VERSION ""

NS_ :

BS_:

BU_: LED_Driver ISC

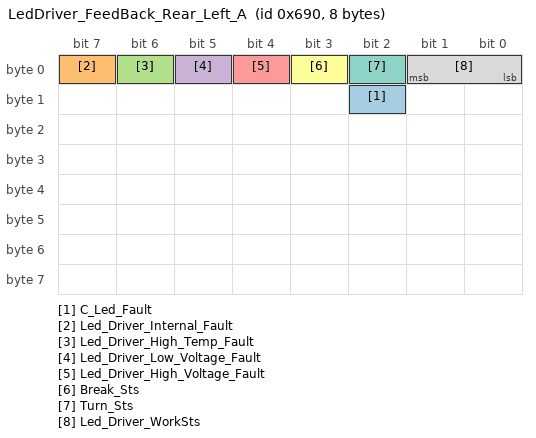
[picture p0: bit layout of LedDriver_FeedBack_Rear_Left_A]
BO_ 1680 LedDriver_FeedBack_Rear_Left_A: 8 LED_Driver
 SG_ C_Led_Fault : 10|1@1+ (1,0) [0|1] "" Vector__XXX
 SG_ Led_Driver_Internal_Fault : 7|1@1+ (1,0) [0|1] "" Vector__XXX
 SG_ Led_Driver_High_Temp_Fault : 6|1@1+ (1,0) [0|1] "" Vector__XXX
 SG_ Led_Driver_Low_Voltage_Fault : 5|1@1+ (1,0) [0|1] "" Vector__XXX
 SG_ Led_Driver_High_Voltage_Fault : 4|1@1+ (1,0) [0|1] "" Vector__XXX
 SG_ Break_Sts : 3|1@1+ (1,0) [0|1] "" Vector__XXX
 SG_ Turn_Sts : 2|1@1+ (1,0) [0|1] "" Vector__XXX
 SG_ Led_Driver_WorkSts : 0|2@1+ (1,0) [0|3] "" Vector__XXX

BO_ 1285 ISC_Ctrl_Right_LED_A_05: 64 ISC
 SG_ Led0043_value : 336|8@1+ (1,0) [0|255] "" Vector__XXX
 SG_ Led0042_value : 328|8@1+ (1,0) [0|255] "" Vector__XXX
 SG_ Led0041_value : 320|8@1+ (1,0) [0|255] "" Vector__XXX
 SG_ Led0040_value : 312|8@1+ (1,0) [0|255] "" Vector__XXX
 SG_ Led0039_value : 304|8@1+ (1,0) [0|255] "" Vector__XXX
 SG_ Led0038_value : 296|8@1+ (1,0) [0|255] "" Vector__XXX
 SG_ Led0037_value : 288|8@1+ (1,0) [0|255] "" Vector__XXX
 SG_ Led0036_value : 280|8@1+ (1,0) [0|255] "" Vector__XXX
 SG_ Led0035_value : 272|8@1+ (1,0) [0|255] "" Vector__XXX
 SG_ Led0034_value : 264|8@1+ (1,0) [0|255] "" Vector__XXX
 SG_ Led0033_value : 256|8@1+ (1,0) [0|255] "" Vector__XXX
 SG_ Led0032_value : 248|8@1+ (1,0) [0|255] "" Vector__XXX
 SG_ Led0031_value : 240|8@1+ (1,0) [0|255] "" Vector__XXX
 SG_ Led0030_value : 232|8@1+ (1,0) [0|255] "" Vector__XXX
 SG_ Led0029_value : 224|8@1+ (1,0) [0|255] "" Vector__XXX
 SG_ Led0028_value : 216|8@1+ (1,0) [0|255] "" Vector__XXX
 SG_ Led0027_value : 208|8@1+ (1,0) [0|255] "" Vector__XXX
 SG_ Led0026_value : 200|8@1+ (1,0) [0|255] "" Vector__XXX
 SG_ Led0025_value : 192|8@1+ (1,0) [0|255] "" Vector__XXX
 SG_ Led0024_value : 184|8@1+ (1,0) [0|255] "" Vector__XXX
 SG_ Led0023_value : 176|8@1+ (1,0) [0|255] "" Vector__XXX
 SG_ Led0022_value : 168|8@1+ (1,0) [0|255] "" Vector__XXX
 SG_ Led0021_value : 160|8@1+ (1,0) [0|255] "" Vector__XXX
 SG_ Led0020_value : 152|8@1+ (1,0) [0|255] "" Vector__XXX
 SG_ Led0019_value : 144|8@1+ (1,0) [0|255] "" Vector__XXX
 SG_ Led0018_value : 136|8@1+ (1,0) [0|255] "" Vector__XXX
 SG_ Led0017_value : 128|8@1+ (1,0) [0|255] "" Vector__XXX
 SG_ Led0016_value : 120|8@1+ (1,0) [0|255] "" Vector__XXX
 SG_ Led0015_value : 112|8@1+ (1,0) [0|255] "" Vector__XXX
 SG_ Led0014_value : 104|8@1+ (1,0) [0|255] "" Vector__XXX
 SG_ Led0013_value : 96|8@1+ (1,0) [0|255] "" Vector__XXX
 SG_ Led0012_value : 88|8@1+ (1,0) [0|255] "" Vector__XXX
 SG_ Led0011_value : 80|8@1+ (1,0) [0|255] "" Vector__XXX
 SG_ Led0010_value : 72|8@1+ (1,0) [0|255] "" Vector__XXX
 SG_ Led0009_value : 64|8@1+ (1,0) [0|255] "" Vector__XXX
 SG_ Led0008_value : 56|8@1+ (1,0) [0|255] "" Vector__XXX
 SG_ Led0007_value : 48|8@1+ (1,0) [0|255] "" Vector__XXX
 SG_ Led0006_value : 40|8@1+ (1,0) [0|255] "" Vector__XXX
 SG_ Led0005_value : 32|8@1+ (1,0) [0|255] "" Vector__XXX
 SG_ Led0004_value : 24|8@1+ (1,0) [0|255] "" Vector__XXX
 SG_ Led0003_value : 16|8@1+ (1,0) [0|255] "" Vector__XXX
 SG_ Led0002_value : 8|8@1+ (1,0) [0|255] "" Vector__XXX
 SG_ Led0001_value : 0|8@1+ (1,0) [0|255] "" Vector__XXX

BO_ 1284 ISC_Ctrl_Right_LED_A_04: 64 ISC
 SG_ Led0064_value : 504|8@1+ (1,0) [0|255] "" Vector__XXX
 SG_ Led0063_value : 496|8@1+ (1,0) [0|255] "" Vector__XXX
 SG_ Led0062_value : 488|8@1+ (1,0) [0|255] "" Vector__XXX
 SG_ Led0061_value : 480|8@1+ (1,0) [0|255] "" Vector__XXX
 SG_ Led0060_value : 472|8@1+ (1,0) [0|255] "" Vector__XXX
 SG_ Led0059_value : 464|8@1+ (1,0) [0|255] "" Vector__XXX
 SG_ Led0058_value : 456|8@1+ (1,0) [0|255] "" Vector__XXX
 SG_ Led0057_value : 448|8@1+ (1,0) [0|255] "" Vector__XXX
 SG_ Led0056_value : 440|8@1+ (1,0) [0|255] "" Vector__XXX
 SG_ Led0055_value : 432|8@1+ (1,0) [0|255] "" Vector__XXX
 SG_ Led0054_value : 424|8@1+ (1,0) [0|255] "" Vector__XXX
 SG_ Led0053_value : 416|8@1+ (1,0) [0|255] "" Vector__XXX
 SG_ Led0052_value : 408|8@1+ (1,0) [0|255] "" Vector__XXX
 SG_ Led0051_value : 400|8@1+ (1,0) [0|255] "" Vector__XXX
 SG_ Led0050_value : 392|8@1+ (1,0) [0|255] "" Vector__XXX
 SG_ Led0049_value : 384|8@1+ (1,0) [0|255] "" Vector__XXX
 SG_ Led0048_value : 376|8@1+ (1,0) [0|255] "" Vector__XXX
 SG_ Led0047_value : 368|8@1+ (1,0) [0|255] "" Vector__XXX
 SG_ Led0046_value : 360|8@1+ (1,0) [0|255] "" Vector__XXX
 SG_ Led0045_value : 352|8@1+ (1,0) [0|255] "" Vector__XXX
 SG_ Led0044_value : 344|8@1+ (1,0) [0|255] "" Vector__XXX
 SG_ Led0043_value : 336|8@1+ (1,0) [0|255] "" Vector__XXX
 SG_ Led0042_value : 328|8@1+ (1,0) [0|255] "" Vector__XXX
 SG_ Led0041_value : 320|8@1+ (1,0) [0|255] "" Vector__XXX
 SG_ Led0040_value : 312|8@1+ (1,0) [0|255] "" Vector__XXX
 SG_ Led0039_value : 304|8@1+ (1,0) [0|255] "" Vector__XXX
 SG_ Led0038_value : 296|8@1+ (1,0) [0|255] "" Vector__XXX
 SG_ Led0037_value : 288|8@1+ (1,0) [0|255] "" Vector__XXX
 SG_ Led0036_value : 280|8@1+ (1,0) [0|255] "" Vector__XXX
 SG_ Led0035_value : 272|8@1+ (1,0) [0|255] "" Vector__XXX
 SG_ Led0034_value : 264|8@1+ (1,0) [0|255] "" Vector__XXX
 SG_ Led0033_value : 256|8@1+ (1,0) [0|255] "" Vector__XXX
 SG_ Led0032_value : 248|8@1+ (1,0) [0|255] "" Vector__XXX
 SG_ Led0031_value : 240|8@1+ (1,0) [0|255] "" Vector__XXX
 SG_ Led0030_value : 232|8@1+ (1,0) [0|255] "" Vector__XXX
 SG_ Led0029_value : 224|8@1+ (1,0) [0|255] "" Vector__XXX
 SG_ Led0028_value : 216|8@1+ (1,0) [0|255] "" Vector__XXX
 SG_ Led0027_value : 208|8@1+ (1,0) [0|255] "" Vector__XXX
 SG_ Led0026_value : 200|8@1+ (1,0) [0|255] "" Vector__XXX
 SG_ Led0025_value : 192|8@1+ (1,0) [0|255] "" Vector__XXX
 SG_ Led0024_value : 184|8@1+ (1,0) [0|255] "" Vector__XXX
 SG_ Led0023_value : 176|8@1+ (1,0) [0|255] "" Vector__XXX
 SG_ Led0022_value : 168|8@1+ (1,0) [0|255] "" Vector__XXX
 SG_ Led0021_value : 160|8@1+ (1,0) [0|255] "" Vector__XXX
 SG_ Led0020_value : 152|8@1+ (1,0) [0|255] "" Vector__XXX
 SG_ Led0019_value : 144|8@1+ (1,0) [0|255] "" Vector__XXX
 SG_ Led0018_value : 136|8@1+ (1,0) [0|255] "" Vector__XXX
 SG_ Led0017_value : 128|8@1+ (1,0) [0|255] "" Vector__XXX
 SG_ Led0016_value : 120|8@1+ (1,0) [0|255] "" Vector__XXX
 SG_ Led0015_value : 112|8@1+ (1,0) [0|255] "" Vector__XXX
 SG_ Led0014_value : 104|8@1+ (1,0) [0|255] "" Vector__XXX
 SG_ Led0013_value : 96|8@1+ (1,0) [0|255] "" Vector__XXX
 SG_ Led0012_value : 88|8@1+ (1,0) [0|255] "" Vector__XXX
 SG_ Led0011_value : 80|8@1+ (1,0) [0|255] "" Vector__XXX
 SG_ Led0010_value : 72|8@1+ (1,0) [0|255] "" Vector__XXX
 SG_ Led0009_value : 64|8@1+ (1,0) [0|255] "" Vector__XXX
 SG_ Led0008_value : 56|8@1+ (1,0) [0|255] "" Vector__XXX
 SG_ Led0007_value : 48|8@1+ (1,0) [0|255] "" Vector__XXX
 SG_ Led0006_value : 40|8@1+ (1,0) [0|255] "" Vector__XXX
 SG_ Led0005_value : 32|8@1+ (1,0) [0|255] "" Vector__XXX
 SG_ Led0004_value : 24|8@1+ (1,0) [0|255] "" Vector__XXX
 SG_ Led0003_value : 16|8@1+ (1,0) [0|255] "" Vector__XXX
 SG_ Led0002_value : 8|8@1+ (1,0) [0|255] "" Vector__XXX
 SG_ Led0001_value : 0|8@1+ (1,0) [0|255] "" Vector__XXX

BO_ 1283 ISC_Ctrl_Right_LED_A_03: 64 ISC
 SG_ Led0064_value : 504|8@1+ (1,0) [0|255] "" Vector__XXX
 SG_ Led0063_value : 496|8@1+ (1,0) [0|255] "" Vector__XXX
 SG_ Led0062_value : 488|8@1+ (1,0) [0|255] "" Vector__XXX
 SG_ Led0061_value : 480|8@1+ (1,0) [0|255] "" Vector__XXX
 SG_ Led0060_value : 472|8@1+ (1,0) [0|255] "" Vector__XXX
 SG_ Led0059_value : 464|8@1+ (1,0) [0|255] "" Vector__XXX
 SG_ Led0058_value : 456|8@1+ (1,0) [0|255] "" Vector__XXX
 SG_ Led0057_value : 448|8@1+ (1,0) [0|255] "" Vector__XXX
 SG_ Led0056_value : 440|8@1+ (1,0) [0|255] "" Vector__XXX
 SG_ Led0055_value : 432|8@1+ (1,0) [0|255] "" Vector__XXX
 SG_ Led0054_value : 424|8@1+ (1,0) [0|255] "" Vector__XXX
 SG_ Led0053_value : 416|8@1+ (1,0) [0|255] "" Vector__XXX
 SG_ Led0052_value : 408|8@1+ (1,0) [0|255] "" Vector__XXX
 SG_ Led0051_value : 400|8@1+ (1,0) [0|255] "" Vector__XXX
 SG_ Led0050_value : 392|8@1+ (1,0) [0|255] "" Vector__XXX
 SG_ Led0049_value : 384|8@1+ (1,0) [0|255] "" Vector__XXX
 SG_ Led0048_value : 376|8@1+ (1,0) [0|255] "" Vector__XXX
 SG_ Led0047_value : 368|8@1+ (1,0) [0|255] "" Vector__XXX
 SG_ Led0046_value : 360|8@1+ (1,0) [0|255] "" Vector__XXX
 SG_ Led0045_value : 352|8@1+ (1,0) [0|255] "" Vector__XXX
 SG_ Led0044_value : 344|8@1+ (1,0) [0|255] "" Vector__XXX
 SG_ Led0043_value : 336|8@1+ (1,0) [0|255] "" Vector__XXX
 SG_ Led0042_value : 328|8@1+ (1,0) [0|255] "" Vector__XXX
 SG_ Led0041_value : 320|8@1+ (1,0) [0|255] "" Vector__XXX
 SG_ Led0040_value : 312|8@1+ (1,0) [0|255] "" Vector__XXX
 SG_ Led0039_value : 304|8@1+ (1,0) [0|255] "" Vector__XXX
 SG_ Led0038_value : 296|8@1+ (1,0) [0|255] "" Vector__XXX
 SG_ Led0037_value : 288|8@1+ (1,0) [0|255] "" Vector__XXX
 SG_ Led0036_value : 280|8@1+ (1,0) [0|255] "" Vector__XXX
 SG_ Led0035_value : 272|8@1+ (1,0) [0|255] "" Vector__XXX
 SG_ Led0034_value : 264|8@1+ (1,0) [0|255] "" Vector__XXX
 SG_ Led0033_value : 256|8@1+ (1,0) [0|255] "" Vector__XXX
 SG_ Led0032_value : 248|8@1+ (1,0) [0|255] "" Vector__XXX
 SG_ Led0031_value : 240|8@1+ (1,0) [0|255] "" Vector__XXX
 SG_ Led0030_value : 232|8@1+ (1,0) [0|255] "" Vector__XXX
 SG_ Led0029_value : 224|8@1+ (1,0) [0|255] "" Vector__XXX
 SG_ Led0028_value : 216|8@1+ (1,0) [0|255] "" Vector__XXX
 SG_ Led0027_value : 208|8@1+ (1,0) [0|255] "" Vector__XXX
 SG_ Led0026_value : 200|8@1+ (1,0) [0|255] "" Vector__XXX
 SG_ Led0025_value : 192|8@1+ (1,0) [0|255] "" Vector__XXX
 SG_ Led0024_value : 184|8@1+ (1,0) [0|255] "" Vector__XXX
 SG_ Led0023_value : 176|8@1+ (1,0) [0|255] "" Vector__XXX
 SG_ Led0022_value : 168|8@1+ (1,0) [0|255] "" Vector__XXX
 SG_ Led0021_value : 160|8@1+ (1,0) [0|255] "" Vector__XXX
 SG_ Led0020_value : 152|8@1+ (1,0) [0|255] "" Vector__XXX
 SG_ Led0019_value : 144|8@1+ (1,0) [0|255] "" Vector__XXX
 SG_ Led0018_value : 136|8@1+ (1,0) [0|255] "" Vector__XXX
 SG_ Led0017_value : 128|8@1+ (1,0) [0|255] "" Vector__XXX
 SG_ Led0016_value : 120|8@1+ (1,0) [0|255] "" Vector__XXX
 SG_ Led0015_value : 112|8@1+ (1,0) [0|255] "" Vector__XXX
 SG_ Led0014_value : 104|8@1+ (1,0) [0|255] "" Vector__XXX
 SG_ Led0013_value : 96|8@1+ (1,0) [0|255] "" Vector__XXX
 SG_ Led0012_value : 88|8@1+ (1,0) [0|255] "" Vector__XXX
 SG_ Led0011_value : 80|8@1+ (1,0) [0|255] "" Vector__XXX
 SG_ Led0010_value : 72|8@1+ (1,0) [0|255] "" Vector__XXX
 SG_ Led0009_value : 64|8@1+ (1,0) [0|255] "" Vector__XXX
 SG_ Led0008_value : 56|8@1+ (1,0) [0|255] "" Vector__XXX
 SG_ Led0007_value : 48|8@1+ (1,0) [0|255] "" Vector__XXX
 SG_ Led0006_value : 40|8@1+ (1,0) [0|255] "" Vector__XXX
 SG_ Led0005_value : 32|8@1+ (1,0) [0|255] "" Vector__XXX
 SG_ Led0004_value : 24|8@1+ (1,0) [0|255] "" Vector__XXX
 SG_ Led0003_value : 16|8@1+ (1,0) [0|255] "" Vector__XXX
 SG_ Led0002_value : 8|8@1+ (1,0) [0|255] "" Vector__XXX
 SG_ Led0001_value : 0|8@1+ (1,0) [0|255] "" Vector__XXX

BO_ 1282 ISC_Ctrl_Right_LED_A_02: 64 ISC
 SG_ Led0064_value : 504|8@1+ (1,0) [0|255] "" Vector__XXX
 SG_ Led0063_value : 496|8@1+ (1,0) [0|255] "" Vector__XXX
 SG_ Led0062_value : 488|8@1+ (1,0) [0|255] "" Vector__XXX
 SG_ Led0061_value : 480|8@1+ (1,0) [0|255] "" Vector__XXX
 SG_ Led0060_value : 472|8@1+ (1,0) [0|255] "" Vector__XXX
 SG_ Led0059_value : 464|8@1+ (1,0) [0|255] "" Vector__XXX
 SG_ Led0058_value : 456|8@1+ (1,0) [0|255] "" Vector__XXX
 SG_ Led0057_value : 448|8@1+ (1,0) [0|255] "" Vector__XXX
 SG_ Led0056_value : 440|8@1+ (1,0) [0|255] "" Vector__XXX
 SG_ Led0055_value : 432|8@1+ (1,0) [0|255] "" Vector__XXX
 SG_ Led0054_value : 424|8@1+ (1,0) [0|255] "" Vector__XXX
 SG_ Led0053_value : 416|8@1+ (1,0) [0|255] "" Vector__XXX
 SG_ Led0052_value : 408|8@1+ (1,0) [0|255] "" Vector__XXX
 SG_ Led0051_value : 400|8@1+ (1,0) [0|255] "" Vector__XXX
 SG_ Led0050_value : 392|8@1+ (1,0) [0|255] "" Vector__XXX
 SG_ Led0049_value : 384|8@1+ (1,0) [0|255] "" Vector__XXX
 SG_ Led0048_value : 376|8@1+ (1,0) [0|255] "" Vector__XXX
 SG_ Led0047_value : 368|8@1+ (1,0) [0|255] "" Vector__XXX
 SG_ Led0046_value : 360|8@1+ (1,0) [0|255] "" Vector__XXX
 SG_ Led0045_value : 352|8@1+ (1,0) [0|255] "" Vector__XXX
 SG_ Led0044_value : 344|8@1+ (1,0) [0|255] "" Vector__XXX
 SG_ Led0043_value : 336|8@1+ (1,0) [0|255] "" Vector__XXX
 SG_ Led0042_value : 328|8@1+ (1,0) [0|255] "" Vector__XXX
 SG_ Led0041_value : 320|8@1+ (1,0) [0|255] "" Vector__XXX
 SG_ Led0040_value : 312|8@1+ (1,0) [0|255] "" Vector__XXX
 SG_ Led0039_value : 304|8@1+ (1,0) [0|255] "" Vector__XXX
 SG_ Led0038_value : 296|8@1+ (1,0) [0|255] "" Vector__XXX
 SG_ Led0037_value : 288|8@1+ (1,0) [0|255] "" Vector__XXX
 SG_ Led0036_value : 280|8@1+ (1,0) [0|255] "" Vector__XXX
 SG_ Led0035_value : 272|8@1+ (1,0) [0|255] "" Vector__XXX
 SG_ Led0034_value : 264|8@1+ (1,0) [0|255] "" Vector__XXX
 SG_ Led0033_value : 256|8@1+ (1,0) [0|255] "" Vector__XXX
 SG_ Led0032_value : 248|8@1+ (1,0) [0|255] "" Vector__XXX
 SG_ Led0031_value : 240|8@1+ (1,0) [0|255] "" Vector__XXX
 SG_ Led0030_value : 232|8@1+ (1,0) [0|255] "" Vector__XXX
 SG_ Led0029_value : 224|8@1+ (1,0) [0|255] "" Vector__XXX
 SG_ Led0028_value : 216|8@1+ (1,0) [0|255] "" Vector__XXX
 SG_ Led0027_value : 208|8@1+ (1,0) [0|255] "" Vector__XXX
 SG_ Led0026_value : 200|8@1+ (1,0) [0|255] "" Vector__XXX
 SG_ Led0025_value : 192|8@1+ (1,0) [0|255] "" Vector__XXX
 SG_ Led0024_value : 184|8@1+ (1,0) [0|255] "" Vector__XXX
 SG_ Led0023_value : 176|8@1+ (1,0) [0|255] "" Vector__XXX
 SG_ Led0022_value : 168|8@1+ (1,0) [0|255] "" Vector__XXX
 SG_ Led0021_value : 160|8@1+ (1,0) [0|255] "" Vector__XXX
 SG_ Led0020_value : 152|8@1+ (1,0) [0|255] "" Vector__XXX
 SG_ Led0019_value : 144|8@1+ (1,0) [0|255] "" Vector__XXX
 SG_ Led0018_value : 136|8@1+ (1,0) [0|255] "" Vector__XXX
 SG_ Led0017_value : 128|8@1+ (1,0) [0|255] "" Vector__XXX
 SG_ Led0016_value : 120|8@1+ (1,0) [0|255] "" Vector__XXX
 SG_ Led0015_value : 112|8@1+ (1,0) [0|255] "" Vector__XXX
 SG_ Led0014_value : 104|8@1+ (1,0) [0|255] "" Vector__XXX
 SG_ Led0013_value : 96|8@1+ (1,0) [0|255] "" Vector__XXX
 SG_ Led0012_value : 88|8@1+ (1,0) [0|255] "" Vector__XXX
 SG_ Led0011_value : 80|8@1+ (1,0) [0|255] "" Vector__XXX
 SG_ Led0010_value : 72|8@1+ (1,0) [0|255] "" Vector__XXX
 SG_ Led0009_value : 64|8@1+ (1,0) [0|255] "" Vector__XXX
 SG_ Led0008_value : 56|8@1+ (1,0) [0|255] "" Vector__XXX
 SG_ Led0007_value : 48|8@1+ (1,0) [0|255] "" Vector__XXX
 SG_ Led0006_value : 40|8@1+ (1,0) [0|255] "" Vector__XXX
 SG_ Led0005_value : 32|8@1+ (1,0) [0|255] "" Vector__XXX
 SG_ Led0004_value : 24|8@1+ (1,0) [0|255] "" Vector__XXX
 SG_ Led0003_value : 16|8@1+ (1,0) [0|255] "" Vector__XXX
 SG_ Led0002_value : 8|8@1+ (1,0) [0|255] "" Vector__XXX
 SG_ Led0001_value : 0|8@1+ (1,0) [0|255] "" Vector__XXX

BO_ 1281 ISC_Ctrl_Right_LED_A_01: 64 ISC
 SG_ Led0064_value : 504|8@1+ (1,0) [0|255] "" Vector__XXX
 SG_ Led0063_value : 496|8@1+ (1,0) [0|255] "" Vector__XXX
 SG_ Led0062_value : 488|8@1+ (1,0) [0|255] "" Vector__XXX
 SG_ Led0061_value : 480|8@1+ (1,0) [0|255] "" Vector__XXX
 SG_ Led0060_value : 472|8@1+ (1,0) [0|255] "" Vector__XXX
 SG_ Led0059_value : 464|8@1+ (1,0) [0|255] "" Vector__XXX
 SG_ Led0058_value : 456|8@1+ (1,0) [0|255] "" Vector__XXX
 SG_ Led0057_value : 448|8@1+ (1,0) [0|255] "" Vector__XXX
 SG_ Led0056_value : 440|8@1+ (1,0) [0|255] "" Vector__XXX
 SG_ Led0055_value : 432|8@1+ (1,0) [0|255] "" Vector__XXX
 SG_ Led0054_value : 424|8@1+ (1,0) [0|255] "" Vector__XXX
 SG_ Led0053_value : 416|8@1+ (1,0) [0|255] "" Vector__XXX
 SG_ Led0052_value : 408|8@1+ (1,0) [0|255] "" Vector__XXX
 SG_ Led0051_value : 400|8@1+ (1,0) [0|255] "" Vector__XXX
 SG_ Led0050_value : 392|8@1+ (1,0) [0|255] "" Vector__XXX
 SG_ Led0049_value : 384|8@1+ (1,0) [0|255] "" Vector__XXX
 SG_ Led0048_value : 376|8@1+ (1,0) [0|255] "" Vector__XXX
 SG_ Led0047_value : 368|8@1+ (1,0) [0|255] "" Vector__XXX
 SG_ Led0046_value : 360|8@1+ (1,0) [0|255] "" Vector__XXX
 SG_ Led0045_value : 352|8@1+ (1,0) [0|255] "" Vector__XXX
 SG_ Led0044_value : 344|8@1+ (1,0) [0|255] "" Vector__XXX
 SG_ Led0043_value : 336|8@1+ (1,0) [0|255] "" Vector__XXX
 SG_ Led0042_value : 328|8@1+ (1,0) [0|255] "" Vector__XXX
 SG_ Led0041_value : 320|8@1+ (1,0) [0|255] "" Vector__XXX
 SG_ Led0040_value : 312|8@1+ (1,0) [0|255] "" Vector__XXX
 SG_ Led0039_value : 304|8@1+ (1,0) [0|255] "" Vector__XXX
 SG_ Led0038_value : 296|8@1+ (1,0) [0|255] "" Vector__XXX
 SG_ Led0037_value : 288|8@1+ (1,0) [0|255] "" Vector__XXX
 SG_ Led0036_value : 280|8@1+ (1,0) [0|255] "" Vector__XXX
 SG_ Led0035_value : 272|8@1+ (1,0) [0|255] "" Vector__XXX
 SG_ Led0034_value : 264|8@1+ (1,0) [0|255] "" Vector__XXX
 SG_ Led0033_value : 256|8@1+ (1,0) [0|255] "" Vector__XXX
 SG_ Led0032_value : 248|8@1+ (1,0) [0|255] "" Vector__XXX
 SG_ Led0031_value : 240|8@1+ (1,0) [0|255] "" Vector__XXX
 SG_ Led0030_value : 232|8@1+ (1,0) [0|255] "" Vector__XXX
 SG_ Led0029_value : 224|8@1+ (1,0) [0|255] "" Vector__XXX
 SG_ Led0028_value : 216|8@1+ (1,0) [0|255] "" Vector__XXX
 SG_ Led0027_value : 208|8@1+ (1,0) [0|255] "" Vector__XXX
 SG_ Led0026_value : 200|8@1+ (1,0) [0|255] "" Vector__XXX
 SG_ Led0025_value : 192|8@1+ (1,0) [0|255] "" Vector__XXX
 SG_ Led0024_value : 184|8@1+ (1,0) [0|255] "" Vector__XXX
 SG_ Led0023_value : 176|8@1+ (1,0) [0|255] "" Vector__XXX
 SG_ Led0022_value : 168|8@1+ (1,0) [0|255] "" Vector__XXX
 SG_ Led0021_value : 160|8@1+ (1,0) [0|255] "" Vector__XXX
 SG_ Led0020_value : 152|8@1+ (1,0) [0|255] "" Vector__XXX
 SG_ Led0019_value : 144|8@1+ (1,0) [0|255] "" Vector__XXX
 SG_ Led0018_value : 136|8@1+ (1,0) [0|255] "" Vector__XXX
 SG_ Led0017_value : 128|8@1+ (1,0) [0|255] "" Vector__XXX
 SG_ Led0016_value : 120|8@1+ (1,0) [0|255] "" Vector__XXX
 SG_ Led0015_value : 112|8@1+ (1,0) [0|255] "" Vector__XXX
 SG_ Led0014_value : 104|8@1+ (1,0) [0|255] "" Vector__XXX
 SG_ Led0013_value : 96|8@1+ (1,0) [0|255] "" Vector__XXX
 SG_ Led0012_value : 88|8@1+ (1,0) [0|255] "" Vector__XXX
 SG_ Led0011_value : 80|8@1+ (1,0) [0|255] "" Vector__XXX
 SG_ Led0010_value : 72|8@1+ (1,0) [0|255] "" Vector__XXX
 SG_ Led0009_value : 64|8@1+ (1,0) [0|255] "" Vector__XXX
 SG_ Led0008_value : 56|8@1+ (1,0) [0|255] "" Vector__XXX
 SG_ Led0007_value : 48|8@1+ (1,0) [0|255] "" Vector__XXX
 SG_ Led0006_value : 40|8@1+ (1,0) [0|255] "" Vector__XXX
 SG_ Led0005_value : 32|8@1+ (1,0) [0|255] "" Vector__XXX
 SG_ Led0004_value : 24|8@1+ (1,0) [0|255] "" Vector__XXX
 SG_ Led0003_value : 16|8@1+ (1,0) [0|255] "" Vector__XXX
 SG_ Led0002_value : 8|8@1+ (1,0) [0|255] "" Vector__XXX
 SG_ Led0001_value : 0|8@1+ (1,0) [0|255] "" Vector__XXX

BO_ 1063 ISC_Ctrl_LED_B_39: 64 ISC
 SG_ Led0031_value : 240|8@1+ (1,0) [0|255] "" Vector__XXX
 SG_ Led0030_value : 232|8@1+ (1,0) [0|255] "" Vector__XXX
 SG_ Led0029_value : 224|8@1+ (1,0) [0|255] "" Vector__XXX
 SG_ Led0028_value : 216|8@1+ (1,0) [0|255] "" Vector__XXX
 SG_ Led0027_value : 208|8@1+ (1,0) [0|255] "" Vector__XXX
 SG_ Led0026_value : 200|8@1+ (1,0) [0|255] "" Vector__XXX
 SG_ Led0025_value : 192|8@1+ (1,0) [0|255] "" Vector__XXX
 SG_ Led0024_value : 184|8@1+ (1,0) [0|255] "" Vector__XXX
 SG_ Led0023_value : 176|8@1+ (1,0) [0|255] "" Vector__XXX
 SG_ Led0022_value : 168|8@1+ (1,0) [0|255] "" Vector__XXX
 SG_ Led0021_value : 160|8@1+ (1,0) [0|255] "" Vector__XXX
 SG_ Led0020_value : 152|8@1+ (1,0) [0|255] "" Vector__XXX
 SG_ Led0019_value : 144|8@1+ (1,0) [0|255] "" Vector__XXX
 SG_ Led0018_value : 136|8@1+ (1,0) [0|255] "" Vector__XXX
 SG_ Led0017_value : 128|8@1+ (1,0) [0|255] "" Vector__XXX
 SG_ Led0016_value : 120|8@1+ (1,0) [0|255] "" Vector__XXX
 SG_ Led0015_value : 112|8@1+ (1,0) [0|255] "" Vector__XXX
 SG_ Led0014_value : 104|8@1+ (1,0) [0|255] "" Vector__XXX
 SG_ Led0013_value : 96|8@1+ (1,0) [0|255] "" Vector__XXX
 SG_ Led0012_value : 88|8@1+ (1,0) [0|255] "" Vector__XXX
 SG_ Led0011_value : 80|8@1+ (1,0) [0|255] "" Vector__XXX
 SG_ Led0010_value : 72|8@1+ (1,0) [0|255] "" Vector__XXX
 SG_ Led0009_value : 64|8@1+ (1,0) [0|255] "" Vector__XXX
 SG_ Led0008_value : 56|8@1+ (1,0) [0|255] "" Vector__XXX
 SG_ Led0007_value : 48|8@1+ (1,0) [0|255] "" Vector__XXX
 SG_ Led0006_value : 40|8@1+ (1,0) [0|255] "" Vector__XXX
 SG_ Led0005_value : 32|8@1+ (1,0) [0|255] "" Vector__XXX
 SG_ Led0004_value : 24|8@1+ (1,0) [0|255] "" Vector__XXX
 SG_ Led0003_value : 16|8@1+ (1,0) [0|255] "" Vector__XXX
 SG_ Led0002_value : 8|8@1+ (1,0) [0|255] "" Vector__XXX
 SG_ Led0001_value : 0|8@1+ (1,0) [0|255] "" Vector__XXX

BO_ 1062 ISC_Ctrl_LED_B_38: 64 ISC
 SG_ Led0064_value : 504|8@1+ (1,0) [0|255] "" Vector__XXX
 SG_ Led0063_value : 496|8@1+ (1,0) [0|255] "" Vector__XXX
 SG_ Led0062_value : 488|8@1+ (1,0) [0|255] "" Vector__XXX
 SG_ Led0061_value : 480|8@1+ (1,0) [0|255] "" Vector__XXX
 SG_ Led0060_value : 472|8@1+ (1,0) [0|255] "" Vector__XXX
 SG_ Led0059_value : 464|8@1+ (1,0) [0|255] "" Vector__XXX
 SG_ Led0058_value : 456|8@1+ (1,0) [0|255] "" Vector__XXX
 SG_ Led0057_value : 448|8@1+ (1,0) [0|255] "" Vector__XXX
 SG_ Led0056_value : 440|8@1+ (1,0) [0|255] "" Vector__XXX
 SG_ Led0055_value : 432|8@1+ (1,0) [0|255] "" Vector__XXX
 SG_ Led0054_value : 424|8@1+ (1,0) [0|255] "" Vector__XXX
 SG_ Led0053_value : 416|8@1+ (1,0) [0|255] "" Vector__XXX
 SG_ Led0052_value : 408|8@1+ (1,0) [0|255] "" Vector__XXX
 SG_ Led0051_value : 400|8@1+ (1,0) [0|255] "" Vector__XXX
 SG_ Led0050_value : 392|8@1+ (1,0) [0|255] "" Vector__XXX
 SG_ Led0049_value : 384|8@1+ (1,0) [0|255] "" Vector__XXX
 SG_ Led0048_value : 376|8@1+ (1,0) [0|255] "" Vector__XXX
 SG_ Led0047_value : 368|8@1+ (1,0) [0|255] "" Vector__XXX
 SG_ Led0046_value : 360|8@1+ (1,0) [0|255] "" Vector__XXX
 SG_ Led0045_value : 352|8@1+ (1,0) [0|255] "" Vector__XXX
 SG_ Led0044_value : 344|8@1+ (1,0) [0|255] "" Vector__XXX
 SG_ Led0043_value : 336|8@1+ (1,0) [0|255] "" Vector__XXX
 SG_ Led0042_value : 328|8@1+ (1,0) [0|255] "" Vector__XXX
 SG_ Led0041_value : 320|8@1+ (1,0) [0|255] "" Vector__XXX
 SG_ Led0040_value : 312|8@1+ (1,0) [0|255] "" Vector__XXX
 SG_ Led0039_value : 304|8@1+ (1,0) [0|255] "" Vector__XXX
 SG_ Led0038_value : 296|8@1+ (1,0) [0|255] "" Vector__XXX
 SG_ Led0037_value : 288|8@1+ (1,0) [0|255] "" Vector__XXX
 SG_ Led0036_value : 280|8@1+ (1,0) [0|255] "" Vector__XXX
 SG_ Led0035_value : 272|8@1+ (1,0) [0|255] "" Vector__XXX
 SG_ Led0034_value : 264|8@1+ (1,0) [0|255] "" Vector__XXX
 SG_ Led0033_value : 256|8@1+ (1,0) [0|255] "" Vector__XXX
 SG_ Led0032_value : 248|8@1+ (1,0) [0|255] "" Vector__XXX
 SG_ Led0031_value : 240|8@1+ (1,0) [0|255] "" Vector__XXX
 SG_ Led0030_value : 232|8@1+ (1,0) [0|255] "" Vector__XXX
 SG_ Led0029_value : 224|8@1+ (1,0) [0|255] "" Vector__XXX
 SG_ Led0028_value : 216|8@1+ (1,0) [0|255] "" Vector__XXX
 SG_ Led0027_value : 208|8@1+ (1,0) [0|255] "" Vector__XXX
 SG_ Led0026_value : 200|8@1+ (1,0) [0|255] "" Vector__XXX
 SG_ Led0025_value : 192|8@1+ (1,0) [0|255] "" Vector__XXX
 SG_ Led0024_value : 184|8@1+ (1,0) [0|255] "" Vector__XXX
 SG_ Led0023_value : 176|8@1+ (1,0) [0|255] "" Vector__XXX
 SG_ Led0022_value : 168|8@1+ (1,0) [0|255] "" Vector__XXX
 SG_ Led0021_value : 160|8@1+ (1,0) [0|255] "" Vector__XXX
 SG_ Led0020_value : 152|8@1+ (1,0) [0|255] "" Vector__XXX
 SG_ Led0019_value : 144|8@1+ (1,0) [0|255] "" Vector__XXX
 SG_ Led0018_value : 136|8@1+ (1,0) [0|255] "" Vector__XXX
 SG_ Led0017_value : 128|8@1+ (1,0) [0|255] "" Vector__XXX
 SG_ Led0016_value : 120|8@1+ (1,0) [0|255] "" Vector__XXX
 SG_ Led0015_value : 112|8@1+ (1,0) [0|255] "" Vector__XXX
 SG_ Led0014_value : 104|8@1+ (1,0) [0|255] "" Vector__XXX
 SG_ Led0013_value : 96|8@1+ (1,0) [0|255] "" Vector__XXX
 SG_ Led0012_value : 88|8@1+ (1,0) [0|255] "" Vector__XXX
 SG_ Led0011_value : 80|8@1+ (1,0) [0|255] "" Vector__XXX
 SG_ Led0010_value : 72|8@1+ (1,0) [0|255] "" Vector__XXX
 SG_ Led0009_value : 64|8@1+ (1,0) [0|255] "" Vector__XXX
 SG_ Led0008_value : 56|8@1+ (1,0) [0|255] "" Vector__XXX
 SG_ Led0007_value : 48|8@1+ (1,0) [0|255] "" Vector__XXX
 SG_ Led0006_value : 40|8@1+ (1,0) [0|255] "" Vector__XXX
 SG_ Led0005_value : 32|8@1+ (1,0) [0|255] "" Vector__XXX
 SG_ Led0004_value : 24|8@1+ (1,0) [0|255] "" Vector__XXX
 SG_ Led0003_value : 16|8@1+ (1,0) [0|255] "" Vector__XXX
 SG_ Led0002_value : 8|8@1+ (1,0) [0|255] "" Vector__XXX
 SG_ Led0001_value : 0|8@1+ (1,0) [0|255] "" Vector__XXX

BO_ 1061 ISC_Ctrl_LED_B_37: 64 ISC
 SG_ Led0064_value : 504|8@1+ (1,0) [0|255] "" Vector__XXX
 SG_ Led0063_value : 496|8@1+ (1,0) [0|255] "" Vector__XXX
 SG_ Led0062_value : 488|8@1+ (1,0) [0|255] "" Vector__XXX
 SG_ Led0061_value : 480|8@1+ (1,0) [0|255] "" Vector__XXX
 SG_ Led0060_value : 472|8@1+ (1,0) [0|255] "" Vector__XXX
 SG_ Led0059_value : 464|8@1+ (1,0) [0|255] "" Vector__XXX
 SG_ Led0058_value : 456|8@1+ (1,0) [0|255] "" Vector__XXX
 SG_ Led0057_value : 448|8@1+ (1,0) [0|255] "" Vector__XXX
 SG_ Led0056_value : 440|8@1+ (1,0) [0|255] "" Vector__XXX
 SG_ Led0055_value : 432|8@1+ (1,0) [0|255] "" Vector__XXX
 SG_ Led0054_value : 424|8@1+ (1,0) [0|255] "" Vector__XXX
 SG_ Led0053_value : 416|8@1+ (1,0) [0|255] "" Vector__XXX
 SG_ Led0052_value : 408|8@1+ (1,0) [0|255] "" Vector__XXX
 SG_ Led0051_value : 400|8@1+ (1,0) [0|255] "" Vector__XXX
 SG_ Led0050_value : 392|8@1+ (1,0) [0|255] "" Vector__XXX
 SG_ Led0049_value : 384|8@1+ (1,0) [0|255] "" Vector__XXX
 SG_ Led0048_value : 376|8@1+ (1,0) [0|255] "" Vector__XXX
 SG_ Led0047_value : 368|8@1+ (1,0) [0|255] "" Vector__XXX
 SG_ Led0046_value : 360|8@1+ (1,0) [0|255] "" Vector__XXX
 SG_ Led0045_value : 352|8@1+ (1,0) [0|255] "" Vector__XXX
 SG_ Led0044_value : 344|8@1+ (1,0) [0|255] "" Vector__XXX
 SG_ Led0043_value : 336|8@1+ (1,0) [0|255] "" Vector__XXX
 SG_ Led0042_value : 328|8@1+ (1,0) [0|255] "" Vector__XXX
 SG_ Led0041_value : 320|8@1+ (1,0) [0|255] "" Vector__XXX
 SG_ Led0040_value : 312|8@1+ (1,0) [0|255] "" Vector__XXX
 SG_ Led0039_value : 304|8@1+ (1,0) [0|255] "" Vector__XXX
 SG_ Led0038_value : 296|8@1+ (1,0) [0|255] "" Vector__XXX
 SG_ Led0037_value : 288|8@1+ (1,0) [0|255] "" Vector__XXX
 SG_ Led0036_value : 280|8@1+ (1,0) [0|255] "" Vector__XXX
 SG_ Led0035_value : 272|8@1+ (1,0) [0|255] "" Vector__XXX
 SG_ Led0034_value : 264|8@1+ (1,0) [0|255] "" Vector__XXX
 SG_ Led0033_value : 256|8@1+ (1,0) [0|255] "" Vector__XXX
 SG_ Led0032_value : 248|8@1+ (1,0) [0|255] "" Vector__XXX
 SG_ Led0031_value : 240|8@1+ (1,0) [0|255] "" Vector__XXX
 SG_ Led0030_value : 232|8@1+ (1,0) [0|255] "" Vector__XXX
 SG_ Led0029_value : 224|8@1+ (1,0) [0|255] "" Vector__XXX
 SG_ Led0028_value : 216|8@1+ (1,0) [0|255] "" Vector__XXX
 SG_ Led0027_value : 208|8@1+ (1,0) [0|255] "" Vector__XXX
 SG_ Led0026_value : 200|8@1+ (1,0) [0|255] "" Vector__XXX
 SG_ Led0025_value : 192|8@1+ (1,0) [0|255] "" Vector__XXX
 SG_ Led0024_value : 184|8@1+ (1,0) [0|255] "" Vector__XXX
 SG_ Led0023_value : 176|8@1+ (1,0) [0|255] "" Vector__XXX
 SG_ Led0022_value : 168|8@1+ (1,0) [0|255] "" Vector__XXX
 SG_ Led0021_value : 160|8@1+ (1,0) [0|255] "" Vector__XXX
 SG_ Led0020_value : 152|8@1+ (1,0) [0|255] "" Vector__XXX
 SG_ Led0019_value : 144|8@1+ (1,0) [0|255] "" Vector__XXX
 SG_ Led0018_value : 136|8@1+ (1,0) [0|255] "" Vector__XXX
 SG_ Led0017_value : 128|8@1+ (1,0) [0|255] "" Vector__XXX
 SG_ Led0016_value : 120|8@1+ (1,0) [0|255] "" Vector__XXX
 SG_ Led0015_value : 112|8@1+ (1,0) [0|255] "" Vector__XXX
 SG_ Led0014_value : 104|8@1+ (1,0) [0|255] "" Vector__XXX
 SG_ Led0013_value : 96|8@1+ (1,0) [0|255] "" Vector__XXX
 SG_ Led0012_value : 88|8@1+ (1,0) [0|255] "" Vector__XXX
 SG_ Led0011_value : 80|8@1+ (1,0) [0|255] "" Vector__XXX
 SG_ Led0010_value : 72|8@1+ (1,0) [0|255] "" Vector__XXX
 SG_ Led0009_value : 64|8@1+ (1,0) [0|255] "" Vector__XXX
 SG_ Led0008_value : 56|8@1+ (1,0) [0|255] "" Vector__XXX
 SG_ Led0007_value : 48|8@1+ (1,0) [0|255] "" Vector__XXX
 SG_ Led0006_value : 40|8@1+ (1,0) [0|255] "" Vector__XXX
 SG_ Led0005_value : 32|8@1+ (1,0) [0|255] "" Vector__XXX
 SG_ Led0004_value : 24|8@1+ (1,0) [0|255] "" Vector__XXX
 SG_ Led0003_value : 16|8@1+ (1,0) [0|255] "" Vector__XXX
 SG_ Led0002_value : 8|8@1+ (1,0) [0|255] "" Vector__XXX
 SG_ Led0001_value : 0|8@1+ (1,0) [0|255] "" Vector__XXX

BO_ 1060 ISC_Ctrl_LED_B_36: 64 ISC
 SG_ Led0064_value : 504|8@1+ (1,0) [0|255] "" Vector__XXX
 SG_ Led0063_value : 496|8@1+ (1,0) [0|255] "" Vector__XXX
 SG_ Led0062_value : 488|8@1+ (1,0) [0|255] "" Vector__XXX
 SG_ Led0061_value : 480|8@1+ (1,0) [0|255] "" Vector__XXX
 SG_ Led0060_value : 472|8@1+ (1,0) [0|255] "" Vector__XXX
 SG_ Led0059_value : 464|8@1+ (1,0) [0|255] "" Vector__XXX
 SG_ Led0058_value : 456|8@1+ (1,0) [0|255] "" Vector__XXX
 SG_ Led0057_value : 448|8@1+ (1,0) [0|255] "" Vector__XXX
 SG_ Led0056_value : 440|8@1+ (1,0) [0|255] "" Vector__XXX
 SG_ Led0055_value : 432|8@1+ (1,0) [0|255] "" Vector__XXX
 SG_ Led0054_value : 424|8@1+ (1,0) [0|255] "" Vector__XXX
 SG_ Led0053_value : 416|8@1+ (1,0) [0|255] "" Vector__XXX
 SG_ Led0052_value : 408|8@1+ (1,0) [0|255] "" Vector__XXX
 SG_ Led0051_value : 400|8@1+ (1,0) [0|255] "" Vector__XXX
 SG_ Led0050_value : 392|8@1+ (1,0) [0|255] "" Vector__XXX
 SG_ Led0049_value : 384|8@1+ (1,0) [0|255] "" Vector__XXX
 SG_ Led0048_value : 376|8@1+ (1,0) [0|255] "" Vector__XXX
 SG_ Led0047_value : 368|8@1+ (1,0) [0|255] "" Vector__XXX
 SG_ Led0046_value : 360|8@1+ (1,0) [0|255] "" Vector__XXX
 SG_ Led0045_value : 352|8@1+ (1,0) [0|255] "" Vector__XXX
 SG_ Led0044_value : 344|8@1+ (1,0) [0|255] "" Vector__XXX
 SG_ Led0043_value : 336|8@1+ (1,0) [0|255] "" Vector__XXX
 SG_ Led0042_value : 328|8@1+ (1,0) [0|255] "" Vector__XXX
 SG_ Led0041_value : 320|8@1+ (1,0) [0|255] "" Vector__XXX
 SG_ Led0040_value : 312|8@1+ (1,0) [0|255] "" Vector__XXX
 SG_ Led0039_value : 304|8@1+ (1,0) [0|255] "" Vector__XXX
 SG_ Led0038_value : 296|8@1+ (1,0) [0|255] "" Vector__XXX
 SG_ Led0037_value : 288|8@1+ (1,0) [0|255] "" Vector__XXX
 SG_ Led0036_value : 280|8@1+ (1,0) [0|255] "" Vector__XXX
 SG_ Led0035_value : 272|8@1+ (1,0) [0|255] "" Vector__XXX
 SG_ Led0034_value : 264|8@1+ (1,0) [0|255] "" Vector__XXX
 SG_ Led0033_value : 256|8@1+ (1,0) [0|255] "" Vector__XXX
 SG_ Led0032_value : 248|8@1+ (1,0) [0|255] "" Vector__XXX
 SG_ Led0031_value : 240|8@1+ (1,0) [0|255] "" Vector__XXX
 SG_ Led0030_value : 232|8@1+ (1,0) [0|255] "" Vector__XXX
 SG_ Led0029_value : 224|8@1+ (1,0) [0|255] "" Vector__XXX
 SG_ Led0028_value : 216|8@1+ (1,0) [0|255] "" Vector__XXX
 SG_ Led0027_value : 208|8@1+ (1,0) [0|255] "" Vector__XXX
 SG_ Led0026_value : 200|8@1+ (1,0) [0|255] "" Vector__XXX
 SG_ Led0025_value : 192|8@1+ (1,0) [0|255] "" Vector__XXX
 SG_ Led0024_value : 184|8@1+ (1,0) [0|255] "" Vector__XXX
 SG_ Led0023_value : 176|8@1+ (1,0) [0|255] "" Vector__XXX
 SG_ Led0022_value : 168|8@1+ (1,0) [0|255] "" Vector__XXX
 SG_ Led0021_value : 160|8@1+ (1,0) [0|255] "" Vector__XXX
 SG_ Led0020_value : 152|8@1+ (1,0) [0|255] "" Vector__XXX
 SG_ Led0019_value : 144|8@1+ (1,0) [0|255] "" Vector__XXX
 SG_ Led0018_value : 136|8@1+ (1,0) [0|255] "" Vector__XXX
 SG_ Led0017_value : 128|8@1+ (1,0) [0|255] "" Vector__XXX
 SG_ Led0016_value : 120|8@1+ (1,0) [0|255] "" Vector__XXX
 SG_ Led0015_value : 112|8@1+ (1,0) [0|255] "" Vector__XXX
 SG_ Led0014_value : 104|8@1+ (1,0) [0|255] "" Vector__XXX
 SG_ Led0013_value : 96|8@1+ (1,0) [0|255] "" Vector__XXX
 SG_ Led0012_value : 88|8@1+ (1,0) [0|255] "" Vector__XXX
 SG_ Led0011_value : 80|8@1+ (1,0) [0|255] "" Vector__XXX
 SG_ Led0010_value : 72|8@1+ (1,0) [0|255] "" Vector__XXX
 SG_ Led0009_value : 64|8@1+ (1,0) [0|255] "" Vector__XXX
 SG_ Led0008_value : 56|8@1+ (1,0) [0|255] "" Vector__XXX
 SG_ Led0007_value : 48|8@1+ (1,0) [0|255] "" Vector__XXX
 SG_ Led0006_value : 40|8@1+ (1,0) [0|255] "" Vector__XXX
 SG_ Led0005_value : 32|8@1+ (1,0) [0|255] "" Vector__XXX
 SG_ Led0004_value : 24|8@1+ (1,0) [0|255] "" Vector__XXX
 SG_ Led0003_value : 16|8@1+ (1,0) [0|255] "" Vector__XXX
 SG_ Led0002_value : 8|8@1+ (1,0) [0|255] "" Vector__XXX
 SG_ Led0001_value : 0|8@1+ (1,0) [0|255] "" Vector__XXX

BO_ 1059 ISC_Ctrl_LED_B_35: 64 ISC
 SG_ Led0064_value : 504|8@1+ (1,0) [0|255] "" Vector__XXX
 SG_ Led0063_value : 496|8@1+ (1,0) [0|255] "" Vector__XXX
 SG_ Led0062_value : 488|8@1+ (1,0) [0|255] "" Vector__XXX
 SG_ Led0061_value : 480|8@1+ (1,0) [0|255] "" Vector__XXX
 SG_ Led0060_value : 472|8@1+ (1,0) [0|255] "" Vector__XXX
 SG_ Led0059_value : 464|8@1+ (1,0) [0|255] "" Vector__XXX
 SG_ Led0058_value : 456|8@1+ (1,0) [0|255] "" Vector__XXX
 SG_ Led0057_value : 448|8@1+ (1,0) [0|255] "" Vector__XXX
 SG_ Led0056_value : 440|8@1+ (1,0) [0|255] "" Vector__XXX
 SG_ Led0055_value : 432|8@1+ (1,0) [0|255] "" Vector__XXX
 SG_ Led0054_value : 424|8@1+ (1,0) [0|255] "" Vector__XXX
 SG_ Led0053_value : 416|8@1+ (1,0) [0|255] "" Vector__XXX
 SG_ Led0052_value : 408|8@1+ (1,0) [0|255] "" Vector__XXX
 SG_ Led0051_value : 400|8@1+ (1,0) [0|255] "" Vector__XXX
 SG_ Led0050_value : 392|8@1+ (1,0) [0|255] "" Vector__XXX
 SG_ Led0049_value : 384|8@1+ (1,0) [0|255] "" Vector__XXX
 SG_ Led0048_value : 376|8@1+ (1,0) [0|255] "" Vector__XXX
 SG_ Led0047_value : 368|8@1+ (1,0) [0|255] "" Vector__XXX
 SG_ Led0046_value : 360|8@1+ (1,0) [0|255] "" Vector__XXX
 SG_ Led0045_value : 352|8@1+ (1,0) [0|255] "" Vector__XXX
 SG_ Led0044_value : 344|8@1+ (1,0) [0|255] "" Vector__XXX
 SG_ Led0043_value : 336|8@1+ (1,0) [0|255] "" Vector__XXX
 SG_ Led0042_value : 328|8@1+ (1,0) [0|255] "" Vector__XXX
 SG_ Led0041_value : 320|8@1+ (1,0) [0|255] "" Vector__XXX
 SG_ Led0040_value : 312|8@1+ (1,0) [0|255] "" Vector__XXX
 SG_ Led0039_value : 304|8@1+ (1,0) [0|255] "" Vector__XXX
 SG_ Led0038_value : 296|8@1+ (1,0) [0|255] "" Vector__XXX
 SG_ Led0037_value : 288|8@1+ (1,0) [0|255] "" Vector__XXX
 SG_ Led0036_value : 280|8@1+ (1,0) [0|255] "" Vector__XXX
 SG_ Led0035_value : 272|8@1+ (1,0) [0|255] "" Vector__XXX
 SG_ Led0034_value : 264|8@1+ (1,0) [0|255] "" Vector__XXX
 SG_ Led0033_value : 256|8@1+ (1,0) [0|255] "" Vector__XXX
 SG_ Led0032_value : 248|8@1+ (1,0) [0|255] "" Vector__XXX
 SG_ Led0031_value : 240|8@1+ (1,0) [0|255] "" Vector__XXX
 SG_ Led0030_value : 232|8@1+ (1,0) [0|255] "" Vector__XXX
 SG_ Led0029_value : 224|8@1+ (1,0) [0|255] "" Vector__XXX
 SG_ Led0028_value : 216|8@1+ (1,0) [0|255] "" Vector__XXX
 SG_ Led0027_value : 208|8@1+ (1,0) [0|255] "" Vector__XXX
 SG_ Led0026_value : 200|8@1+ (1,0) [0|255] "" Vector__XXX
 SG_ Led0025_value : 192|8@1+ (1,0) [0|255] "" Vector__XXX
 SG_ Led0024_value : 184|8@1+ (1,0) [0|255] "" Vector__XXX
 SG_ Led0023_value : 176|8@1+ (1,0) [0|255] "" Vector__XXX
 SG_ Led0022_value : 168|8@1+ (1,0) [0|255] "" Vector__XXX
 SG_ Led0021_value : 160|8@1+ (1,0) [0|255] "" Vector__XXX
 SG_ Led0020_value : 152|8@1+ (1,0) [0|255] "" Vector__XXX
 SG_ Led0019_value : 144|8@1+ (1,0) [0|255] "" Vector__XXX
 SG_ Led0018_value : 136|8@1+ (1,0) [0|255] "" Vector__XXX
 SG_ Led0017_value : 128|8@1+ (1,0) [0|255] "" Vector__XXX
 SG_ Led0016_value : 120|8@1+ (1,0) [0|255] "" Vector__XXX
 SG_ Led0015_value : 112|8@1+ (1,0) [0|255] "" Vector__XXX
 SG_ Led0014_value : 104|8@1+ (1,0) [0|255] "" Vector__XXX
 SG_ Led0013_value : 96|8@1+ (1,0) [0|255] "" Vector__XXX
 SG_ Led0012_value : 88|8@1+ (1,0) [0|255] "" Vector__XXX
 SG_ Led0011_value : 80|8@1+ (1,0) [0|255] "" Vector__XXX
 SG_ Led0010_value : 72|8@1+ (1,0) [0|255] "" Vector__XXX
 SG_ Led0009_value : 64|8@1+ (1,0) [0|255] "" Vector__XXX
 SG_ Led0008_value : 56|8@1+ (1,0) [0|255] "" Vector__XXX
 SG_ Led0007_value : 48|8@1+ (1,0) [0|255] "" Vector__XXX
 SG_ Led0006_value : 40|8@1+ (1,0) [0|255] "" Vector__XXX
 SG_ Led0005_value : 32|8@1+ (1,0) [0|255] "" Vector__XXX
 SG_ Led0004_value : 24|8@1+ (1,0) [0|255] "" Vector__XXX
 SG_ Led0003_value : 16|8@1+ (1,0) [0|255] "" Vector__XXX
 SG_ Led0002_value : 8|8@1+ (1,0) [0|255] "" Vector__XXX
 SG_ Led0001_value : 0|8@1+ (1,0) [0|255] "" Vector__XXX

BO_ 1058 ISC_Ctrl_LED_B_34: 64 ISC
 SG_ Led0064_value : 504|8@1+ (1,0) [0|255] "" Vector__XXX
 SG_ Led0063_value : 496|8@1+ (1,0) [0|255] "" Vector__XXX
 SG_ Led0062_value : 488|8@1+ (1,0) [0|255] "" Vector__XXX
 SG_ Led0061_value : 480|8@1+ (1,0) [0|255] "" Vector__XXX
 SG_ Led0060_value : 472|8@1+ (1,0) [0|255] "" Vector__XXX
 SG_ Led0059_value : 464|8@1+ (1,0) [0|255] "" Vector__XXX
 SG_ Led0058_value : 456|8@1+ (1,0) [0|255] "" Vector__XXX
 SG_ Led0057_value : 448|8@1+ (1,0) [0|255] "" Vector__XXX
 SG_ Led0056_value : 440|8@1+ (1,0) [0|255] "" Vector__XXX
 SG_ Led0055_value : 432|8@1+ (1,0) [0|255] "" Vector__XXX
 SG_ Led0054_value : 424|8@1+ (1,0) [0|255] "" Vector__XXX
 SG_ Led0053_value : 416|8@1+ (1,0) [0|255] "" Vector__XXX
 SG_ Led0052_value : 408|8@1+ (1,0) [0|255] "" Vector__XXX
 SG_ Led0051_value : 400|8@1+ (1,0) [0|255] "" Vector__XXX
 SG_ Led0050_value : 392|8@1+ (1,0) [0|255] "" Vector__XXX
 SG_ Led0049_value : 384|8@1+ (1,0) [0|255] "" Vector__XXX
 SG_ Led0048_value : 376|8@1+ (1,0) [0|255] "" Vector__XXX
 SG_ Led0047_value : 368|8@1+ (1,0) [0|255] "" Vector__XXX
 SG_ Led0046_value : 360|8@1+ (1,0) [0|255] "" Vector__XXX
 SG_ Led0045_value : 352|8@1+ (1,0) [0|255] "" Vector__XXX
 SG_ Led0044_value : 344|8@1+ (1,0) [0|255] "" Vector__XXX
 SG_ Led0043_value : 336|8@1+ (1,0) [0|255] "" Vector__XXX
 SG_ Led0042_value : 328|8@1+ (1,0) [0|255] "" Vector__XXX
 SG_ Led0041_value : 320|8@1+ (1,0) [0|255] "" Vector__XXX
 SG_ Led0040_value : 312|8@1+ (1,0) [0|255] "" Vector__XXX
 SG_ Led0039_value : 304|8@1+ (1,0) [0|255] "" Vector__XXX
 SG_ Led0038_value : 296|8@1+ (1,0) [0|255] "" Vector__XXX
 SG_ Led0037_value : 288|8@1+ (1,0) [0|255] "" Vector__XXX
 SG_ Led0036_value : 280|8@1+ (1,0) [0|255] "" Vector__XXX
 SG_ Led0035_value : 272|8@1+ (1,0) [0|255] "" Vector__XXX
 SG_ Led0034_value : 264|8@1+ (1,0) [0|255] "" Vector__XXX
 SG_ Led0033_value : 256|8@1+ (1,0) [0|255] "" Vector__XXX
 SG_ Led0032_value : 248|8@1+ (1,0) [0|255] "" Vector__XXX
 SG_ Led0031_value : 240|8@1+ (1,0) [0|255] "" Vector__XXX
 SG_ Led0030_value : 232|8@1+ (1,0) [0|255] "" Vector__XXX
 SG_ Led0029_value : 224|8@1+ (1,0) [0|255] "" Vector__XXX
 SG_ Led0028_value : 216|8@1+ (1,0) [0|255] "" Vector__XXX
 SG_ Led0027_value : 208|8@1+ (1,0) [0|255] "" Vector__XXX
 SG_ Led0026_value : 200|8@1+ (1,0) [0|255] "" Vector__XXX
 SG_ Led0025_value : 192|8@1+ (1,0) [0|255] "" Vector__XXX
 SG_ Led0024_value : 184|8@1+ (1,0) [0|255] "" Vector__XXX
 SG_ Led0023_value : 176|8@1+ (1,0) [0|255] "" Vector__XXX
 SG_ Led0022_value : 168|8@1+ (1,0) [0|255] "" Vector__XXX
 SG_ Led0021_value : 160|8@1+ (1,0) [0|255] "" Vector__XXX
 SG_ Led0020_value : 152|8@1+ (1,0) [0|255] "" Vector__XXX
 SG_ Led0019_value : 144|8@1+ (1,0) [0|255] "" Vector__XXX
 SG_ Led0018_value : 136|8@1+ (1,0) [0|255] "" Vector__XXX
 SG_ Led0017_value : 128|8@1+ (1,0) [0|255] "" Vector__XXX
 SG_ Led0016_value : 120|8@1+ (1,0) [0|255] "" Vector__XXX
 SG_ Led0015_value : 112|8@1+ (1,0) [0|255] "" Vector__XXX
 SG_ Led0014_value : 104|8@1+ (1,0) [0|255] "" Vector__XXX
 SG_ Led0013_value : 96|8@1+ (1,0) [0|255] "" Vector__XXX
 SG_ Led0012_value : 88|8@1+ (1,0) [0|255] "" Vector__XXX
 SG_ Led0011_value : 80|8@1+ (1,0) [0|255] "" Vector__XXX
 SG_ Led0010_value : 72|8@1+ (1,0) [0|255] "" Vector__XXX
 SG_ Led0009_value : 64|8@1+ (1,0) [0|255] "" Vector__XXX
 SG_ Led0008_value : 56|8@1+ (1,0) [0|255] "" Vector__XXX
 SG_ Led0007_value : 48|8@1+ (1,0) [0|255] "" Vector__XXX
 SG_ Led0006_value : 40|8@1+ (1,0) [0|255] "" Vector__XXX
 SG_ Led0005_value : 32|8@1+ (1,0) [0|255] "" Vector__XXX
 SG_ Led0004_value : 24|8@1+ (1,0) [0|255] "" Vector__XXX
 SG_ Led0003_value : 16|8@1+ (1,0) [0|255] "" Vector__XXX
 SG_ Led0002_value : 8|8@1+ (1,0) [0|255] "" Vector__XXX
 SG_ Led0001_value : 0|8@1+ (1,0) [0|255] "" Vector__XXX

BO_ 1057 ISC_Ctrl_LED_B_33: 64 ISC
 SG_ Led0064_value : 504|8@1+ (1,0) [0|255] "" Vector__XXX
 SG_ Led0063_value : 496|8@1+ (1,0) [0|255] "" Vector__XXX
 SG_ Led0062_value : 488|8@1+ (1,0) [0|255] "" Vector__XXX
 SG_ Led0061_value : 480|8@1+ (1,0) [0|255] "" Vector__XXX
 SG_ Led0060_value : 472|8@1+ (1,0) [0|255] "" Vector__XXX
 SG_ Led0059_value : 464|8@1+ (1,0) [0|255] "" Vector__XXX
 SG_ Led0058_value : 456|8@1+ (1,0) [0|255] "" Vector__XXX
 SG_ Led0057_value : 448|8@1+ (1,0) [0|255] "" Vector__XXX
 SG_ Led0056_value : 440|8@1+ (1,0) [0|255] "" Vector__XXX
 SG_ Led0055_value : 432|8@1+ (1,0) [0|255] "" Vector__XXX
 SG_ Led0054_value : 424|8@1+ (1,0) [0|255] "" Vector__XXX
 SG_ Led0053_value : 416|8@1+ (1,0) [0|255] "" Vector__XXX
 SG_ Led0052_value : 408|8@1+ (1,0) [0|255] "" Vector__XXX
 SG_ Led0051_value : 400|8@1+ (1,0) [0|255] "" Vector__XXX
 SG_ Led0050_value : 392|8@1+ (1,0) [0|255] "" Vector__XXX
 SG_ Led0049_value : 384|8@1+ (1,0) [0|255] "" Vector__XXX
 SG_ Led0048_value : 376|8@1+ (1,0) [0|255] "" Vector__XXX
 SG_ Led0047_value : 368|8@1+ (1,0) [0|255] "" Vector__XXX
 SG_ Led0046_value : 360|8@1+ (1,0) [0|255] "" Vector__XXX
 SG_ Led0045_value : 352|8@1+ (1,0) [0|255] "" Vector__XXX
 SG_ Led0044_value : 344|8@1+ (1,0) [0|255] "" Vector__XXX
 SG_ Led0043_value : 336|8@1+ (1,0) [0|255] "" Vector__XXX
 SG_ Led0042_value : 328|8@1+ (1,0) [0|255] "" Vector__XXX
 SG_ Led0041_value : 320|8@1+ (1,0) [0|255] "" Vector__XXX
 SG_ Led0040_value : 312|8@1+ (1,0) [0|255] "" Vector__XXX
 SG_ Led0039_value : 304|8@1+ (1,0) [0|255] "" Vector__XXX
 SG_ Led0038_value : 296|8@1+ (1,0) [0|255] "" Vector__XXX
 SG_ Led0037_value : 288|8@1+ (1,0) [0|255] "" Vector__XXX
 SG_ Led0036_value : 280|8@1+ (1,0) [0|255] "" Vector__XXX
 SG_ Led0035_value : 272|8@1+ (1,0) [0|255] "" Vector__XXX
 SG_ Led0034_value : 264|8@1+ (1,0) [0|255] "" Vector__XXX
 SG_ Led0033_value : 256|8@1+ (1,0) [0|255] "" Vector__XXX
 SG_ Led0032_value : 248|8@1+ (1,0) [0|255] "" Vector__XXX
 SG_ Led0031_value : 240|8@1+ (1,0) [0|255] "" Vector__XXX
 SG_ Led0030_value : 232|8@1+ (1,0) [0|255] "" Vector__XXX
 SG_ Led0029_value : 224|8@1+ (1,0) [0|255] "" Vector__XXX
 SG_ Led0028_value : 216|8@1+ (1,0) [0|255] "" Vector__XXX
 SG_ Led0027_value : 208|8@1+ (1,0) [0|255] "" Vector__XXX
 SG_ Led0026_value : 200|8@1+ (1,0) [0|255] "" Vector__XXX
 SG_ Led0025_value : 192|8@1+ (1,0) [0|255] "" Vector__XXX
 SG_ Led0024_value : 184|8@1+ (1,0) [0|255] "" Vector__XXX
 SG_ Led0023_value : 176|8@1+ (1,0) [0|255] "" Vector__XXX
 SG_ Led0022_value : 168|8@1+ (1,0) [0|255] "" Vector__XXX
 SG_ Led0021_value : 160|8@1+ (1,0) [0|255] "" Vector__XXX
 SG_ Led0020_value : 152|8@1+ (1,0) [0|255] "" Vector__XXX
 SG_ Led0019_value : 144|8@1+ (1,0) [0|255] "" Vector__XXX
 SG_ Led0018_value : 136|8@1+ (1,0) [0|255] "" Vector__XXX
 SG_ Led0017_value : 128|8@1+ (1,0) [0|255] "" Vector__XXX
 SG_ Led0016_value : 120|8@1+ (1,0) [0|255] "" Vector__XXX
 SG_ Led0015_value : 112|8@1+ (1,0) [0|255] "" Vector__XXX
 SG_ Led0014_value : 104|8@1+ (1,0) [0|255] "" Vector__XXX
 SG_ Led0013_value : 96|8@1+ (1,0) [0|255] "" Vector__XXX
 SG_ Led0012_value : 88|8@1+ (1,0) [0|255] "" Vector__XXX
 SG_ Led0011_value : 80|8@1+ (1,0) [0|255] "" Vector__XXX
 SG_ Led0010_value : 72|8@1+ (1,0) [0|255] "" Vector__XXX
 SG_ Led0009_value : 64|8@1+ (1,0) [0|255] "" Vector__XXX
 SG_ Led0008_value : 56|8@1+ (1,0) [0|255] "" Vector__XXX
 SG_ Led0007_value : 48|8@1+ (1,0) [0|255] "" Vector__XXX
 SG_ Led0006_value : 40|8@1+ (1,0) [0|255] "" Vector__XXX
 SG_ Led0005_value : 32|8@1+ (1,0) [0|255] "" Vector__XXX
 SG_ Led0004_value : 24|8@1+ (1,0) [0|255] "" Vector__XXX
 SG_ Led0003_value : 16|8@1+ (1,0) [0|255] "" Vector__XXX
 SG_ Led0002_value : 8|8@1+ (1,0) [0|255] "" Vector__XXX
 SG_ Led0001_value : 0|8@1+ (1,0) [0|255] "" Vector__XXX

BO_ 1056 ISC_Ctrl_LED_B_32: 64 ISC
 SG_ Led0064_value : 504|8@1+ (1,0) [0|255] "" Vector__XXX
 SG_ Led0063_value : 496|8@1+ (1,0) [0|255] "" Vector__XXX
 SG_ Led0062_value : 488|8@1+ (1,0) [0|255] "" Vector__XXX
 SG_ Led0061_value : 480|8@1+ (1,0) [0|255] "" Vector__XXX
 SG_ Led0060_value : 472|8@1+ (1,0) [0|255] "" Vector__XXX
 SG_ Led0059_value : 464|8@1+ (1,0) [0|255] "" Vector__XXX
 SG_ Led0058_value : 456|8@1+ (1,0) [0|255] "" Vector__XXX
 SG_ Led0057_value : 448|8@1+ (1,0) [0|255] "" Vector__XXX
 SG_ Led0056_value : 440|8@1+ (1,0) [0|255] "" Vector__XXX
 SG_ Led0055_value : 432|8@1+ (1,0) [0|255] "" Vector__XXX
 SG_ Led0054_value : 424|8@1+ (1,0) [0|255] "" Vector__XXX
 SG_ Led0053_value : 416|8@1+ (1,0) [0|255] "" Vector__XXX
 SG_ Led0052_value : 408|8@1+ (1,0) [0|255] "" Vector__XXX
 SG_ Led0051_value : 400|8@1+ (1,0) [0|255] "" Vector__XXX
 SG_ Led0050_value : 392|8@1+ (1,0) [0|255] "" Vector__XXX
 SG_ Led0049_value : 384|8@1+ (1,0) [0|255] "" Vector__XXX
 SG_ Led0048_value : 376|8@1+ (1,0) [0|255] "" Vector__XXX
 SG_ Led0047_value : 368|8@1+ (1,0) [0|255] "" Vector__XXX
 SG_ Led0046_value : 360|8@1+ (1,0) [0|255] "" Vector__XXX
 SG_ Led0045_value : 352|8@1+ (1,0) [0|255] "" Vector__XXX
 SG_ Led0044_value : 344|8@1+ (1,0) [0|255] "" Vector__XXX
 SG_ Led0043_value : 336|8@1+ (1,0) [0|255] "" Vector__XXX
 SG_ Led0042_value : 328|8@1+ (1,0) [0|255] "" Vector__XXX
 SG_ Led0041_value : 320|8@1+ (1,0) [0|255] "" Vector__XXX
 SG_ Led0040_value : 312|8@1+ (1,0) [0|255] "" Vector__XXX
 SG_ Led0039_value : 304|8@1+ (1,0) [0|255] "" Vector__XXX
 SG_ Led0038_value : 296|8@1+ (1,0) [0|255] "" Vector__XXX
 SG_ Led0037_value : 288|8@1+ (1,0) [0|255] "" Vector__XXX
 SG_ Led0036_value : 280|8@1+ (1,0) [0|255] "" Vector__XXX
 SG_ Led0035_value : 272|8@1+ (1,0) [0|255] "" Vector__XXX
 SG_ Led0034_value : 264|8@1+ (1,0) [0|255] "" Vector__XXX
 SG_ Led0033_value : 256|8@1+ (1,0) [0|255] "" Vector__XXX
 SG_ Led0032_value : 248|8@1+ (1,0) [0|255] "" Vector__XXX
 SG_ Led0031_value : 240|8@1+ (1,0) [0|255] "" Vector__XXX
 SG_ Led0030_value : 232|8@1+ (1,0) [0|255] "" Vector__XXX
 SG_ Led0029_value : 224|8@1+ (1,0) [0|255] "" Vector__XXX
 SG_ Led0028_value : 216|8@1+ (1,0) [0|255] "" Vector__XXX
 SG_ Led0027_value : 208|8@1+ (1,0) [0|255] "" Vector__XXX
 SG_ Led0026_value : 200|8@1+ (1,0) [0|255] "" Vector__XXX
 SG_ Led0025_value : 192|8@1+ (1,0) [0|255] "" Vector__XXX
 SG_ Led0024_value : 184|8@1+ (1,0) [0|255] "" Vector__XXX
 SG_ Led0023_value : 176|8@1+ (1,0) [0|255] "" Vector__XXX
 SG_ Led0022_value : 168|8@1+ (1,0) [0|255] "" Vector__XXX
 SG_ Led0021_value : 160|8@1+ (1,0) [0|255] "" Vector__XXX
 SG_ Led0020_value : 152|8@1+ (1,0) [0|255] "" Vector__XXX
 SG_ Led0019_value : 144|8@1+ (1,0) [0|255] "" Vector__XXX
 SG_ Led0018_value : 136|8@1+ (1,0) [0|255] "" Vector__XXX
 SG_ Led0017_value : 128|8@1+ (1,0) [0|255] "" Vector__XXX
 SG_ Led0016_value : 120|8@1+ (1,0) [0|255] "" Vector__XXX
 SG_ Led0015_value : 112|8@1+ (1,0) [0|255] "" Vector__XXX
 SG_ Led0014_value : 104|8@1+ (1,0) [0|255] "" Vector__XXX
 SG_ Led0013_value : 96|8@1+ (1,0) [0|255] "" Vector__XXX
 SG_ Led0012_value : 88|8@1+ (1,0) [0|255] "" Vector__XXX
 SG_ Led0011_value : 80|8@1+ (1,0) [0|255] "" Vector__XXX
 SG_ Led0010_value : 72|8@1+ (1,0) [0|255] "" Vector__XXX
 SG_ Led0009_value : 64|8@1+ (1,0) [0|255] "" Vector__XXX
 SG_ Led0008_value : 56|8@1+ (1,0) [0|255] "" Vector__XXX
 SG_ Led0007_value : 48|8@1+ (1,0) [0|255] "" Vector__XXX
 SG_ Led0006_value : 40|8@1+ (1,0) [0|255] "" Vector__XXX
 SG_ Led0005_value : 32|8@1+ (1,0) [0|255] "" Vector__XXX
 SG_ Led0004_value : 24|8@1+ (1,0) [0|255] "" Vector__XXX
 SG_ Led0003_value : 16|8@1+ (1,0) [0|255] "" Vector__XXX
 SG_ Led0002_value : 8|8@1+ (1,0) [0|255] "" Vector__XXX
 SG_ Led0001_value : 0|8@1+ (1,0) [0|255] "" Vector__XXX

BO_ 1055 ISC_Ctrl_LED_B_31: 64 ISC
 SG_ Led0064_value : 504|8@1+ (1,0) [0|255] "" Vector__XXX
 SG_ Led0063_value : 496|8@1+ (1,0) [0|255] "" Vector__XXX
 SG_ Led0062_value : 488|8@1+ (1,0) [0|255] "" Vector__XXX
 SG_ Led0061_value : 480|8@1+ (1,0) [0|255] "" Vector__XXX
 SG_ Led0060_value : 472|8@1+ (1,0) [0|255] "" Vector__XXX
 SG_ Led0059_value : 464|8@1+ (1,0) [0|255] "" Vector__XXX
 SG_ Led0058_value : 456|8@1+ (1,0) [0|255] "" Vector__XXX
 SG_ Led0057_value : 448|8@1+ (1,0) [0|255] "" Vector__XXX
 SG_ Led0056_value : 440|8@1+ (1,0) [0|255] "" Vector__XXX
 SG_ Led0055_value : 432|8@1+ (1,0) [0|255] "" Vector__XXX
 SG_ Led0054_value : 424|8@1+ (1,0) [0|255] "" Vector__XXX
 SG_ Led0053_value : 416|8@1+ (1,0) [0|255] "" Vector__XXX
 SG_ Led0052_value : 408|8@1+ (1,0) [0|255] "" Vector__XXX
 SG_ Led0051_value : 400|8@1+ (1,0) [0|255] "" Vector__XXX
 SG_ Led0050_value : 392|8@1+ (1,0) [0|255] "" Vector__XXX
 SG_ Led0049_value : 384|8@1+ (1,0) [0|255] "" Vector__XXX
 SG_ Led0048_value : 376|8@1+ (1,0) [0|255] "" Vector__XXX
 SG_ Led0047_value : 368|8@1+ (1,0) [0|255] "" Vector__XXX
 SG_ Led0046_value : 360|8@1+ (1,0) [0|255] "" Vector__XXX
 SG_ Led0045_value : 352|8@1+ (1,0) [0|255] "" Vector__XXX
 SG_ Led0044_value : 344|8@1+ (1,0) [0|255] "" Vector__XXX
 SG_ Led0043_value : 336|8@1+ (1,0) [0|255] "" Vector__XXX
 SG_ Led0042_value : 328|8@1+ (1,0) [0|255] "" Vector__XXX
 SG_ Led0041_value : 320|8@1+ (1,0) [0|255] "" Vector__XXX
 SG_ Led0040_value : 312|8@1+ (1,0) [0|255] "" Vector__XXX
 SG_ Led0039_value : 304|8@1+ (1,0) [0|255] "" Vector__XXX
 SG_ Led0038_value : 296|8@1+ (1,0) [0|255] "" Vector__XXX
 SG_ Led0037_value : 288|8@1+ (1,0) [0|255] "" Vector__XXX
 SG_ Led0036_value : 280|8@1+ (1,0) [0|255] "" Vector__XXX
 SG_ Led0035_value : 272|8@1+ (1,0) [0|255] "" Vector__XXX
 SG_ Led0034_value : 264|8@1+ (1,0) [0|255] "" Vector__XXX
 SG_ Led0033_value : 256|8@1+ (1,0) [0|255] "" Vector__XXX
 SG_ Led0032_value : 248|8@1+ (1,0) [0|255] "" Vector__XXX
 SG_ Led0031_value : 240|8@1+ (1,0) [0|255] "" Vector__XXX
 SG_ Led0030_value : 232|8@1+ (1,0) [0|255] "" Vector__XXX
 SG_ Led0029_value : 224|8@1+ (1,0) [0|255] "" Vector__XXX
 SG_ Led0028_value : 216|8@1+ (1,0) [0|255] "" Vector__XXX
 SG_ Led0027_value : 208|8@1+ (1,0) [0|255] "" Vector__XXX
 SG_ Led0026_value : 200|8@1+ (1,0) [0|255] "" Vector__XXX
 SG_ Led0025_value : 192|8@1+ (1,0) [0|255] "" Vector__XXX
 SG_ Led0024_value : 184|8@1+ (1,0) [0|255] "" Vector__XXX
 SG_ Led0023_value : 176|8@1+ (1,0) [0|255] "" Vector__XXX
 SG_ Led0022_value : 168|8@1+ (1,0) [0|255] "" Vector__XXX
 SG_ Led0021_value : 160|8@1+ (1,0) [0|255] "" Vector__XXX
 SG_ Led0020_value : 152|8@1+ (1,0) [0|255] "" Vector__XXX
 SG_ Led0019_value : 144|8@1+ (1,0) [0|255] "" Vector__XXX
 SG_ Led0018_value : 136|8@1+ (1,0) [0|255] "" Vector__XXX
 SG_ Led0017_value : 128|8@1+ (1,0) [0|255] "" Vector__XXX
 SG_ Led0016_value : 120|8@1+ (1,0) [0|255] "" Vector__XXX
 SG_ Led0015_value : 112|8@1+ (1,0) [0|255] "" Vector__XXX
 SG_ Led0014_value : 104|8@1+ (1,0) [0|255] "" Vector__XXX
 SG_ Led0013_value : 96|8@1+ (1,0) [0|255] "" Vector__XXX
 SG_ Led0012_value : 88|8@1+ (1,0) [0|255] "" Vector__XXX
 SG_ Led0011_value : 80|8@1+ (1,0) [0|255] "" Vector__XXX
 SG_ Led0010_value : 72|8@1+ (1,0) [0|255] "" Vector__XXX
 SG_ Led0009_value : 64|8@1+ (1,0) [0|255] "" Vector__XXX
 SG_ Led0008_value : 56|8@1+ (1,0) [0|255] "" Vector__XXX
 SG_ Led0007_value : 48|8@1+ (1,0) [0|255] "" Vector__XXX
 SG_ Led0006_value : 40|8@1+ (1,0) [0|255] "" Vector__XXX
 SG_ Led0005_value : 32|8@1+ (1,0) [0|255] "" Vector__XXX
 SG_ Led0004_value : 24|8@1+ (1,0) [0|255] "" Vector__XXX
 SG_ Led0003_value : 16|8@1+ (1,0) [0|255] "" Vector__XXX
 SG_ Led0002_value : 8|8@1+ (1,0) [0|255] "" Vector__XXX
 SG_ Led0001_value : 0|8@1+ (1,0) [0|255] "" Vector__XXX

BO_ 1054 ISC_Ctrl_LED_B_30: 64 ISC
 SG_ Led0064_value : 504|8@1+ (1,0) [0|255] "" Vector__XXX
 SG_ Led0063_value : 496|8@1+ (1,0) [0|255] "" Vector__XXX
 SG_ Led0062_value : 488|8@1+ (1,0) [0|255] "" Vector__XXX
 SG_ Led0061_value : 480|8@1+ (1,0) [0|255] "" Vector__XXX
 SG_ Led0060_value : 472|8@1+ (1,0) [0|255] "" Vector__XXX
 SG_ Led0059_value : 464|8@1+ (1,0) [0|255] "" Vector__XXX
 SG_ Led0058_value : 456|8@1+ (1,0) [0|255] "" Vector__XXX
 SG_ Led0057_value : 448|8@1+ (1,0) [0|255] "" Vector__XXX
 SG_ Led0056_value : 440|8@1+ (1,0) [0|255] "" Vector__XXX
 SG_ Led0055_value : 432|8@1+ (1,0) [0|255] "" Vector__XXX
 SG_ Led0054_value : 424|8@1+ (1,0) [0|255] "" Vector__XXX
 SG_ Led0053_value : 416|8@1+ (1,0) [0|255] "" Vector__XXX
 SG_ Led0052_value : 408|8@1+ (1,0) [0|255] "" Vector__XXX
 SG_ Led0051_value : 400|8@1+ (1,0) [0|255] "" Vector__XXX
 SG_ Led0050_value : 392|8@1+ (1,0) [0|255] "" Vector__XXX
 SG_ Led0049_value : 384|8@1+ (1,0) [0|255] "" Vector__XXX
 SG_ Led0048_value : 376|8@1+ (1,0) [0|255] "" Vector__XXX
 SG_ Led0047_value : 368|8@1+ (1,0) [0|255] "" Vector__XXX
 SG_ Led0046_value : 360|8@1+ (1,0) [0|255] "" Vector__XXX
 SG_ Led0045_value : 352|8@1+ (1,0) [0|255] "" Vector__XXX
 SG_ Led0044_value : 344|8@1+ (1,0) [0|255] "" Vector__XXX
 SG_ Led0043_value : 336|8@1+ (1,0) [0|255] "" Vector__XXX
 SG_ Led0042_value : 328|8@1+ (1,0) [0|255] "" Vector__XXX
 SG_ Led0041_value : 320|8@1+ (1,0) [0|255] "" Vector__XXX
 SG_ Led0040_value : 312|8@1+ (1,0) [0|255] "" Vector__XXX
 SG_ Led0039_value : 304|8@1+ (1,0) [0|255] "" Vector__XXX
 SG_ Led0038_value : 296|8@1+ (1,0) [0|255] "" Vector__XXX
 SG_ Led0037_value : 288|8@1+ (1,0) [0|255] "" Vector__XXX
 SG_ Led0036_value : 280|8@1+ (1,0) [0|255] "" Vector__XXX
 SG_ Led0035_value : 272|8@1+ (1,0) [0|255] "" Vector__XXX
 SG_ Led0034_value : 264|8@1+ (1,0) [0|255] "" Vector__XXX
 SG_ Led0033_value : 256|8@1+ (1,0) [0|255] "" Vector__XXX
 SG_ Led0032_value : 248|8@1+ (1,0) [0|255] "" Vector__XXX
 SG_ Led0031_value : 240|8@1+ (1,0) [0|255] "" Vector__XXX
 SG_ Led0030_value : 232|8@1+ (1,0) [0|255] "" Vector__XXX
 SG_ Led0029_value : 224|8@1+ (1,0) [0|255] "" Vector__XXX
 SG_ Led0028_value : 216|8@1+ (1,0) [0|255] "" Vector__XXX
 SG_ Led0027_value : 208|8@1+ (1,0) [0|255] "" Vector__XXX
 SG_ Led0026_value : 200|8@1+ (1,0) [0|255] "" Vector__XXX
 SG_ Led0025_value : 192|8@1+ (1,0) [0|255] "" Vector__XXX
 SG_ Led0024_value : 184|8@1+ (1,0) [0|255] "" Vector__XXX
 SG_ Led0023_value : 176|8@1+ (1,0) [0|255] "" Vector__XXX
 SG_ Led0022_value : 168|8@1+ (1,0) [0|255] "" Vector__XXX
 SG_ Led0021_value : 160|8@1+ (1,0) [0|255] "" Vector__XXX
 SG_ Led0020_value : 152|8@1+ (1,0) [0|255] "" Vector__XXX
 SG_ Led0019_value : 144|8@1+ (1,0) [0|255] "" Vector__XXX
 SG_ Led0018_value : 136|8@1+ (1,0) [0|255] "" Vector__XXX
 SG_ Led0017_value : 128|8@1+ (1,0) [0|255] "" Vector__XXX
 SG_ Led0016_value : 120|8@1+ (1,0) [0|255] "" Vector__XXX
 SG_ Led0015_value : 112|8@1+ (1,0) [0|255] "" Vector__XXX
 SG_ Led0014_value : 104|8@1+ (1,0) [0|255] "" Vector__XXX
 SG_ Led0013_value : 96|8@1+ (1,0) [0|255] "" Vector__XXX
 SG_ Led0012_value : 88|8@1+ (1,0) [0|255] "" Vector__XXX
 SG_ Led0011_value : 80|8@1+ (1,0) [0|255] "" Vector__XXX
 SG_ Led0010_value : 72|8@1+ (1,0) [0|255] "" Vector__XXX
 SG_ Led0009_value : 64|8@1+ (1,0) [0|255] "" Vector__XXX
 SG_ Led0008_value : 56|8@1+ (1,0) [0|255] "" Vector__XXX
 SG_ Led0007_value : 48|8@1+ (1,0) [0|255] "" Vector__XXX
 SG_ Led0006_value : 40|8@1+ (1,0) [0|255] "" Vector__XXX
 SG_ Led0005_value : 32|8@1+ (1,0) [0|255] "" Vector__XXX
 SG_ Led0004_value : 24|8@1+ (1,0) [0|255] "" Vector__XXX
 SG_ Led0003_value : 16|8@1+ (1,0) [0|255] "" Vector__XXX
 SG_ Led0002_value : 8|8@1+ (1,0) [0|255] "" Vector__XXX
 SG_ Led0001_value : 0|8@1+ (1,0) [0|255] "" Vector__XXX

BO_ 1053 ISC_Ctrl_LED_B_29: 64 ISC
 SG_ Led0064_value : 504|8@1+ (1,0) [0|255] "" Vector__XXX
 SG_ Led0063_value : 496|8@1+ (1,0) [0|255] "" Vector__XXX
 SG_ Led0062_value : 488|8@1+ (1,0) [0|255] "" Vector__XXX
 SG_ Led0061_value : 480|8@1+ (1,0) [0|255] "" Vector__XXX
 SG_ Led0060_value : 472|8@1+ (1,0) [0|255] "" Vector__XXX
 SG_ Led0059_value : 464|8@1+ (1,0) [0|255] "" Vector__XXX
 SG_ Led0058_value : 456|8@1+ (1,0) [0|255] "" Vector__XXX
 SG_ Led0057_value : 448|8@1+ (1,0) [0|255] "" Vector__XXX
 SG_ Led0056_value : 440|8@1+ (1,0) [0|255] "" Vector__XXX
 SG_ Led0055_value : 432|8@1+ (1,0) [0|255] "" Vector__XXX
 SG_ Led0054_value : 424|8@1+ (1,0) [0|255] "" Vector__XXX
 SG_ Led0053_value : 416|8@1+ (1,0) [0|255] "" Vector__XXX
 SG_ Led0052_value : 408|8@1+ (1,0) [0|255] "" Vector__XXX
 SG_ Led0051_value : 400|8@1+ (1,0) [0|255] "" Vector__XXX
 SG_ Led0050_value : 392|8@1+ (1,0) [0|255] "" Vector__XXX
 SG_ Led0049_value : 384|8@1+ (1,0) [0|255] "" Vector__XXX
 SG_ Led0048_value : 376|8@1+ (1,0) [0|255] "" Vector__XXX
 SG_ Led0047_value : 368|8@1+ (1,0) [0|255] "" Vector__XXX
 SG_ Led0046_value : 360|8@1+ (1,0) [0|255] "" Vector__XXX
 SG_ Led0045_value : 352|8@1+ (1,0) [0|255] "" Vector__XXX
 SG_ Led0044_value : 344|8@1+ (1,0) [0|255] "" Vector__XXX
 SG_ Led0043_value : 336|8@1+ (1,0) [0|255] "" Vector__XXX
 SG_ Led0042_value : 328|8@1+ (1,0) [0|255] "" Vector__XXX
 SG_ Led0041_value : 320|8@1+ (1,0) [0|255] "" Vector__XXX
 SG_ Led0040_value : 312|8@1+ (1,0) [0|255] "" Vector__XXX
 SG_ Led0039_value : 304|8@1+ (1,0) [0|255] "" Vector__XXX
 SG_ Led0038_value : 296|8@1+ (1,0) [0|255] "" Vector__XXX
 SG_ Led0037_value : 288|8@1+ (1,0) [0|255] "" Vector__XXX
 SG_ Led0036_value : 280|8@1+ (1,0) [0|255] "" Vector__XXX
 SG_ Led0035_value : 272|8@1+ (1,0) [0|255] "" Vector__XXX
 SG_ Led0034_value : 264|8@1+ (1,0) [0|255] "" Vector__XXX
 SG_ Led0033_value : 256|8@1+ (1,0) [0|255] "" Vector__XXX
 SG_ Led0032_value : 248|8@1+ (1,0) [0|255] "" Vector__XXX
 SG_ Led0031_value : 240|8@1+ (1,0) [0|255] "" Vector__XXX
 SG_ Led0030_value : 232|8@1+ (1,0) [0|255] "" Vector__XXX
 SG_ Led0029_value : 224|8@1+ (1,0) [0|255] "" Vector__XXX
 SG_ Led0028_value : 216|8@1+ (1,0) [0|255] "" Vector__XXX
 SG_ Led0027_value : 208|8@1+ (1,0) [0|255] "" Vector__XXX
 SG_ Led0026_value : 200|8@1+ (1,0) [0|255] "" Vector__XXX
 SG_ Led0025_value : 192|8@1+ (1,0) [0|255] "" Vector__XXX
 SG_ Led0024_value : 184|8@1+ (1,0) [0|255] "" Vector__XXX
 SG_ Led0023_value : 176|8@1+ (1,0) [0|255] "" Vector__XXX
 SG_ Led0022_value : 168|8@1+ (1,0) [0|255] "" Vector__XXX
 SG_ Led0021_value : 160|8@1+ (1,0) [0|255] "" Vector__XXX
 SG_ Led0020_value : 152|8@1+ (1,0) [0|255] "" Vector__XXX
 SG_ Led0019_value : 144|8@1+ (1,0) [0|255] "" Vector__XXX
 SG_ Led0018_value : 136|8@1+ (1,0) [0|255] "" Vector__XXX
 SG_ Led0017_value : 128|8@1+ (1,0) [0|255] "" Vector__XXX
 SG_ Led0016_value : 120|8@1+ (1,0) [0|255] "" Vector__XXX
 SG_ Led0015_value : 112|8@1+ (1,0) [0|255] "" Vector__XXX
 SG_ Led0014_value : 104|8@1+ (1,0) [0|255] "" Vector__XXX
 SG_ Led0013_value : 96|8@1+ (1,0) [0|255] "" Vector__XXX
 SG_ Led0012_value : 88|8@1+ (1,0) [0|255] "" Vector__XXX
 SG_ Led0011_value : 80|8@1+ (1,0) [0|255] "" Vector__XXX
 SG_ Led0010_value : 72|8@1+ (1,0) [0|255] "" Vector__XXX
 SG_ Led0009_value : 64|8@1+ (1,0) [0|255] "" Vector__XXX
 SG_ Led0008_value : 56|8@1+ (1,0) [0|255] "" Vector__XXX
 SG_ Led0007_value : 48|8@1+ (1,0) [0|255] "" Vector__XXX
 SG_ Led0006_value : 40|8@1+ (1,0) [0|255] "" Vector__XXX
 SG_ Led0005_value : 32|8@1+ (1,0) [0|255] "" Vector__XXX
 SG_ Led0004_value : 24|8@1+ (1,0) [0|255] "" Vector__XXX
 SG_ Led0003_value : 16|8@1+ (1,0) [0|255] "" Vector__XXX
 SG_ Led0002_value : 8|8@1+ (1,0) [0|255] "" Vector__XXX
 SG_ Led0001_value : 0|8@1+ (1,0) [0|255] "" Vector__XXX

BO_ 1052 ISC_Ctrl_LED_B_28: 64 ISC
 SG_ Led0064_value : 504|8@1+ (1,0) [0|255] "" Vector__XXX
 SG_ Led0063_value : 496|8@1+ (1,0) [0|255] "" Vector__XXX
 SG_ Led0062_value : 488|8@1+ (1,0) [0|255] "" Vector__XXX
 SG_ Led0061_value : 480|8@1+ (1,0) [0|255] "" Vector__XXX
 SG_ Led0060_value : 472|8@1+ (1,0) [0|255] "" Vector__XXX
 SG_ Led0059_value : 464|8@1+ (1,0) [0|255] "" Vector__XXX
 SG_ Led0058_value : 456|8@1+ (1,0) [0|255] "" Vector__XXX
 SG_ Led0057_value : 448|8@1+ (1,0) [0|255] "" Vector__XXX
 SG_ Led0056_value : 440|8@1+ (1,0) [0|255] "" Vector__XXX
 SG_ Led0055_value : 432|8@1+ (1,0) [0|255] "" Vector__XXX
 SG_ Led0054_value : 424|8@1+ (1,0) [0|255] "" Vector__XXX
 SG_ Led0053_value : 416|8@1+ (1,0) [0|255] "" Vector__XXX
 SG_ Led0052_value : 408|8@1+ (1,0) [0|255] "" Vector__XXX
 SG_ Led0051_value : 400|8@1+ (1,0) [0|255] "" Vector__XXX
 SG_ Led0050_value : 392|8@1+ (1,0) [0|255] "" Vector__XXX
 SG_ Led0049_value : 384|8@1+ (1,0) [0|255] "" Vector__XXX
 SG_ Led0048_value : 376|8@1+ (1,0) [0|255] "" Vector__XXX
 SG_ Led0047_value : 368|8@1+ (1,0) [0|255] "" Vector__XXX
 SG_ Led0046_value : 360|8@1+ (1,0) [0|255] "" Vector__XXX
 SG_ Led0045_value : 352|8@1+ (1,0) [0|255] "" Vector__XXX
 SG_ Led0044_value : 344|8@1+ (1,0) [0|255] "" Vector__XXX
 SG_ Led0043_value : 336|8@1+ (1,0) [0|255] "" Vector__XXX
 SG_ Led0042_value : 328|8@1+ (1,0) [0|255] "" Vector__XXX
 SG_ Led0041_value : 320|8@1+ (1,0) [0|255] "" Vector__XXX
 SG_ Led0040_value : 312|8@1+ (1,0) [0|255] "" Vector__XXX
 SG_ Led0039_value : 304|8@1+ (1,0) [0|255] "" Vector__XXX
 SG_ Led0038_value : 296|8@1+ (1,0) [0|255] "" Vector__XXX
 SG_ Led0037_value : 288|8@1+ (1,0) [0|255] "" Vector__XXX
 SG_ Led0036_value : 280|8@1+ (1,0) [0|255] "" Vector__XXX
 SG_ Led0035_value : 272|8@1+ (1,0) [0|255] "" Vector__XXX
 SG_ Led0034_value : 264|8@1+ (1,0) [0|255] "" Vector__XXX
 SG_ Led0033_value : 256|8@1+ (1,0) [0|255] "" Vector__XXX
 SG_ Led0032_value : 248|8@1+ (1,0) [0|255] "" Vector__XXX
 SG_ Led0031_value : 240|8@1+ (1,0) [0|255] "" Vector__XXX
 SG_ Led0030_value : 232|8@1+ (1,0) [0|255] "" Vector__XXX
 SG_ Led0029_value : 224|8@1+ (1,0) [0|255] "" Vector__XXX
 SG_ Led0028_value : 216|8@1+ (1,0) [0|255] "" Vector__XXX
 SG_ Led0027_value : 208|8@1+ (1,0) [0|255] "" Vector__XXX
 SG_ Led0026_value : 200|8@1+ (1,0) [0|255] "" Vector__XXX
 SG_ Led0025_value : 192|8@1+ (1,0) [0|255] "" Vector__XXX
 SG_ Led0024_value : 184|8@1+ (1,0) [0|255] "" Vector__XXX
 SG_ Led0023_value : 176|8@1+ (1,0) [0|255] "" Vector__XXX
 SG_ Led0022_value : 168|8@1+ (1,0) [0|255] "" Vector__XXX
 SG_ Led0021_value : 160|8@1+ (1,0) [0|255] "" Vector__XXX
 SG_ Led0020_value : 152|8@1+ (1,0) [0|255] "" Vector__XXX
 SG_ Led0019_value : 144|8@1+ (1,0) [0|255] "" Vector__XXX
 SG_ Led0018_value : 136|8@1+ (1,0) [0|255] "" Vector__XXX
 SG_ Led0017_value : 128|8@1+ (1,0) [0|255] "" Vector__XXX
 SG_ Led0016_value : 120|8@1+ (1,0) [0|255] "" Vector__XXX
 SG_ Led0015_value : 112|8@1+ (1,0) [0|255] "" Vector__XXX
 SG_ Led0014_value : 104|8@1+ (1,0) [0|255] "" Vector__XXX
 SG_ Led0013_value : 96|8@1+ (1,0) [0|255] "" Vector__XXX
 SG_ Led0012_value : 88|8@1+ (1,0) [0|255] "" Vector__XXX
 SG_ Led0011_value : 80|8@1+ (1,0) [0|255] "" Vector__XXX
 SG_ Led0010_value : 72|8@1+ (1,0) [0|255] "" Vector__XXX
 SG_ Led0009_value : 64|8@1+ (1,0) [0|255] "" Vector__XXX
 SG_ Led0008_value : 56|8@1+ (1,0) [0|255] "" Vector__XXX
 SG_ Led0007_value : 48|8@1+ (1,0) [0|255] "" Vector__XXX
 SG_ Led0006_value : 40|8@1+ (1,0) [0|255] "" Vector__XXX
 SG_ Led0005_value : 32|8@1+ (1,0) [0|255] "" Vector__XXX
 SG_ Led0004_value : 24|8@1+ (1,0) [0|255] "" Vector__XXX
 SG_ Led0003_value : 16|8@1+ (1,0) [0|255] "" Vector__XXX
 SG_ Led0002_value : 8|8@1+ (1,0) [0|255] "" Vector__XXX
 SG_ Led0001_value : 0|8@1+ (1,0) [0|255] "" Vector__XXX

BO_ 1051 ISC_Ctrl_LED_B_27: 64 ISC
 SG_ Led0064_value : 504|8@1+ (1,0) [0|255] "" Vector__XXX
 SG_ Led0063_value : 496|8@1+ (1,0) [0|255] "" Vector__XXX
 SG_ Led0062_value : 488|8@1+ (1,0) [0|255] "" Vector__XXX
 SG_ Led0061_value : 480|8@1+ (1,0) [0|255] "" Vector__XXX
 SG_ Led0060_value : 472|8@1+ (1,0) [0|255] "" Vector__XXX
 SG_ Led0059_value : 464|8@1+ (1,0) [0|255] "" Vector__XXX
 SG_ Led0058_value : 456|8@1+ (1,0) [0|255] "" Vector__XXX
 SG_ Led0057_value : 448|8@1+ (1,0) [0|255] "" Vector__XXX
 SG_ Led0056_value : 440|8@1+ (1,0) [0|255] "" Vector__XXX
 SG_ Led0055_value : 432|8@1+ (1,0) [0|255] "" Vector__XXX
 SG_ Led0054_value : 424|8@1+ (1,0) [0|255] "" Vector__XXX
 SG_ Led0053_value : 416|8@1+ (1,0) [0|255] "" Vector__XXX
 SG_ Led0052_value : 408|8@1+ (1,0) [0|255] "" Vector__XXX
 SG_ Led0051_value : 400|8@1+ (1,0) [0|255] "" Vector__XXX
 SG_ Led0050_value : 392|8@1+ (1,0) [0|255] "" Vector__XXX
 SG_ Led0049_value : 384|8@1+ (1,0) [0|255] "" Vector__XXX
 SG_ Led0048_value : 376|8@1+ (1,0) [0|255] "" Vector__XXX
 SG_ Led0047_value : 368|8@1+ (1,0) [0|255] "" Vector__XXX
 SG_ Led0046_value : 360|8@1+ (1,0) [0|255] "" Vector__XXX
 SG_ Led0045_value : 352|8@1+ (1,0) [0|255] "" Vector__XXX
 SG_ Led0044_value : 344|8@1+ (1,0) [0|255] "" Vector__XXX
 SG_ Led0043_value : 336|8@1+ (1,0) [0|255] "" Vector__XXX
 SG_ Led0042_value : 328|8@1+ (1,0) [0|255] "" Vector__XXX
 SG_ Led0041_value : 320|8@1+ (1,0) [0|255] "" Vector__XXX
 SG_ Led0040_value : 312|8@1+ (1,0) [0|255] "" Vector__XXX
 SG_ Led0039_value : 304|8@1+ (1,0) [0|255] "" Vector__XXX
 SG_ Led0038_value : 296|8@1+ (1,0) [0|255] "" Vector__XXX
 SG_ Led0037_value : 288|8@1+ (1,0) [0|255] "" Vector__XXX
 SG_ Led0036_value : 280|8@1+ (1,0) [0|255] "" Vector__XXX
 SG_ Led0035_value : 272|8@1+ (1,0) [0|255] "" Vector__XXX
 SG_ Led0034_value : 264|8@1+ (1,0) [0|255] "" Vector__XXX
 SG_ Led0033_value : 256|8@1+ (1,0) [0|255] "" Vector__XXX
 SG_ Led0032_value : 248|8@1+ (1,0) [0|255] "" Vector__XXX
 SG_ Led0031_value : 240|8@1+ (1,0) [0|255] "" Vector__XXX
 SG_ Led0030_value : 232|8@1+ (1,0) [0|255] "" Vector__XXX
 SG_ Led0029_value : 224|8@1+ (1,0) [0|255] "" Vector__XXX
 SG_ Led0028_value : 216|8@1+ (1,0) [0|255] "" Vector__XXX
 SG_ Led0027_value : 208|8@1+ (1,0) [0|255] "" Vector__XXX
 SG_ Led0026_value : 200|8@1+ (1,0) [0|255] "" Vector__XXX
 SG_ Led0025_value : 192|8@1+ (1,0) [0|255] "" Vector__XXX
 SG_ Led0024_value : 184|8@1+ (1,0) [0|255] "" Vector__XXX
 SG_ Led0023_value : 176|8@1+ (1,0) [0|255] "" Vector__XXX
 SG_ Led0022_value : 168|8@1+ (1,0) [0|255] "" Vector__XXX
 SG_ Led0021_value : 160|8@1+ (1,0) [0|255] "" Vector__XXX
 SG_ Led0020_value : 152|8@1+ (1,0) [0|255] "" Vector__XXX
 SG_ Led0019_value : 144|8@1+ (1,0) [0|255] "" Vector__XXX
 SG_ Led0018_value : 136|8@1+ (1,0) [0|255] "" Vector__XXX
 SG_ Led0017_value : 128|8@1+ (1,0) [0|255] "" Vector__XXX
 SG_ Led0016_value : 120|8@1+ (1,0) [0|255] "" Vector__XXX
 SG_ Led0015_value : 112|8@1+ (1,0) [0|255] "" Vector__XXX
 SG_ Led0014_value : 104|8@1+ (1,0) [0|255] "" Vector__XXX
 SG_ Led0013_value : 96|8@1+ (1,0) [0|255] "" Vector__XXX
 SG_ Led0012_value : 88|8@1+ (1,0) [0|255] "" Vector__XXX
 SG_ Led0011_value : 80|8@1+ (1,0) [0|255] "" Vector__XXX
 SG_ Led0010_value : 72|8@1+ (1,0) [0|255] "" Vector__XXX
 SG_ Led0009_value : 64|8@1+ (1,0) [0|255] "" Vector__XXX
 SG_ Led0008_value : 56|8@1+ (1,0) [0|255] "" Vector__XXX
 SG_ Led0007_value : 48|8@1+ (1,0) [0|255] "" Vector__XXX
 SG_ Led0006_value : 40|8@1+ (1,0) [0|255] "" Vector__XXX
 SG_ Led0005_value : 32|8@1+ (1,0) [0|255] "" Vector__XXX
 SG_ Led0004_value : 24|8@1+ (1,0) [0|255] "" Vector__XXX
 SG_ Led0003_value : 16|8@1+ (1,0) [0|255] "" Vector__XXX
 SG_ Led0002_value : 8|8@1+ (1,0) [0|255] "" Vector__XXX
 SG_ Led0001_value : 0|8@1+ (1,0) [0|255] "" Vector__XXX

BO_ 1050 ISC_Ctrl_LED_B_26: 64 ISC
 SG_ Led0064_value : 504|8@1+ (1,0) [0|255] "" Vector__XXX
 SG_ Led0063_value : 496|8@1+ (1,0) [0|255] "" Vector__XXX
 SG_ Led0062_value : 488|8@1+ (1,0) [0|255] "" Vector__XXX
 SG_ Led0061_value : 480|8@1+ (1,0) [0|255] "" Vector__XXX
 SG_ Led0060_value : 472|8@1+ (1,0) [0|255] "" Vector__XXX
 SG_ Led0059_value : 464|8@1+ (1,0) [0|255] "" Vector__XXX
 SG_ Led0058_value : 456|8@1+ (1,0) [0|255] "" Vector__XXX
 SG_ Led0057_value : 448|8@1+ (1,0) [0|255] "" Vector__XXX
 SG_ Led0056_value : 440|8@1+ (1,0) [0|255] "" Vector__XXX
 SG_ Led0055_value : 432|8@1+ (1,0) [0|255] "" Vector__XXX
 SG_ Led0054_value : 424|8@1+ (1,0) [0|255] "" Vector__XXX
 SG_ Led0053_value : 416|8@1+ (1,0) [0|255] "" Vector__XXX
 SG_ Led0052_value : 408|8@1+ (1,0) [0|255] "" Vector__XXX
 SG_ Led0051_value : 400|8@1+ (1,0) [0|255] "" Vector__XXX
 SG_ Led0050_value : 392|8@1+ (1,0) [0|255] "" Vector__XXX
 SG_ Led0049_value : 384|8@1+ (1,0) [0|255] "" Vector__XXX
 SG_ Led0048_value : 376|8@1+ (1,0) [0|255] "" Vector__XXX
 SG_ Led0047_value : 368|8@1+ (1,0) [0|255] "" Vector__XXX
 SG_ Led0046_value : 360|8@1+ (1,0) [0|255] "" Vector__XXX
 SG_ Led0045_value : 352|8@1+ (1,0) [0|255] "" Vector__XXX
 SG_ Led0044_value : 344|8@1+ (1,0) [0|255] "" Vector__XXX
 SG_ Led0043_value : 336|8@1+ (1,0) [0|255] "" Vector__XXX
 SG_ Led0042_value : 328|8@1+ (1,0) [0|255] "" Vector__XXX
 SG_ Led0041_value : 320|8@1+ (1,0) [0|255] "" Vector__XXX
 SG_ Led0040_value : 312|8@1+ (1,0) [0|255] "" Vector__XXX
 SG_ Led0039_value : 304|8@1+ (1,0) [0|255] "" Vector__XXX
 SG_ Led0038_value : 296|8@1+ (1,0) [0|255] "" Vector__XXX
 SG_ Led0037_value : 288|8@1+ (1,0) [0|255] "" Vector__XXX
 SG_ Led0036_value : 280|8@1+ (1,0) [0|255] "" Vector__XXX
 SG_ Led0035_value : 272|8@1+ (1,0) [0|255] "" Vector__XXX
 SG_ Led0034_value : 264|8@1+ (1,0) [0|255] "" Vector__XXX
 SG_ Led0033_value : 256|8@1+ (1,0) [0|255] "" Vector__XXX
 SG_ Led0032_value : 248|8@1+ (1,0) [0|255] "" Vector__XXX
 SG_ Led0031_value : 240|8@1+ (1,0) [0|255] "" Vector__XXX
 SG_ Led0030_value : 232|8@1+ (1,0) [0|255] "" Vector__XXX
 SG_ Led0029_value : 224|8@1+ (1,0) [0|255] "" Vector__XXX
 SG_ Led0028_value : 216|8@1+ (1,0) [0|255] "" Vector__XXX
 SG_ Led0027_value : 208|8@1+ (1,0) [0|255] "" Vector__XXX
 SG_ Led0026_value : 200|8@1+ (1,0) [0|255] "" Vector__XXX
 SG_ Led0025_value : 192|8@1+ (1,0) [0|255] "" Vector__XXX
 SG_ Led0024_value : 184|8@1+ (1,0) [0|255] "" Vector__XXX
 SG_ Led0023_value : 176|8@1+ (1,0) [0|255] "" Vector__XXX
 SG_ Led0022_value : 168|8@1+ (1,0) [0|255] "" Vector__XXX
 SG_ Led0021_value : 160|8@1+ (1,0) [0|255] "" Vector__XXX
 SG_ Led0020_value : 152|8@1+ (1,0) [0|255] "" Vector__XXX
 SG_ Led0019_value : 144|8@1+ (1,0) [0|255] "" Vector__XXX
 SG_ Led0018_value : 136|8@1+ (1,0) [0|255] "" Vector__XXX
 SG_ Led0017_value : 128|8@1+ (1,0) [0|255] "" Vector__XXX
 SG_ Led0016_value : 120|8@1+ (1,0) [0|255] "" Vector__XXX
 SG_ Led0015_value : 112|8@1+ (1,0) [0|255] "" Vector__XXX
 SG_ Led0014_value : 104|8@1+ (1,0) [0|255] "" Vector__XXX
 SG_ Led0013_value : 96|8@1+ (1,0) [0|255] "" Vector__XXX
 SG_ Led0012_value : 88|8@1+ (1,0) [0|255] "" Vector__XXX
 SG_ Led0011_value : 80|8@1+ (1,0) [0|255] "" Vector__XXX
 SG_ Led0010_value : 72|8@1+ (1,0) [0|255] "" Vector__XXX
 SG_ Led0009_value : 64|8@1+ (1,0) [0|255] "" Vector__XXX
 SG_ Led0008_value : 56|8@1+ (1,0) [0|255] "" Vector__XXX
 SG_ Led0007_value : 48|8@1+ (1,0) [0|255] "" Vector__XXX
 SG_ Led0006_value : 40|8@1+ (1,0) [0|255] "" Vector__XXX
 SG_ Led0005_value : 32|8@1+ (1,0) [0|255] "" Vector__XXX
 SG_ Led0004_value : 24|8@1+ (1,0) [0|255] "" Vector__XXX
 SG_ Led0003_value : 16|8@1+ (1,0) [0|255] "" Vector__XXX
 SG_ Led0002_value : 8|8@1+ (1,0) [0|255] "" Vector__XXX
 SG_ Led0001_value : 0|8@1+ (1,0) [0|255] "" Vector__XXX

BO_ 1049 ISC_Ctrl_LED_B_25: 64 ISC
 SG_ Led0064_value : 504|8@1+ (1,0) [0|255] "" Vector__XXX
 SG_ Led0063_value : 496|8@1+ (1,0) [0|255] "" Vector__XXX
 SG_ Led0062_value : 488|8@1+ (1,0) [0|255] "" Vector__XXX
 SG_ Led0061_value : 480|8@1+ (1,0) [0|255] "" Vector__XXX
 SG_ Led0060_value : 472|8@1+ (1,0) [0|255] "" Vector__XXX
 SG_ Led0059_value : 464|8@1+ (1,0) [0|255] "" Vector__XXX
 SG_ Led0058_value : 456|8@1+ (1,0) [0|255] "" Vector__XXX
 SG_ Led0057_value : 448|8@1+ (1,0) [0|255] "" Vector__XXX
 SG_ Led0056_value : 440|8@1+ (1,0) [0|255] "" Vector__XXX
 SG_ Led0055_value : 432|8@1+ (1,0) [0|255] "" Vector__XXX
 SG_ Led0054_value : 424|8@1+ (1,0) [0|255] "" Vector__XXX
 SG_ Led0053_value : 416|8@1+ (1,0) [0|255] "" Vector__XXX
 SG_ Led0052_value : 408|8@1+ (1,0) [0|255] "" Vector__XXX
 SG_ Led0051_value : 400|8@1+ (1,0) [0|255] "" Vector__XXX
 SG_ Led0050_value : 392|8@1+ (1,0) [0|255] "" Vector__XXX
 SG_ Led0049_value : 384|8@1+ (1,0) [0|255] "" Vector__XXX
 SG_ Led0048_value : 376|8@1+ (1,0) [0|255] "" Vector__XXX
 SG_ Led0047_value : 368|8@1+ (1,0) [0|255] "" Vector__XXX
 SG_ Led0046_value : 360|8@1+ (1,0) [0|255] "" Vector__XXX
 SG_ Led0045_value : 352|8@1+ (1,0) [0|255] "" Vector__XXX
 SG_ Led0044_value : 344|8@1+ (1,0) [0|255] "" Vector__XXX
 SG_ Led0043_value : 336|8@1+ (1,0) [0|255] "" Vector__XXX
 SG_ Led0042_value : 328|8@1+ (1,0) [0|255] "" Vector__XXX
 SG_ Led0041_value : 320|8@1+ (1,0) [0|255] "" Vector__XXX
 SG_ Led0040_value : 312|8@1+ (1,0) [0|255] "" Vector__XXX
 SG_ Led0039_value : 304|8@1+ (1,0) [0|255] "" Vector__XXX
 SG_ Led0038_value : 296|8@1+ (1,0) [0|255] "" Vector__XXX
 SG_ Led0037_value : 288|8@1+ (1,0) [0|255] "" Vector__XXX
 SG_ Led0036_value : 280|8@1+ (1,0) [0|255] "" Vector__XXX
 SG_ Led0035_value : 272|8@1+ (1,0) [0|255] "" Vector__XXX
 SG_ Led0034_value : 264|8@1+ (1,0) [0|255] "" Vector__XXX
 SG_ Led0033_value : 256|8@1+ (1,0) [0|255] "" Vector__XXX
 SG_ Led0032_value : 248|8@1+ (1,0) [0|255] "" Vector__XXX
 SG_ Led0031_value : 240|8@1+ (1,0) [0|255] "" Vector__XXX
 SG_ Led0030_value : 232|8@1+ (1,0) [0|255] "" Vector__XXX
 SG_ Led0029_value : 224|8@1+ (1,0) [0|255] "" Vector__XXX
 SG_ Led0028_value : 216|8@1+ (1,0) [0|255] "" Vector__XXX
 SG_ Led0027_value : 208|8@1+ (1,0) [0|255] "" Vector__XXX
 SG_ Led0026_value : 200|8@1+ (1,0) [0|255] "" Vector__XXX
 SG_ Led0025_value : 192|8@1+ (1,0) [0|255] "" Vector__XXX
 SG_ Led0024_value : 184|8@1+ (1,0) [0|255] "" Vector__XXX
 SG_ Led0023_value : 176|8@1+ (1,0) [0|255] "" Vector__XXX
 SG_ Led0022_value : 168|8@1+ (1,0) [0|255] "" Vector__XXX
 SG_ Led0021_value : 160|8@1+ (1,0) [0|255] "" Vector__XXX
 SG_ Led0020_value : 152|8@1+ (1,0) [0|255] "" Vector__XXX
 SG_ Led0019_value : 144|8@1+ (1,0) [0|255] "" Vector__XXX
 SG_ Led0018_value : 136|8@1+ (1,0) [0|255] "" Vector__XXX
 SG_ Led0017_value : 128|8@1+ (1,0) [0|255] "" Vector__XXX
 SG_ Led0016_value : 120|8@1+ (1,0) [0|255] "" Vector__XXX
 SG_ Led0015_value : 112|8@1+ (1,0) [0|255] "" Vector__XXX
 SG_ Led0014_value : 104|8@1+ (1,0) [0|255] "" Vector__XXX
 SG_ Led0013_value : 96|8@1+ (1,0) [0|255] "" Vector__XXX
 SG_ Led0012_value : 88|8@1+ (1,0) [0|255] "" Vector__XXX
 SG_ Led0011_value : 80|8@1+ (1,0) [0|255] "" Vector__XXX
 SG_ Led0010_value : 72|8@1+ (1,0) [0|255] "" Vector__XXX
 SG_ Led0009_value : 64|8@1+ (1,0) [0|255] "" Vector__XXX
 SG_ Led0008_value : 56|8@1+ (1,0) [0|255] "" Vector__XXX
 SG_ Led0007_value : 48|8@1+ (1,0) [0|255] "" Vector__XXX
 SG_ Led0006_value : 40|8@1+ (1,0) [0|255] "" Vector__XXX
 SG_ Led0005_value : 32|8@1+ (1,0) [0|255] "" Vector__XXX
 SG_ Led0004_value : 24|8@1+ (1,0) [0|255] "" Vector__XXX
 SG_ Led0003_value : 16|8@1+ (1,0) [0|255] "" Vector__XXX
 SG_ Led0002_value : 8|8@1+ (1,0) [0|255] "" Vector__XXX
 SG_ Led0001_value : 0|8@1+ (1,0) [0|255] "" Vector__XXX

BO_ 1048 ISC_Ctrl_LED_B_24: 64 ISC
 SG_ Led0064_value : 504|8@1+ (1,0) [0|255] "" Vector__XXX
 SG_ Led0063_value : 496|8@1+ (1,0) [0|255] "" Vector__XXX
 SG_ Led0062_value : 488|8@1+ (1,0) [0|255] "" Vector__XXX
 SG_ Led0061_value : 480|8@1+ (1,0) [0|255] "" Vector__XXX
 SG_ Led0060_value : 472|8@1+ (1,0) [0|255] "" Vector__XXX
 SG_ Led0059_value : 464|8@1+ (1,0) [0|255] "" Vector__XXX
 SG_ Led0058_value : 456|8@1+ (1,0) [0|255] "" Vector__XXX
 SG_ Led0057_value : 448|8@1+ (1,0) [0|255] "" Vector__XXX
 SG_ Led0056_value : 440|8@1+ (1,0) [0|255] "" Vector__XXX
 SG_ Led0055_value : 432|8@1+ (1,0) [0|255] "" Vector__XXX
 SG_ Led0054_value : 424|8@1+ (1,0) [0|255] "" Vector__XXX
 SG_ Led0053_value : 416|8@1+ (1,0) [0|255] "" Vector__XXX
 SG_ Led0052_value : 408|8@1+ (1,0) [0|255] "" Vector__XXX
 SG_ Led0051_value : 400|8@1+ (1,0) [0|255] "" Vector__XXX
 SG_ Led0050_value : 392|8@1+ (1,0) [0|255] "" Vector__XXX
 SG_ Led0049_value : 384|8@1+ (1,0) [0|255] "" Vector__XXX
 SG_ Led0048_value : 376|8@1+ (1,0) [0|255] "" Vector__XXX
 SG_ Led0047_value : 368|8@1+ (1,0) [0|255] "" Vector__XXX
 SG_ Led0046_value : 360|8@1+ (1,0) [0|255] "" Vector__XXX
 SG_ Led0045_value : 352|8@1+ (1,0) [0|255] "" Vector__XXX
 SG_ Led0044_value : 344|8@1+ (1,0) [0|255] "" Vector__XXX
 SG_ Led0043_value : 336|8@1+ (1,0) [0|255] "" Vector__XXX
 SG_ Led0042_value : 328|8@1+ (1,0) [0|255] "" Vector__XXX
 SG_ Led0041_value : 320|8@1+ (1,0) [0|255] "" Vector__XXX
 SG_ Led0040_value : 312|8@1+ (1,0) [0|255] "" Vector__XXX
 SG_ Led0039_value : 304|8@1+ (1,0) [0|255] "" Vector__XXX
 SG_ Led0038_value : 296|8@1+ (1,0) [0|255] "" Vector__XXX
 SG_ Led0037_value : 288|8@1+ (1,0) [0|255] "" Vector__XXX
 SG_ Led0036_value : 280|8@1+ (1,0) [0|255] "" Vector__XXX
 SG_ Led0035_value : 272|8@1+ (1,0) [0|255] "" Vector__XXX
 SG_ Led0034_value : 264|8@1+ (1,0) [0|255] "" Vector__XXX
 SG_ Led0033_value : 256|8@1+ (1,0) [0|255] "" Vector__XXX
 SG_ Led0032_value : 248|8@1+ (1,0) [0|255] "" Vector__XXX
 SG_ Led0031_value : 240|8@1+ (1,0) [0|255] "" Vector__XXX
 SG_ Led0030_value : 232|8@1+ (1,0) [0|255] "" Vector__XXX
 SG_ Led0029_value : 224|8@1+ (1,0) [0|255] "" Vector__XXX
 SG_ Led0028_value : 216|8@1+ (1,0) [0|255] "" Vector__XXX
 SG_ Led0027_value : 208|8@1+ (1,0) [0|255] "" Vector__XXX
 SG_ Led0026_value : 200|8@1+ (1,0) [0|255] "" Vector__XXX
 SG_ Led0025_value : 192|8@1+ (1,0) [0|255] "" Vector__XXX
 SG_ Led0024_value : 184|8@1+ (1,0) [0|255] "" Vector__XXX
 SG_ Led0023_value : 176|8@1+ (1,0) [0|255] "" Vector__XXX
 SG_ Led0022_value : 168|8@1+ (1,0) [0|255] "" Vector__XXX
 SG_ Led0021_value : 160|8@1+ (1,0) [0|255] "" Vector__XXX
 SG_ Led0020_value : 152|8@1+ (1,0) [0|255] "" Vector__XXX
 SG_ Led0019_value : 144|8@1+ (1,0) [0|255] "" Vector__XXX
 SG_ Led0018_value : 136|8@1+ (1,0) [0|255] "" Vector__XXX
 SG_ Led0017_value : 128|8@1+ (1,0) [0|255] "" Vector__XXX
 SG_ Led0016_value : 120|8@1+ (1,0) [0|255] "" Vector__XXX
 SG_ Led0015_value : 112|8@1+ (1,0) [0|255] "" Vector__XXX
 SG_ Led0014_value : 104|8@1+ (1,0) [0|255] "" Vector__XXX
 SG_ Led0013_value : 96|8@1+ (1,0) [0|255] "" Vector__XXX
 SG_ Led0012_value : 88|8@1+ (1,0) [0|255] "" Vector__XXX
 SG_ Led0011_value : 80|8@1+ (1,0) [0|255] "" Vector__XXX
 SG_ Led0010_value : 72|8@1+ (1,0) [0|255] "" Vector__XXX
 SG_ Led0009_value : 64|8@1+ (1,0) [0|255] "" Vector__XXX
 SG_ Led0008_value : 56|8@1+ (1,0) [0|255] "" Vector__XXX
 SG_ Led0007_value : 48|8@1+ (1,0) [0|255] "" Vector__XXX
 SG_ Led0006_value : 40|8@1+ (1,0) [0|255] "" Vector__XXX
 SG_ Led0005_value : 32|8@1+ (1,0) [0|255] "" Vector__XXX
 SG_ Led0004_value : 24|8@1+ (1,0) [0|255] "" Vector__XXX
 SG_ Led0003_value : 16|8@1+ (1,0) [0|255] "" Vector__XXX
 SG_ Led0002_value : 8|8@1+ (1,0) [0|255] "" Vector__XXX
 SG_ Led0001_value : 0|8@1+ (1,0) [0|255] "" Vector__XXX

BO_ 1047 ISC_Ctrl_LED_B_23: 64 ISC
 SG_ Led0064_value : 504|8@1+ (1,0) [0|255] "" Vector__XXX
 SG_ Led0063_value : 496|8@1+ (1,0) [0|255] "" Vector__XXX
 SG_ Led0062_value : 488|8@1+ (1,0) [0|255] "" Vector__XXX
 SG_ Led0061_value : 480|8@1+ (1,0) [0|255] "" Vector__XXX
 SG_ Led0060_value : 472|8@1+ (1,0) [0|255] "" Vector__XXX
 SG_ Led0059_value : 464|8@1+ (1,0) [0|255] "" Vector__XXX
 SG_ Led0058_value : 456|8@1+ (1,0) [0|255] "" Vector__XXX
 SG_ Led0057_value : 448|8@1+ (1,0) [0|255] "" Vector__XXX
 SG_ Led0056_value : 440|8@1+ (1,0) [0|255] "" Vector__XXX
 SG_ Led0055_value : 432|8@1+ (1,0) [0|255] "" Vector__XXX
 SG_ Led0054_value : 424|8@1+ (1,0) [0|255] "" Vector__XXX
 SG_ Led0053_value : 416|8@1+ (1,0) [0|255] "" Vector__XXX
 SG_ Led0052_value : 408|8@1+ (1,0) [0|255] "" Vector__XXX
 SG_ Led0051_value : 400|8@1+ (1,0) [0|255] "" Vector__XXX
 SG_ Led0050_value : 392|8@1+ (1,0) [0|255] "" Vector__XXX
 SG_ Led0049_value : 384|8@1+ (1,0) [0|255] "" Vector__XXX
 SG_ Led0048_value : 376|8@1+ (1,0) [0|255] "" Vector__XXX
 SG_ Led0047_value : 368|8@1+ (1,0) [0|255] "" Vector__XXX
 SG_ Led0046_value : 360|8@1+ (1,0) [0|255] "" Vector__XXX
 SG_ Led0045_value : 352|8@1+ (1,0) [0|255] "" Vector__XXX
 SG_ Led0044_value : 344|8@1+ (1,0) [0|255] "" Vector__XXX
 SG_ Led0043_value : 336|8@1+ (1,0) [0|255] "" Vector__XXX
 SG_ Led0042_value : 328|8@1+ (1,0) [0|255] "" Vector__XXX
 SG_ Led0041_value : 320|8@1+ (1,0) [0|255] "" Vector__XXX
 SG_ Led0040_value : 312|8@1+ (1,0) [0|255] "" Vector__XXX
 SG_ Led0039_value : 304|8@1+ (1,0) [0|255] "" Vector__XXX
 SG_ Led0038_value : 296|8@1+ (1,0) [0|255] "" Vector__XXX
 SG_ Led0037_value : 288|8@1+ (1,0) [0|255] "" Vector__XXX
 SG_ Led0036_value : 280|8@1+ (1,0) [0|255] "" Vector__XXX
 SG_ Led0035_value : 272|8@1+ (1,0) [0|255] "" Vector__XXX
 SG_ Led0034_value : 264|8@1+ (1,0) [0|255] "" Vector__XXX
 SG_ Led0033_value : 256|8@1+ (1,0) [0|255] "" Vector__XXX
 SG_ Led0032_value : 248|8@1+ (1,0) [0|255] "" Vector__XXX
 SG_ Led0031_value : 240|8@1+ (1,0) [0|255] "" Vector__XXX
 SG_ Led0030_value : 232|8@1+ (1,0) [0|255] "" Vector__XXX
 SG_ Led0029_value : 224|8@1+ (1,0) [0|255] "" Vector__XXX
 SG_ Led0028_value : 216|8@1+ (1,0) [0|255] "" Vector__XXX
 SG_ Led0027_value : 208|8@1+ (1,0) [0|255] "" Vector__XXX
 SG_ Led0026_value : 200|8@1+ (1,0) [0|255] "" Vector__XXX
 SG_ Led0025_value : 192|8@1+ (1,0) [0|255] "" Vector__XXX
 SG_ Led0024_value : 184|8@1+ (1,0) [0|255] "" Vector__XXX
 SG_ Led0023_value : 176|8@1+ (1,0) [0|255] "" Vector__XXX
 SG_ Led0022_value : 168|8@1+ (1,0) [0|255] "" Vector__XXX
 SG_ Led0021_value : 160|8@1+ (1,0) [0|255] "" Vector__XXX
 SG_ Led0020_value : 152|8@1+ (1,0) [0|255] "" Vector__XXX
 SG_ Led0019_value : 144|8@1+ (1,0) [0|255] "" Vector__XXX
 SG_ Led0018_value : 136|8@1+ (1,0) [0|255] "" Vector__XXX
 SG_ Led0017_value : 128|8@1+ (1,0) [0|255] "" Vector__XXX
 SG_ Led0016_value : 120|8@1+ (1,0) [0|255] "" Vector__XXX
 SG_ Led0015_value : 112|8@1+ (1,0) [0|255] "" Vector__XXX
 SG_ Led0014_value : 104|8@1+ (1,0) [0|255] "" Vector__XXX
 SG_ Led0013_value : 96|8@1+ (1,0) [0|255] "" Vector__XXX
 SG_ Led0012_value : 88|8@1+ (1,0) [0|255] "" Vector__XXX
 SG_ Led0011_value : 80|8@1+ (1,0) [0|255] "" Vector__XXX
 SG_ Led0010_value : 72|8@1+ (1,0) [0|255] "" Vector__XXX
 SG_ Led0009_value : 64|8@1+ (1,0) [0|255] "" Vector__XXX
 SG_ Led0008_value : 56|8@1+ (1,0) [0|255] "" Vector__XXX
 SG_ Led0007_value : 48|8@1+ (1,0) [0|255] "" Vector__XXX
 SG_ Led0006_value : 40|8@1+ (1,0) [0|255] "" Vector__XXX
 SG_ Led0005_value : 32|8@1+ (1,0) [0|255] "" Vector__XXX
 SG_ Led0004_value : 24|8@1+ (1,0) [0|255] "" Vector__XXX
 SG_ Led0003_value : 16|8@1+ (1,0) [0|255] "" Vector__XXX
 SG_ Led0002_value : 8|8@1+ (1,0) [0|255] "" Vector__XXX
 SG_ Led0001_value : 0|8@1+ (1,0) [0|255] "" Vector__XXX

BO_ 1046 ISC_Ctrl_LED_B_22: 64 ISC
 SG_ Led0064_value : 504|8@1+ (1,0) [0|255] "" Vector__XXX
 SG_ Led0063_value : 496|8@1+ (1,0) [0|255] "" Vector__XXX
 SG_ Led0062_value : 488|8@1+ (1,0) [0|255] "" Vector__XXX
 SG_ Led0061_value : 480|8@1+ (1,0) [0|255] "" Vector__XXX
 SG_ Led0060_value : 472|8@1+ (1,0) [0|255] "" Vector__XXX
 SG_ Led0059_value : 464|8@1+ (1,0) [0|255] "" Vector__XXX
 SG_ Led0058_value : 456|8@1+ (1,0) [0|255] "" Vector__XXX
 SG_ Led0057_value : 448|8@1+ (1,0) [0|255] "" Vector__XXX
 SG_ Led0056_value : 440|8@1+ (1,0) [0|255] "" Vector__XXX
 SG_ Led0055_value : 432|8@1+ (1,0) [0|255] "" Vector__XXX
 SG_ Led0054_value : 424|8@1+ (1,0) [0|255] "" Vector__XXX
 SG_ Led0053_value : 416|8@1+ (1,0) [0|255] "" Vector__XXX
 SG_ Led0052_value : 408|8@1+ (1,0) [0|255] "" Vector__XXX
 SG_ Led0051_value : 400|8@1+ (1,0) [0|255] "" Vector__XXX
 SG_ Led0050_value : 392|8@1+ (1,0) [0|255] "" Vector__XXX
 SG_ Led0049_value : 384|8@1+ (1,0) [0|255] "" Vector__XXX
 SG_ Led0048_value : 376|8@1+ (1,0) [0|255] "" Vector__XXX
 SG_ Led0047_value : 368|8@1+ (1,0) [0|255] "" Vector__XXX
 SG_ Led0046_value : 360|8@1+ (1,0) [0|255] "" Vector__XXX
 SG_ Led0045_value : 352|8@1+ (1,0) [0|255] "" Vector__XXX
 SG_ Led0044_value : 344|8@1+ (1,0) [0|255] "" Vector__XXX
 SG_ Led0043_value : 336|8@1+ (1,0) [0|255] "" Vector__XXX
 SG_ Led0042_value : 328|8@1+ (1,0) [0|255] "" Vector__XXX
 SG_ Led0041_value : 320|8@1+ (1,0) [0|255] "" Vector__XXX
 SG_ Led0040_value : 312|8@1+ (1,0) [0|255] "" Vector__XXX
 SG_ Led0039_value : 304|8@1+ (1,0) [0|255] "" Vector__XXX
 SG_ Led0038_value : 296|8@1+ (1,0) [0|255] "" Vector__XXX
 SG_ Led0037_value : 288|8@1+ (1,0) [0|255] "" Vector__XXX
 SG_ Led0036_value : 280|8@1+ (1,0) [0|255] "" Vector__XXX
 SG_ Led0035_value : 272|8@1+ (1,0) [0|255] "" Vector__XXX
 SG_ Led0034_value : 264|8@1+ (1,0) [0|255] "" Vector__XXX
 SG_ Led0033_value : 256|8@1+ (1,0) [0|255] "" Vector__XXX
 SG_ Led0032_value : 248|8@1+ (1,0) [0|255] "" Vector__XXX
 SG_ Led0031_value : 240|8@1+ (1,0) [0|255] "" Vector__XXX
 SG_ Led0030_value : 232|8@1+ (1,0) [0|255] "" Vector__XXX
 SG_ Led0029_value : 224|8@1+ (1,0) [0|255] "" Vector__XXX
 SG_ Led0028_value : 216|8@1+ (1,0) [0|255] "" Vector__XXX
 SG_ Led0027_value : 208|8@1+ (1,0) [0|255] "" Vector__XXX
 SG_ Led0026_value : 200|8@1+ (1,0) [0|255] "" Vector__XXX
 SG_ Led0025_value : 192|8@1+ (1,0) [0|255] "" Vector__XXX
 SG_ Led0024_value : 184|8@1+ (1,0) [0|255] "" Vector__XXX
 SG_ Led0023_value : 176|8@1+ (1,0) [0|255] "" Vector__XXX
 SG_ Led0022_value : 168|8@1+ (1,0) [0|255] "" Vector__XXX
 SG_ Led0021_value : 160|8@1+ (1,0) [0|255] "" Vector__XXX
 SG_ Led0020_value : 152|8@1+ (1,0) [0|255] "" Vector__XXX
 SG_ Led0019_value : 144|8@1+ (1,0) [0|255] "" Vector__XXX
 SG_ Led0018_value : 136|8@1+ (1,0) [0|255] "" Vector__XXX
 SG_ Led0017_value : 128|8@1+ (1,0) [0|255] "" Vector__XXX
 SG_ Led0016_value : 120|8@1+ (1,0) [0|255] "" Vector__XXX
 SG_ Led0015_value : 112|8@1+ (1,0) [0|255] "" Vector__XXX
 SG_ Led0014_value : 104|8@1+ (1,0) [0|255] "" Vector__XXX
 SG_ Led0013_value : 96|8@1+ (1,0) [0|255] "" Vector__XXX
 SG_ Led0012_value : 88|8@1+ (1,0) [0|255] "" Vector__XXX
 SG_ Led0011_value : 80|8@1+ (1,0) [0|255] "" Vector__XXX
 SG_ Led0010_value : 72|8@1+ (1,0) [0|255] "" Vector__XXX
 SG_ Led0009_value : 64|8@1+ (1,0) [0|255] "" Vector__XXX
 SG_ Led0008_value : 56|8@1+ (1,0) [0|255] "" Vector__XXX
 SG_ Led0007_value : 48|8@1+ (1,0) [0|255] "" Vector__XXX
 SG_ Led0006_value : 40|8@1+ (1,0) [0|255] "" Vector__XXX
 SG_ Led0005_value : 32|8@1+ (1,0) [0|255] "" Vector__XXX
 SG_ Led0004_value : 24|8@1+ (1,0) [0|255] "" Vector__XXX
 SG_ Led0003_value : 16|8@1+ (1,0) [0|255] "" Vector__XXX
 SG_ Led0002_value : 8|8@1+ (1,0) [0|255] "" Vector__XXX
 SG_ Led0001_value : 0|8@1+ (1,0) [0|255] "" Vector__XXX

BO_ 1045 ISC_Ctrl_LED_B_21: 64 ISC
 SG_ Led0064_value : 504|8@1+ (1,0) [0|255] "" Vector__XXX
 SG_ Led0063_value : 496|8@1+ (1,0) [0|255] "" Vector__XXX
 SG_ Led0062_value : 488|8@1+ (1,0) [0|255] "" Vector__XXX
 SG_ Led0061_value : 480|8@1+ (1,0) [0|255] "" Vector__XXX
 SG_ Led0060_value : 472|8@1+ (1,0) [0|255] "" Vector__XXX
 SG_ Led0059_value : 464|8@1+ (1,0) [0|255] "" Vector__XXX
 SG_ Led0058_value : 456|8@1+ (1,0) [0|255] "" Vector__XXX
 SG_ Led0057_value : 448|8@1+ (1,0) [0|255] "" Vector__XXX
 SG_ Led0056_value : 440|8@1+ (1,0) [0|255] "" Vector__XXX
 SG_ Led0055_value : 432|8@1+ (1,0) [0|255] "" Vector__XXX
 SG_ Led0054_value : 424|8@1+ (1,0) [0|255] "" Vector__XXX
 SG_ Led0053_value : 416|8@1+ (1,0) [0|255] "" Vector__XXX
 SG_ Led0052_value : 408|8@1+ (1,0) [0|255] "" Vector__XXX
 SG_ Led0051_value : 400|8@1+ (1,0) [0|255] "" Vector__XXX
 SG_ Led0050_value : 392|8@1+ (1,0) [0|255] "" Vector__XXX
 SG_ Led0049_value : 384|8@1+ (1,0) [0|255] "" Vector__XXX
 SG_ Led0048_value : 376|8@1+ (1,0) [0|255] "" Vector__XXX
 SG_ Led0047_value : 368|8@1+ (1,0) [0|255] "" Vector__XXX
 SG_ Led0046_value : 360|8@1+ (1,0) [0|255] "" Vector__XXX
 SG_ Led0045_value : 352|8@1+ (1,0) [0|255] "" Vector__XXX
 SG_ Led0044_value : 344|8@1+ (1,0) [0|255] "" Vector__XXX
 SG_ Led0043_value : 336|8@1+ (1,0) [0|255] "" Vector__XXX
 SG_ Led0042_value : 328|8@1+ (1,0) [0|255] "" Vector__XXX
 SG_ Led0041_value : 320|8@1+ (1,0) [0|255] "" Vector__XXX
 SG_ Led0040_value : 312|8@1+ (1,0) [0|255] "" Vector__XXX
 SG_ Led0039_value : 304|8@1+ (1,0) [0|255] "" Vector__XXX
 SG_ Led0038_value : 296|8@1+ (1,0) [0|255] "" Vector__XXX
 SG_ Led0037_value : 288|8@1+ (1,0) [0|255] "" Vector__XXX
 SG_ Led0036_value : 280|8@1+ (1,0) [0|255] "" Vector__XXX
 SG_ Led0035_value : 272|8@1+ (1,0) [0|255] "" Vector__XXX
 SG_ Led0034_value : 264|8@1+ (1,0) [0|255] "" Vector__XXX
 SG_ Led0033_value : 256|8@1+ (1,0) [0|255] "" Vector__XXX
 SG_ Led0032_value : 248|8@1+ (1,0) [0|255] "" Vector__XXX
 SG_ Led0031_value : 240|8@1+ (1,0) [0|255] "" Vector__XXX
 SG_ Led0030_value : 232|8@1+ (1,0) [0|255] "" Vector__XXX
 SG_ Led0029_value : 224|8@1+ (1,0) [0|255] "" Vector__XXX
 SG_ Led0028_value : 216|8@1+ (1,0) [0|255] "" Vector__XXX
 SG_ Led0027_value : 208|8@1+ (1,0) [0|255] "" Vector__XXX
 SG_ Led0026_value : 200|8@1+ (1,0) [0|255] "" Vector__XXX
 SG_ Led0025_value : 192|8@1+ (1,0) [0|255] "" Vector__XXX
 SG_ Led0024_value : 184|8@1+ (1,0) [0|255] "" Vector__XXX
 SG_ Led0023_value : 176|8@1+ (1,0) [0|255] "" Vector__XXX
 SG_ Led0022_value : 168|8@1+ (1,0) [0|255] "" Vector__XXX
 SG_ Led0021_value : 160|8@1+ (1,0) [0|255] "" Vector__XXX
 SG_ Led0020_value : 152|8@1+ (1,0) [0|255] "" Vector__XXX
 SG_ Led0019_value : 144|8@1+ (1,0) [0|255] "" Vector__XXX
 SG_ Led0018_value : 136|8@1+ (1,0) [0|255] "" Vector__XXX
 SG_ Led0017_value : 128|8@1+ (1,0) [0|255] "" Vector__XXX
 SG_ Led0016_value : 120|8@1+ (1,0) [0|255] "" Vector__XXX
 SG_ Led0015_value : 112|8@1+ (1,0) [0|255] "" Vector__XXX
 SG_ Led0014_value : 104|8@1+ (1,0) [0|255] "" Vector__XXX
 SG_ Led0013_value : 96|8@1+ (1,0) [0|255] "" Vector__XXX
 SG_ Led0012_value : 88|8@1+ (1,0) [0|255] "" Vector__XXX
 SG_ Led0011_value : 80|8@1+ (1,0) [0|255] "" Vector__XXX
 SG_ Led0010_value : 72|8@1+ (1,0) [0|255] "" Vector__XXX
 SG_ Led0009_value : 64|8@1+ (1,0) [0|255] "" Vector__XXX
 SG_ Led0008_value : 56|8@1+ (1,0) [0|255] "" Vector__XXX
 SG_ Led0007_value : 48|8@1+ (1,0) [0|255] "" Vector__XXX
 SG_ Led0006_value : 40|8@1+ (1,0) [0|255] "" Vector__XXX
 SG_ Led0005_value : 32|8@1+ (1,0) [0|255] "" Vector__XXX
 SG_ Led0004_value : 24|8@1+ (1,0) [0|255] "" Vector__XXX
 SG_ Led0003_value : 16|8@1+ (1,0) [0|255] "" Vector__XXX
 SG_ Led0002_value : 8|8@1+ (1,0) [0|255] "" Vector__XXX
 SG_ Led0001_value : 0|8@1+ (1,0) [0|255] "" Vector__XXX

BO_ 1044 ISC_Ctrl_LED_B_20: 64 ISC
 SG_ Led0064_value : 504|8@1+ (1,0) [0|255] "" Vector__XXX
 SG_ Led0063_value : 496|8@1+ (1,0) [0|255] "" Vector__XXX
 SG_ Led0062_value : 488|8@1+ (1,0) [0|255] "" Vector__XXX
 SG_ Led0061_value : 480|8@1+ (1,0) [0|255] "" Vector__XXX
 SG_ Led0060_value : 472|8@1+ (1,0) [0|255] "" Vector__XXX
 SG_ Led0059_value : 464|8@1+ (1,0) [0|255] "" Vector__XXX
 SG_ Led0058_value : 456|8@1+ (1,0) [0|255] "" Vector__XXX
 SG_ Led0057_value : 448|8@1+ (1,0) [0|255] "" Vector__XXX
 SG_ Led0056_value : 440|8@1+ (1,0) [0|255] "" Vector__XXX
 SG_ Led0055_value : 432|8@1+ (1,0) [0|255] "" Vector__XXX
 SG_ Led0054_value : 424|8@1+ (1,0) [0|255] "" Vector__XXX
 SG_ Led0053_value : 416|8@1+ (1,0) [0|255] "" Vector__XXX
 SG_ Led0052_value : 408|8@1+ (1,0) [0|255] "" Vector__XXX
 SG_ Led0051_value : 400|8@1+ (1,0) [0|255] "" Vector__XXX
 SG_ Led0050_value : 392|8@1+ (1,0) [0|255] "" Vector__XXX
 SG_ Led0049_value : 384|8@1+ (1,0) [0|255] "" Vector__XXX
 SG_ Led0048_value : 376|8@1+ (1,0) [0|255] "" Vector__XXX
 SG_ Led0047_value : 368|8@1+ (1,0) [0|255] "" Vector__XXX
 SG_ Led0046_value : 360|8@1+ (1,0) [0|255] "" Vector__XXX
 SG_ Led0045_value : 352|8@1+ (1,0) [0|255] "" Vector__XXX
 SG_ Led0044_value : 344|8@1+ (1,0) [0|255] "" Vector__XXX
 SG_ Led0043_value : 336|8@1+ (1,0) [0|255] "" Vector__XXX
 SG_ Led0042_value : 328|8@1+ (1,0) [0|255] "" Vector__XXX
 SG_ Led0041_value : 320|8@1+ (1,0) [0|255] "" Vector__XXX
 SG_ Led0040_value : 312|8@1+ (1,0) [0|255] "" Vector__XXX
 SG_ Led0039_value : 304|8@1+ (1,0) [0|255] "" Vector__XXX
 SG_ Led0038_value : 296|8@1+ (1,0) [0|255] "" Vector__XXX
 SG_ Led0037_value : 288|8@1+ (1,0) [0|255] "" Vector__XXX
 SG_ Led0036_value : 280|8@1+ (1,0) [0|255] "" Vector__XXX
 SG_ Led0035_value : 272|8@1+ (1,0) [0|255] "" Vector__XXX
 SG_ Led0034_value : 264|8@1+ (1,0) [0|255] "" Vector__XXX
 SG_ Led0033_value : 256|8@1+ (1,0) [0|255] "" Vector__XXX
 SG_ Led0032_value : 248|8@1+ (1,0) [0|255] "" Vector__XXX
 SG_ Led0031_value : 240|8@1+ (1,0) [0|255] "" Vector__XXX
 SG_ Led0030_value : 232|8@1+ (1,0) [0|255] "" Vector__XXX
 SG_ Led0029_value : 224|8@1+ (1,0) [0|255] "" Vector__XXX
 SG_ Led0028_value : 216|8@1+ (1,0) [0|255] "" Vector__XXX
 SG_ Led0027_value : 208|8@1+ (1,0) [0|255] "" Vector__XXX
 SG_ Led0026_value : 200|8@1+ (1,0) [0|255] "" Vector__XXX
 SG_ Led0025_value : 192|8@1+ (1,0) [0|255] "" Vector__XXX
 SG_ Led0024_value : 184|8@1+ (1,0) [0|255] "" Vector__XXX
 SG_ Led0023_value : 176|8@1+ (1,0) [0|255] "" Vector__XXX
 SG_ Led0022_value : 168|8@1+ (1,0) [0|255] "" Vector__XXX
 SG_ Led0021_value : 160|8@1+ (1,0) [0|255] "" Vector__XXX
 SG_ Led0020_value : 152|8@1+ (1,0) [0|255] "" Vector__XXX
 SG_ Led0019_value : 144|8@1+ (1,0) [0|255] "" Vector__XXX
 SG_ Led0018_value : 136|8@1+ (1,0) [0|255] "" Vector__XXX
 SG_ Led0017_value : 128|8@1+ (1,0) [0|255] "" Vector__XXX
 SG_ Led0016_value : 120|8@1+ (1,0) [0|255] "" Vector__XXX
 SG_ Led0015_value : 112|8@1+ (1,0) [0|255] "" Vector__XXX
 SG_ Led0014_value : 104|8@1+ (1,0) [0|255] "" Vector__XXX
 SG_ Led0013_value : 96|8@1+ (1,0) [0|255] "" Vector__XXX
 SG_ Led0012_value : 88|8@1+ (1,0) [0|255] "" Vector__XXX
 SG_ Led0011_value : 80|8@1+ (1,0) [0|255] "" Vector__XXX
 SG_ Led0010_value : 72|8@1+ (1,0) [0|255] "" Vector__XXX
 SG_ Led0009_value : 64|8@1+ (1,0) [0|255] "" Vector__XXX
 SG_ Led0008_value : 56|8@1+ (1,0) [0|255] "" Vector__XXX
 SG_ Led0007_value : 48|8@1+ (1,0) [0|255] "" Vector__XXX
 SG_ Led0006_value : 40|8@1+ (1,0) [0|255] "" Vector__XXX
 SG_ Led0005_value : 32|8@1+ (1,0) [0|255] "" Vector__XXX
 SG_ Led0004_value : 24|8@1+ (1,0) [0|255] "" Vector__XXX
 SG_ Led0003_value : 16|8@1+ (1,0) [0|255] "" Vector__XXX
 SG_ Led0002_value : 8|8@1+ (1,0) [0|255] "" Vector__XXX
 SG_ Led0001_value : 0|8@1+ (1,0) [0|255] "" Vector__XXX

BO_ 1043 ISC_Ctrl_LED_B_19: 64 ISC
 SG_ Led0064_value : 504|8@1+ (1,0) [0|255] "" Vector__XXX
 SG_ Led0063_value : 496|8@1+ (1,0) [0|255] "" Vector__XXX
 SG_ Led0062_value : 488|8@1+ (1,0) [0|255] "" Vector__XXX
 SG_ Led0061_value : 480|8@1+ (1,0) [0|255] "" Vector__XXX
 SG_ Led0060_value : 472|8@1+ (1,0) [0|255] "" Vector__XXX
 SG_ Led0059_value : 464|8@1+ (1,0) [0|255] "" Vector__XXX
 SG_ Led0058_value : 456|8@1+ (1,0) [0|255] "" Vector__XXX
 SG_ Led0057_value : 448|8@1+ (1,0) [0|255] "" Vector__XXX
 SG_ Led0056_value : 440|8@1+ (1,0) [0|255] "" Vector__XXX
 SG_ Led0055_value : 432|8@1+ (1,0) [0|255] "" Vector__XXX
 SG_ Led0054_value : 424|8@1+ (1,0) [0|255] "" Vector__XXX
 SG_ Led0053_value : 416|8@1+ (1,0) [0|255] "" Vector__XXX
 SG_ Led0052_value : 408|8@1+ (1,0) [0|255] "" Vector__XXX
 SG_ Led0051_value : 400|8@1+ (1,0) [0|255] "" Vector__XXX
 SG_ Led0050_value : 392|8@1+ (1,0) [0|255] "" Vector__XXX
 SG_ Led0049_value : 384|8@1+ (1,0) [0|255] "" Vector__XXX
 SG_ Led0048_value : 376|8@1+ (1,0) [0|255] "" Vector__XXX
 SG_ Led0047_value : 368|8@1+ (1,0) [0|255] "" Vector__XXX
 SG_ Led0046_value : 360|8@1+ (1,0) [0|255] "" Vector__XXX
 SG_ Led0045_value : 352|8@1+ (1,0) [0|255] "" Vector__XXX
 SG_ Led0044_value : 344|8@1+ (1,0) [0|255] "" Vector__XXX
 SG_ Led0043_value : 336|8@1+ (1,0) [0|255] "" Vector__XXX
 SG_ Led0042_value : 328|8@1+ (1,0) [0|255] "" Vector__XXX
 SG_ Led0041_value : 320|8@1+ (1,0) [0|255] "" Vector__XXX
 SG_ Led0040_value : 312|8@1+ (1,0) [0|255] "" Vector__XXX
 SG_ Led0039_value : 304|8@1+ (1,0) [0|255] "" Vector__XXX
 SG_ Led0038_value : 296|8@1+ (1,0) [0|255] "" Vector__XXX
 SG_ Led0037_value : 288|8@1+ (1,0) [0|255] "" Vector__XXX
 SG_ Led0036_value : 280|8@1+ (1,0) [0|255] "" Vector__XXX
 SG_ Led0035_value : 272|8@1+ (1,0) [0|255] "" Vector__XXX
 SG_ Led0034_value : 264|8@1+ (1,0) [0|255] "" Vector__XXX
 SG_ Led0033_value : 256|8@1+ (1,0) [0|255] "" Vector__XXX
 SG_ Led0032_value : 248|8@1+ (1,0) [0|255] "" Vector__XXX
 SG_ Led0031_value : 240|8@1+ (1,0) [0|255] "" Vector__XXX
 SG_ Led0030_value : 232|8@1+ (1,0) [0|255] "" Vector__XXX
 SG_ Led0029_value : 224|8@1+ (1,0) [0|255] "" Vector__XXX
 SG_ Led0028_value : 216|8@1+ (1,0) [0|255] "" Vector__XXX
 SG_ Led0027_value : 208|8@1+ (1,0) [0|255] "" Vector__XXX
 SG_ Led0026_value : 200|8@1+ (1,0) [0|255] "" Vector__XXX
 SG_ Led0025_value : 192|8@1+ (1,0) [0|255] "" Vector__XXX
 SG_ Led0024_value : 184|8@1+ (1,0) [0|255] "" Vector__XXX
 SG_ Led0023_value : 176|8@1+ (1,0) [0|255] "" Vector__XXX
 SG_ Led0022_value : 168|8@1+ (1,0) [0|255] "" Vector__XXX
 SG_ Led0021_value : 160|8@1+ (1,0) [0|255] "" Vector__XXX
 SG_ Led0020_value : 152|8@1+ (1,0) [0|255] "" Vector__XXX
 SG_ Led0019_value : 144|8@1+ (1,0) [0|255] "" Vector__XXX
 SG_ Led0018_value : 136|8@1+ (1,0) [0|255] "" Vector__XXX
 SG_ Led0017_value : 128|8@1+ (1,0) [0|255] "" Vector__XXX
 SG_ Led0016_value : 120|8@1+ (1,0) [0|255] "" Vector__XXX
 SG_ Led0015_value : 112|8@1+ (1,0) [0|255] "" Vector__XXX
 SG_ Led0014_value : 104|8@1+ (1,0) [0|255] "" Vector__XXX
 SG_ Led0013_value : 96|8@1+ (1,0) [0|255] "" Vector__XXX
 SG_ Led0012_value : 88|8@1+ (1,0) [0|255] "" Vector__XXX
 SG_ Led0011_value : 80|8@1+ (1,0) [0|255] "" Vector__XXX
 SG_ Led0010_value : 72|8@1+ (1,0) [0|255] "" Vector__XXX
 SG_ Led0009_value : 64|8@1+ (1,0) [0|255] "" Vector__XXX
 SG_ Led0008_value : 56|8@1+ (1,0) [0|255] "" Vector__XXX
 SG_ Led0007_value : 48|8@1+ (1,0) [0|255] "" Vector__XXX
 SG_ Led0006_value : 40|8@1+ (1,0) [0|255] "" Vector__XXX
 SG_ Led0005_value : 32|8@1+ (1,0) [0|255] "" Vector__XXX
 SG_ Led0004_value : 24|8@1+ (1,0) [0|255] "" Vector__XXX
 SG_ Led0003_value : 16|8@1+ (1,0) [0|255] "" Vector__XXX
 SG_ Led0002_value : 8|8@1+ (1,0) [0|255] "" Vector__XXX
 SG_ Led0001_value : 0|8@1+ (1,0) [0|255] "" Vector__XXX

BO_ 1042 ISC_Ctrl_LED_B_18: 64 ISC
 SG_ Led0064_value : 504|8@1+ (1,0) [0|255] "" Vector__XXX
 SG_ Led0063_value : 496|8@1+ (1,0) [0|255] "" Vector__XXX
 SG_ Led0062_value : 488|8@1+ (1,0) [0|255] "" Vector__XXX
 SG_ Led0061_value : 480|8@1+ (1,0) [0|255] "" Vector__XXX
 SG_ Led0060_value : 472|8@1+ (1,0) [0|255] "" Vector__XXX
 SG_ Led0059_value : 464|8@1+ (1,0) [0|255] "" Vector__XXX
 SG_ Led0058_value : 456|8@1+ (1,0) [0|255] "" Vector__XXX
 SG_ Led0057_value : 448|8@1+ (1,0) [0|255] "" Vector__XXX
 SG_ Led0056_value : 440|8@1+ (1,0) [0|255] "" Vector__XXX
 SG_ Led0055_value : 432|8@1+ (1,0) [0|255] "" Vector__XXX
 SG_ Led0054_value : 424|8@1+ (1,0) [0|255] "" Vector__XXX
 SG_ Led0053_value : 416|8@1+ (1,0) [0|255] "" Vector__XXX
 SG_ Led0052_value : 408|8@1+ (1,0) [0|255] "" Vector__XXX
 SG_ Led0051_value : 400|8@1+ (1,0) [0|255] "" Vector__XXX
 SG_ Led0050_value : 392|8@1+ (1,0) [0|255] "" Vector__XXX
 SG_ Led0049_value : 384|8@1+ (1,0) [0|255] "" Vector__XXX
 SG_ Led0048_value : 376|8@1+ (1,0) [0|255] "" Vector__XXX
 SG_ Led0047_value : 368|8@1+ (1,0) [0|255] "" Vector__XXX
 SG_ Led0046_value : 360|8@1+ (1,0) [0|255] "" Vector__XXX
 SG_ Led0045_value : 352|8@1+ (1,0) [0|255] "" Vector__XXX
 SG_ Led0044_value : 344|8@1+ (1,0) [0|255] "" Vector__XXX
 SG_ Led0043_value : 336|8@1+ (1,0) [0|255] "" Vector__XXX
 SG_ Led0042_value : 328|8@1+ (1,0) [0|255] "" Vector__XXX
 SG_ Led0041_value : 320|8@1+ (1,0) [0|255] "" Vector__XXX
 SG_ Led0040_value : 312|8@1+ (1,0) [0|255] "" Vector__XXX
 SG_ Led0039_value : 304|8@1+ (1,0) [0|255] "" Vector__XXX
 SG_ Led0038_value : 296|8@1+ (1,0) [0|255] "" Vector__XXX
 SG_ Led0037_value : 288|8@1+ (1,0) [0|255] "" Vector__XXX
 SG_ Led0036_value : 280|8@1+ (1,0) [0|255] "" Vector__XXX
 SG_ Led0035_value : 272|8@1+ (1,0) [0|255] "" Vector__XXX
 SG_ Led0034_value : 264|8@1+ (1,0) [0|255] "" Vector__XXX
 SG_ Led0033_value : 256|8@1+ (1,0) [0|255] "" Vector__XXX
 SG_ Led0032_value : 248|8@1+ (1,0) [0|255] "" Vector__XXX
 SG_ Led0031_value : 240|8@1+ (1,0) [0|255] "" Vector__XXX
 SG_ Led0030_value : 232|8@1+ (1,0) [0|255] "" Vector__XXX
 SG_ Led0029_value : 224|8@1+ (1,0) [0|255] "" Vector__XXX
 SG_ Led0028_value : 216|8@1+ (1,0) [0|255] "" Vector__XXX
 SG_ Led0027_value : 208|8@1+ (1,0) [0|255] "" Vector__XXX
 SG_ Led0026_value : 200|8@1+ (1,0) [0|255] "" Vector__XXX
 SG_ Led0025_value : 192|8@1+ (1,0) [0|255] "" Vector__XXX
 SG_ Led0024_value : 184|8@1+ (1,0) [0|255] "" Vector__XXX
 SG_ Led0023_value : 176|8@1+ (1,0) [0|255] "" Vector__XXX
 SG_ Led0022_value : 168|8@1+ (1,0) [0|255] "" Vector__XXX
 SG_ Led0021_value : 160|8@1+ (1,0) [0|255] "" Vector__XXX
 SG_ Led0020_value : 152|8@1+ (1,0) [0|255] "" Vector__XXX
 SG_ Led0019_value : 144|8@1+ (1,0) [0|255] "" Vector__XXX
 SG_ Led0018_value : 136|8@1+ (1,0) [0|255] "" Vector__XXX
 SG_ Led0017_value : 128|8@1+ (1,0) [0|255] "" Vector__XXX
 SG_ Led0016_value : 120|8@1+ (1,0) [0|255] "" Vector__XXX
 SG_ Led0015_value : 112|8@1+ (1,0) [0|255] "" Vector__XXX
 SG_ Led0014_value : 104|8@1+ (1,0) [0|255] "" Vector__XXX
 SG_ Led0013_value : 96|8@1+ (1,0) [0|255] "" Vector__XXX
 SG_ Led0012_value : 88|8@1+ (1,0) [0|255] "" Vector__XXX
 SG_ Led0011_value : 80|8@1+ (1,0) [0|255] "" Vector__XXX
 SG_ Led0010_value : 72|8@1+ (1,0) [0|255] "" Vector__XXX
 SG_ Led0009_value : 64|8@1+ (1,0) [0|255] "" Vector__XXX
 SG_ Led0008_value : 56|8@1+ (1,0) [0|255] "" Vector__XXX
 SG_ Led0007_value : 48|8@1+ (1,0) [0|255] "" Vector__XXX
 SG_ Led0006_value : 40|8@1+ (1,0) [0|255] "" Vector__XXX
 SG_ Led0005_value : 32|8@1+ (1,0) [0|255] "" Vector__XXX
 SG_ Led0004_value : 24|8@1+ (1,0) [0|255] "" Vector__XXX
 SG_ Led0003_value : 16|8@1+ (1,0) [0|255] "" Vector__XXX
 SG_ Led0002_value : 8|8@1+ (1,0) [0|255] "" Vector__XXX
 SG_ Led0001_value : 0|8@1+ (1,0) [0|255] "" Vector__XXX

BO_ 1041 ISC_Ctrl_LED_B_17: 64 ISC
 SG_ Led0064_value : 504|8@1+ (1,0) [0|255] "" Vector__XXX
 SG_ Led0063_value : 496|8@1+ (1,0) [0|255] "" Vector__XXX
 SG_ Led0062_value : 488|8@1+ (1,0) [0|255] "" Vector__XXX
 SG_ Led0061_value : 480|8@1+ (1,0) [0|255] "" Vector__XXX
 SG_ Led0060_value : 472|8@1+ (1,0) [0|255] "" Vector__XXX
 SG_ Led0059_value : 464|8@1+ (1,0) [0|255] "" Vector__XXX
 SG_ Led0058_value : 456|8@1+ (1,0) [0|255] "" Vector__XXX
 SG_ Led0057_value : 448|8@1+ (1,0) [0|255] "" Vector__XXX
 SG_ Led0056_value : 440|8@1+ (1,0) [0|255] "" Vector__XXX
 SG_ Led0055_value : 432|8@1+ (1,0) [0|255] "" Vector__XXX
 SG_ Led0054_value : 424|8@1+ (1,0) [0|255] "" Vector__XXX
 SG_ Led0053_value : 416|8@1+ (1,0) [0|255] "" Vector__XXX
 SG_ Led0052_value : 408|8@1+ (1,0) [0|255] "" Vector__XXX
 SG_ Led0051_value : 400|8@1+ (1,0) [0|255] "" Vector__XXX
 SG_ Led0050_value : 392|8@1+ (1,0) [0|255] "" Vector__XXX
 SG_ Led0049_value : 384|8@1+ (1,0) [0|255] "" Vector__XXX
 SG_ Led0048_value : 376|8@1+ (1,0) [0|255] "" Vector__XXX
 SG_ Led0047_value : 368|8@1+ (1,0) [0|255] "" Vector__XXX
 SG_ Led0046_value : 360|8@1+ (1,0) [0|255] "" Vector__XXX
 SG_ Led0045_value : 352|8@1+ (1,0) [0|255] "" Vector__XXX
 SG_ Led0044_value : 344|8@1+ (1,0) [0|255] "" Vector__XXX
 SG_ Led0043_value : 336|8@1+ (1,0) [0|255] "" Vector__XXX
 SG_ Led0042_value : 328|8@1+ (1,0) [0|255] "" Vector__XXX
 SG_ Led0041_value : 320|8@1+ (1,0) [0|255] "" Vector__XXX
 SG_ Led0040_value : 312|8@1+ (1,0) [0|255] "" Vector__XXX
 SG_ Led0039_value : 304|8@1+ (1,0) [0|255] "" Vector__XXX
 SG_ Led0038_value : 296|8@1+ (1,0) [0|255] "" Vector__XXX
 SG_ Led0037_value : 288|8@1+ (1,0) [0|255] "" Vector__XXX
 SG_ Led0036_value : 280|8@1+ (1,0) [0|255] "" Vector__XXX
 SG_ Led0035_value : 272|8@1+ (1,0) [0|255] "" Vector__XXX
 SG_ Led0034_value : 264|8@1+ (1,0) [0|255] "" Vector__XXX
 SG_ Led0033_value : 256|8@1+ (1,0) [0|255] "" Vector__XXX
 SG_ Led0032_value : 248|8@1+ (1,0) [0|255] "" Vector__XXX
 SG_ Led0031_value : 240|8@1+ (1,0) [0|255] "" Vector__XXX
 SG_ Led0030_value : 232|8@1+ (1,0) [0|255] "" Vector__XXX
 SG_ Led0029_value : 224|8@1+ (1,0) [0|255] "" Vector__XXX
 SG_ Led0028_value : 216|8@1+ (1,0) [0|255] "" Vector__XXX
 SG_ Led0027_value : 208|8@1+ (1,0) [0|255] "" Vector__XXX
 SG_ Led0026_value : 200|8@1+ (1,0) [0|255] "" Vector__XXX
 SG_ Led0025_value : 192|8@1+ (1,0) [0|255] "" Vector__XXX
 SG_ Led0024_value : 184|8@1+ (1,0) [0|255] "" Vector__XXX
 SG_ Led0023_value : 176|8@1+ (1,0) [0|255] "" Vector__XXX
 SG_ Led0022_value : 168|8@1+ (1,0) [0|255] "" Vector__XXX
 SG_ Led0021_value : 160|8@1+ (1,0) [0|255] "" Vector__XXX
 SG_ Led0020_value : 152|8@1+ (1,0) [0|255] "" Vector__XXX
 SG_ Led0019_value : 144|8@1+ (1,0) [0|255] "" Vector__XXX
 SG_ Led0018_value : 136|8@1+ (1,0) [0|255] "" Vector__XXX
 SG_ Led0017_value : 128|8@1+ (1,0) [0|255] "" Vector__XXX
 SG_ Led0016_value : 120|8@1+ (1,0) [0|255] "" Vector__XXX
 SG_ Led0015_value : 112|8@1+ (1,0) [0|255] "" Vector__XXX
 SG_ Led0014_value : 104|8@1+ (1,0) [0|255] "" Vector__XXX
 SG_ Led0013_value : 96|8@1+ (1,0) [0|255] "" Vector__XXX
 SG_ Led0012_value : 88|8@1+ (1,0) [0|255] "" Vector__XXX
 SG_ Led0011_value : 80|8@1+ (1,0) [0|255] "" Vector__XXX
 SG_ Led0010_value : 72|8@1+ (1,0) [0|255] "" Vector__XXX
 SG_ Led0009_value : 64|8@1+ (1,0) [0|255] "" Vector__XXX
 SG_ Led0008_value : 56|8@1+ (1,0) [0|255] "" Vector__XXX
 SG_ Led0007_value : 48|8@1+ (1,0) [0|255] "" Vector__XXX
 SG_ Led0006_value : 40|8@1+ (1,0) [0|255] "" Vector__XXX
 SG_ Led0005_value : 32|8@1+ (1,0) [0|255] "" Vector__XXX
 SG_ Led0004_value : 24|8@1+ (1,0) [0|255] "" Vector__XXX
 SG_ Led0003_value : 16|8@1+ (1,0) [0|255] "" Vector__XXX
 SG_ Led0002_value : 8|8@1+ (1,0) [0|255] "" Vector__XXX
 SG_ Led0001_value : 0|8@1+ (1,0) [0|255] "" Vector__XXX

BO_ 1040 ISC_Ctrl_LED_B_16: 64 ISC
 SG_ Led0064_value : 504|8@1+ (1,0) [0|255] "" Vector__XXX
 SG_ Led0063_value : 496|8@1+ (1,0) [0|255] "" Vector__XXX
 SG_ Led0062_value : 488|8@1+ (1,0) [0|255] "" Vector__XXX
 SG_ Led0061_value : 480|8@1+ (1,0) [0|255] "" Vector__XXX
 SG_ Led0060_value : 472|8@1+ (1,0) [0|255] "" Vector__XXX
 SG_ Led0059_value : 464|8@1+ (1,0) [0|255] "" Vector__XXX
 SG_ Led0058_value : 456|8@1+ (1,0) [0|255] "" Vector__XXX
 SG_ Led0057_value : 448|8@1+ (1,0) [0|255] "" Vector__XXX
 SG_ Led0056_value : 440|8@1+ (1,0) [0|255] "" Vector__XXX
 SG_ Led0055_value : 432|8@1+ (1,0) [0|255] "" Vector__XXX
 SG_ Led0054_value : 424|8@1+ (1,0) [0|255] "" Vector__XXX
 SG_ Led0053_value : 416|8@1+ (1,0) [0|255] "" Vector__XXX
 SG_ Led0052_value : 408|8@1+ (1,0) [0|255] "" Vector__XXX
 SG_ Led0051_value : 400|8@1+ (1,0) [0|255] "" Vector__XXX
 SG_ Led0050_value : 392|8@1+ (1,0) [0|255] "" Vector__XXX
 SG_ Led0049_value : 384|8@1+ (1,0) [0|255] "" Vector__XXX
 SG_ Led0048_value : 376|8@1+ (1,0) [0|255] "" Vector__XXX
 SG_ Led0047_value : 368|8@1+ (1,0) [0|255] "" Vector__XXX
 SG_ Led0046_value : 360|8@1+ (1,0) [0|255] "" Vector__XXX
 SG_ Led0045_value : 352|8@1+ (1,0) [0|255] "" Vector__XXX
 SG_ Led0044_value : 344|8@1+ (1,0) [0|255] "" Vector__XXX
 SG_ Led0043_value : 336|8@1+ (1,0) [0|255] "" Vector__XXX
 SG_ Led0042_value : 328|8@1+ (1,0) [0|255] "" Vector__XXX
 SG_ Led0041_value : 320|8@1+ (1,0) [0|255] "" Vector__XXX
 SG_ Led0040_value : 312|8@1+ (1,0) [0|255] "" Vector__XXX
 SG_ Led0039_value : 304|8@1+ (1,0) [0|255] "" Vector__XXX
 SG_ Led0038_value : 296|8@1+ (1,0) [0|255] "" Vector__XXX
 SG_ Led0037_value : 288|8@1+ (1,0) [0|255] "" Vector__XXX
 SG_ Led0036_value : 280|8@1+ (1,0) [0|255] "" Vector__XXX
 SG_ Led0035_value : 272|8@1+ (1,0) [0|255] "" Vector__XXX
 SG_ Led0034_value : 264|8@1+ (1,0) [0|255] "" Vector__XXX
 SG_ Led0033_value : 256|8@1+ (1,0) [0|255] "" Vector__XXX
 SG_ Led0032_value : 248|8@1+ (1,0) [0|255] "" Vector__XXX
 SG_ Led0031_value : 240|8@1+ (1,0) [0|255] "" Vector__XXX
 SG_ Led0030_value : 232|8@1+ (1,0) [0|255] "" Vector__XXX
 SG_ Led0029_value : 224|8@1+ (1,0) [0|255] "" Vector__XXX
 SG_ Led0028_value : 216|8@1+ (1,0) [0|255] "" Vector__XXX
 SG_ Led0027_value : 208|8@1+ (1,0) [0|255] "" Vector__XXX
 SG_ Led0026_value : 200|8@1+ (1,0) [0|255] "" Vector__XXX
 SG_ Led0025_value : 192|8@1+ (1,0) [0|255] "" Vector__XXX
 SG_ Led0024_value : 184|8@1+ (1,0) [0|255] "" Vector__XXX
 SG_ Led0023_value : 176|8@1+ (1,0) [0|255] "" Vector__XXX
 SG_ Led0022_value : 168|8@1+ (1,0) [0|255] "" Vector__XXX
 SG_ Led0021_value : 160|8@1+ (1,0) [0|255] "" Vector__XXX
 SG_ Led0020_value : 152|8@1+ (1,0) [0|255] "" Vector__XXX
 SG_ Led0019_value : 144|8@1+ (1,0) [0|255] "" Vector__XXX
 SG_ Led0018_value : 136|8@1+ (1,0) [0|255] "" Vector__XXX
 SG_ Led0017_value : 128|8@1+ (1,0) [0|255] "" Vector__XXX
 SG_ Led0016_value : 120|8@1+ (1,0) [0|255] "" Vector__XXX
 SG_ Led0015_value : 112|8@1+ (1,0) [0|255] "" Vector__XXX
 SG_ Led0014_value : 104|8@1+ (1,0) [0|255] "" Vector__XXX
 SG_ Led0013_value : 96|8@1+ (1,0) [0|255] "" Vector__XXX
 SG_ Led0012_value : 88|8@1+ (1,0) [0|255] "" Vector__XXX
 SG_ Led0011_value : 80|8@1+ (1,0) [0|255] "" Vector__XXX
 SG_ Led0010_value : 72|8@1+ (1,0) [0|255] "" Vector__XXX
 SG_ Led0009_value : 64|8@1+ (1,0) [0|255] "" Vector__XXX
 SG_ Led0008_value : 56|8@1+ (1,0) [0|255] "" Vector__XXX
 SG_ Led0007_value : 48|8@1+ (1,0) [0|255] "" Vector__XXX
 SG_ Led0006_value : 40|8@1+ (1,0) [0|255] "" Vector__XXX
 SG_ Led0005_value : 32|8@1+ (1,0) [0|255] "" Vector__XXX
 SG_ Led0004_value : 24|8@1+ (1,0) [0|255] "" Vector__XXX
 SG_ Led0003_value : 16|8@1+ (1,0) [0|255] "" Vector__XXX
 SG_ Led0002_value : 8|8@1+ (1,0) [0|255] "" Vector__XXX
 SG_ Led0001_value : 0|8@1+ (1,0) [0|255] "" Vector__XXX

BO_ 1039 ISC_Ctrl_LED_B_15: 64 ISC
 SG_ Led0064_value : 504|8@1+ (1,0) [0|255] "" Vector__XXX
 SG_ Led0063_value : 496|8@1+ (1,0) [0|255] "" Vector__XXX
 SG_ Led0062_value : 488|8@1+ (1,0) [0|255] "" Vector__XXX
 SG_ Led0061_value : 480|8@1+ (1,0) [0|255] "" Vector__XXX
 SG_ Led0060_value : 472|8@1+ (1,0) [0|255] "" Vector__XXX
 SG_ Led0059_value : 464|8@1+ (1,0) [0|255] "" Vector__XXX
 SG_ Led0058_value : 456|8@1+ (1,0) [0|255] "" Vector__XXX
 SG_ Led0057_value : 448|8@1+ (1,0) [0|255] "" Vector__XXX
 SG_ Led0056_value : 440|8@1+ (1,0) [0|255] "" Vector__XXX
 SG_ Led0055_value : 432|8@1+ (1,0) [0|255] "" Vector__XXX
 SG_ Led0054_value : 424|8@1+ (1,0) [0|255] "" Vector__XXX
 SG_ Led0053_value : 416|8@1+ (1,0) [0|255] "" Vector__XXX
 SG_ Led0052_value : 408|8@1+ (1,0) [0|255] "" Vector__XXX
 SG_ Led0051_value : 400|8@1+ (1,0) [0|255] "" Vector__XXX
 SG_ Led0050_value : 392|8@1+ (1,0) [0|255] "" Vector__XXX
 SG_ Led0049_value : 384|8@1+ (1,0) [0|255] "" Vector__XXX
 SG_ Led0048_value : 376|8@1+ (1,0) [0|255] "" Vector__XXX
 SG_ Led0047_value : 368|8@1+ (1,0) [0|255] "" Vector__XXX
 SG_ Led0046_value : 360|8@1+ (1,0) [0|255] "" Vector__XXX
 SG_ Led0045_value : 352|8@1+ (1,0) [0|255] "" Vector__XXX
 SG_ Led0044_value : 344|8@1+ (1,0) [0|255] "" Vector__XXX
 SG_ Led0043_value : 336|8@1+ (1,0) [0|255] "" Vector__XXX
 SG_ Led0042_value : 328|8@1+ (1,0) [0|255] "" Vector__XXX
 SG_ Led0041_value : 320|8@1+ (1,0) [0|255] "" Vector__XXX
 SG_ Led0040_value : 312|8@1+ (1,0) [0|255] "" Vector__XXX
 SG_ Led0039_value : 304|8@1+ (1,0) [0|255] "" Vector__XXX
 SG_ Led0038_value : 296|8@1+ (1,0) [0|255] "" Vector__XXX
 SG_ Led0037_value : 288|8@1+ (1,0) [0|255] "" Vector__XXX
 SG_ Led0036_value : 280|8@1+ (1,0) [0|255] "" Vector__XXX
 SG_ Led0035_value : 272|8@1+ (1,0) [0|255] "" Vector__XXX
 SG_ Led0034_value : 264|8@1+ (1,0) [0|255] "" Vector__XXX
 SG_ Led0033_value : 256|8@1+ (1,0) [0|255] "" Vector__XXX
 SG_ Led0032_value : 248|8@1+ (1,0) [0|255] "" Vector__XXX
 SG_ Led0031_value : 240|8@1+ (1,0) [0|255] "" Vector__XXX
 SG_ Led0030_value : 232|8@1+ (1,0) [0|255] "" Vector__XXX
 SG_ Led0029_value : 224|8@1+ (1,0) [0|255] "" Vector__XXX
 SG_ Led0028_value : 216|8@1+ (1,0) [0|255] "" Vector__XXX
 SG_ Led0027_value : 208|8@1+ (1,0) [0|255] "" Vector__XXX
 SG_ Led0026_value : 200|8@1+ (1,0) [0|255] "" Vector__XXX
 SG_ Led0025_value : 192|8@1+ (1,0) [0|255] "" Vector__XXX
 SG_ Led0024_value : 184|8@1+ (1,0) [0|255] "" Vector__XXX
 SG_ Led0023_value : 176|8@1+ (1,0) [0|255] "" Vector__XXX
 SG_ Led0022_value : 168|8@1+ (1,0) [0|255] "" Vector__XXX
 SG_ Led0021_value : 160|8@1+ (1,0) [0|255] "" Vector__XXX
 SG_ Led0020_value : 152|8@1+ (1,0) [0|255] "" Vector__XXX
 SG_ Led0019_value : 144|8@1+ (1,0) [0|255] "" Vector__XXX
 SG_ Led0018_value : 136|8@1+ (1,0) [0|255] "" Vector__XXX
 SG_ Led0017_value : 128|8@1+ (1,0) [0|255] "" Vector__XXX
 SG_ Led0016_value : 120|8@1+ (1,0) [0|255] "" Vector__XXX
 SG_ Led0015_value : 112|8@1+ (1,0) [0|255] "" Vector__XXX
 SG_ Led0014_value : 104|8@1+ (1,0) [0|255] "" Vector__XXX
 SG_ Led0013_value : 96|8@1+ (1,0) [0|255] "" Vector__XXX
 SG_ Led0012_value : 88|8@1+ (1,0) [0|255] "" Vector__XXX
 SG_ Led0011_value : 80|8@1+ (1,0) [0|255] "" Vector__XXX
 SG_ Led0010_value : 72|8@1+ (1,0) [0|255] "" Vector__XXX
 SG_ Led0009_value : 64|8@1+ (1,0) [0|255] "" Vector__XXX
 SG_ Led0008_value : 56|8@1+ (1,0) [0|255] "" Vector__XXX
 SG_ Led0007_value : 48|8@1+ (1,0) [0|255] "" Vector__XXX
 SG_ Led0006_value : 40|8@1+ (1,0) [0|255] "" Vector__XXX
 SG_ Led0005_value : 32|8@1+ (1,0) [0|255] "" Vector__XXX
 SG_ Led0004_value : 24|8@1+ (1,0) [0|255] "" Vector__XXX
 SG_ Led0003_value : 16|8@1+ (1,0) [0|255] "" Vector__XXX
 SG_ Led0002_value : 8|8@1+ (1,0) [0|255] "" Vector__XXX
 SG_ Led0001_value : 0|8@1+ (1,0) [0|255] "" Vector__XXX

BO_ 1038 ISC_Ctrl_LED_B_14: 64 ISC
 SG_ Led0064_value : 504|8@1+ (1,0) [0|255] "" Vector__XXX
 SG_ Led0063_value : 496|8@1+ (1,0) [0|255] "" Vector__XXX
 SG_ Led0062_value : 488|8@1+ (1,0) [0|255] "" Vector__XXX
 SG_ Led0061_value : 480|8@1+ (1,0) [0|255] "" Vector__XXX
 SG_ Led0060_value : 472|8@1+ (1,0) [0|255] "" Vector__XXX
 SG_ Led0059_value : 464|8@1+ (1,0) [0|255] "" Vector__XXX
 SG_ Led0058_value : 456|8@1+ (1,0) [0|255] "" Vector__XXX
 SG_ Led0057_value : 448|8@1+ (1,0) [0|255] "" Vector__XXX
 SG_ Led0056_value : 440|8@1+ (1,0) [0|255] "" Vector__XXX
 SG_ Led0055_value : 432|8@1+ (1,0) [0|255] "" Vector__XXX
 SG_ Led0054_value : 424|8@1+ (1,0) [0|255] "" Vector__XXX
 SG_ Led0053_value : 416|8@1+ (1,0) [0|255] "" Vector__XXX
 SG_ Led0052_value : 408|8@1+ (1,0) [0|255] "" Vector__XXX
 SG_ Led0051_value : 400|8@1+ (1,0) [0|255] "" Vector__XXX
 SG_ Led0050_value : 392|8@1+ (1,0) [0|255] "" Vector__XXX
 SG_ Led0049_value : 384|8@1+ (1,0) [0|255] "" Vector__XXX
 SG_ Led0048_value : 376|8@1+ (1,0) [0|255] "" Vector__XXX
 SG_ Led0047_value : 368|8@1+ (1,0) [0|255] "" Vector__XXX
 SG_ Led0046_value : 360|8@1+ (1,0) [0|255] "" Vector__XXX
 SG_ Led0045_value : 352|8@1+ (1,0) [0|255] "" Vector__XXX
 SG_ Led0044_value : 344|8@1+ (1,0) [0|255] "" Vector__XXX
 SG_ Led0043_value : 336|8@1+ (1,0) [0|255] "" Vector__XXX
 SG_ Led0042_value : 328|8@1+ (1,0) [0|255] "" Vector__XXX
 SG_ Led0041_value : 320|8@1+ (1,0) [0|255] "" Vector__XXX
 SG_ Led0040_value : 312|8@1+ (1,0) [0|255] "" Vector__XXX
 SG_ Led0039_value : 304|8@1+ (1,0) [0|255] "" Vector__XXX
 SG_ Led0038_value : 296|8@1+ (1,0) [0|255] "" Vector__XXX
 SG_ Led0037_value : 288|8@1+ (1,0) [0|255] "" Vector__XXX
 SG_ Led0036_value : 280|8@1+ (1,0) [0|255] "" Vector__XXX
 SG_ Led0035_value : 272|8@1+ (1,0) [0|255] "" Vector__XXX
 SG_ Led0034_value : 264|8@1+ (1,0) [0|255] "" Vector__XXX
 SG_ Led0033_value : 256|8@1+ (1,0) [0|255] "" Vector__XXX
 SG_ Led0032_value : 248|8@1+ (1,0) [0|255] "" Vector__XXX
 SG_ Led0031_value : 240|8@1+ (1,0) [0|255] "" Vector__XXX
 SG_ Led0030_value : 232|8@1+ (1,0) [0|255] "" Vector__XXX
 SG_ Led0029_value : 224|8@1+ (1,0) [0|255] "" Vector__XXX
 SG_ Led0028_value : 216|8@1+ (1,0) [0|255] "" Vector__XXX
 SG_ Led0027_value : 208|8@1+ (1,0) [0|255] "" Vector__XXX
 SG_ Led0026_value : 200|8@1+ (1,0) [0|255] "" Vector__XXX
 SG_ Led0025_value : 192|8@1+ (1,0) [0|255] "" Vector__XXX
 SG_ Led0024_value : 184|8@1+ (1,0) [0|255] "" Vector__XXX
 SG_ Led0023_value : 176|8@1+ (1,0) [0|255] "" Vector__XXX
 SG_ Led0022_value : 168|8@1+ (1,0) [0|255] "" Vector__XXX
 SG_ Led0021_value : 160|8@1+ (1,0) [0|255] "" Vector__XXX
 SG_ Led0020_value : 152|8@1+ (1,0) [0|255] "" Vector__XXX
 SG_ Led0019_value : 144|8@1+ (1,0) [0|255] "" Vector__XXX
 SG_ Led0018_value : 136|8@1+ (1,0) [0|255] "" Vector__XXX
 SG_ Led0017_value : 128|8@1+ (1,0) [0|255] "" Vector__XXX
 SG_ Led0016_value : 120|8@1+ (1,0) [0|255] "" Vector__XXX
 SG_ Led0015_value : 112|8@1+ (1,0) [0|255] "" Vector__XXX
 SG_ Led0014_value : 104|8@1+ (1,0) [0|255] "" Vector__XXX
 SG_ Led0013_value : 96|8@1+ (1,0) [0|255] "" Vector__XXX
 SG_ Led0012_value : 88|8@1+ (1,0) [0|255] "" Vector__XXX
 SG_ Led0011_value : 80|8@1+ (1,0) [0|255] "" Vector__XXX
 SG_ Led0010_value : 72|8@1+ (1,0) [0|255] "" Vector__XXX
 SG_ Led0009_value : 64|8@1+ (1,0) [0|255] "" Vector__XXX
 SG_ Led0008_value : 56|8@1+ (1,0) [0|255] "" Vector__XXX
 SG_ Led0007_value : 48|8@1+ (1,0) [0|255] "" Vector__XXX
 SG_ Led0006_value : 40|8@1+ (1,0) [0|255] "" Vector__XXX
 SG_ Led0005_value : 32|8@1+ (1,0) [0|255] "" Vector__XXX
 SG_ Led0004_value : 24|8@1+ (1,0) [0|255] "" Vector__XXX
 SG_ Led0003_value : 16|8@1+ (1,0) [0|255] "" Vector__XXX
 SG_ Led0002_value : 8|8@1+ (1,0) [0|255] "" Vector__XXX
 SG_ Led0001_value : 0|8@1+ (1,0) [0|255] "" Vector__XXX

BO_ 1037 ISC_Ctrl_LED_B_13: 64 ISC
 SG_ Led0064_value : 504|8@1+ (1,0) [0|255] "" Vector__XXX
 SG_ Led0063_value : 496|8@1+ (1,0) [0|255] "" Vector__XXX
 SG_ Led0062_value : 488|8@1+ (1,0) [0|255] "" Vector__XXX
 SG_ Led0061_value : 480|8@1+ (1,0) [0|255] "" Vector__XXX
 SG_ Led0060_value : 472|8@1+ (1,0) [0|255] "" Vector__XXX
 SG_ Led0059_value : 464|8@1+ (1,0) [0|255] "" Vector__XXX
 SG_ Led0058_value : 456|8@1+ (1,0) [0|255] "" Vector__XXX
 SG_ Led0057_value : 448|8@1+ (1,0) [0|255] "" Vector__XXX
 SG_ Led0056_value : 440|8@1+ (1,0) [0|255] "" Vector__XXX
 SG_ Led0055_value : 432|8@1+ (1,0) [0|255] "" Vector__XXX
 SG_ Led0054_value : 424|8@1+ (1,0) [0|255] "" Vector__XXX
 SG_ Led0053_value : 416|8@1+ (1,0) [0|255] "" Vector__XXX
 SG_ Led0052_value : 408|8@1+ (1,0) [0|255] "" Vector__XXX
 SG_ Led0051_value : 400|8@1+ (1,0) [0|255] "" Vector__XXX
 SG_ Led0050_value : 392|8@1+ (1,0) [0|255] "" Vector__XXX
 SG_ Led0049_value : 384|8@1+ (1,0) [0|255] "" Vector__XXX
 SG_ Led0048_value : 376|8@1+ (1,0) [0|255] "" Vector__XXX
 SG_ Led0047_value : 368|8@1+ (1,0) [0|255] "" Vector__XXX
 SG_ Led0046_value : 360|8@1+ (1,0) [0|255] "" Vector__XXX
 SG_ Led0045_value : 352|8@1+ (1,0) [0|255] "" Vector__XXX
 SG_ Led0044_value : 344|8@1+ (1,0) [0|255] "" Vector__XXX
 SG_ Led0043_value : 336|8@1+ (1,0) [0|255] "" Vector__XXX
 SG_ Led0042_value : 328|8@1+ (1,0) [0|255] "" Vector__XXX
 SG_ Led0041_value : 320|8@1+ (1,0) [0|255] "" Vector__XXX
 SG_ Led0040_value : 312|8@1+ (1,0) [0|255] "" Vector__XXX
 SG_ Led0039_value : 304|8@1+ (1,0) [0|255] "" Vector__XXX
 SG_ Led0038_value : 296|8@1+ (1,0) [0|255] "" Vector__XXX
 SG_ Led0037_value : 288|8@1+ (1,0) [0|255] "" Vector__XXX
 SG_ Led0036_value : 280|8@1+ (1,0) [0|255] "" Vector__XXX
 SG_ Led0035_value : 272|8@1+ (1,0) [0|255] "" Vector__XXX
 SG_ Led0034_value : 264|8@1+ (1,0) [0|255] "" Vector__XXX
 SG_ Led0033_value : 256|8@1+ (1,0) [0|255] "" Vector__XXX
 SG_ Led0032_value : 248|8@1+ (1,0) [0|255] "" Vector__XXX
 SG_ Led0031_value : 240|8@1+ (1,0) [0|255] "" Vector__XXX
 SG_ Led0030_value : 232|8@1+ (1,0) [0|255] "" Vector__XXX
 SG_ Led0029_value : 224|8@1+ (1,0) [0|255] "" Vector__XXX
 SG_ Led0028_value : 216|8@1+ (1,0) [0|255] "" Vector__XXX
 SG_ Led0027_value : 208|8@1+ (1,0) [0|255] "" Vector__XXX
 SG_ Led0026_value : 200|8@1+ (1,0) [0|255] "" Vector__XXX
 SG_ Led0025_value : 192|8@1+ (1,0) [0|255] "" Vector__XXX
 SG_ Led0024_value : 184|8@1+ (1,0) [0|255] "" Vector__XXX
 SG_ Led0023_value : 176|8@1+ (1,0) [0|255] "" Vector__XXX
 SG_ Led0022_value : 168|8@1+ (1,0) [0|255] "" Vector__XXX
 SG_ Led0021_value : 160|8@1+ (1,0) [0|255] "" Vector__XXX
 SG_ Led0020_value : 152|8@1+ (1,0) [0|255] "" Vector__XXX
 SG_ Led0019_value : 144|8@1+ (1,0) [0|255] "" Vector__XXX
 SG_ Led0018_value : 136|8@1+ (1,0) [0|255] "" Vector__XXX
 SG_ Led0017_value : 128|8@1+ (1,0) [0|255] "" Vector__XXX
 SG_ Led0016_value : 120|8@1+ (1,0) [0|255] "" Vector__XXX
 SG_ Led0015_value : 112|8@1+ (1,0) [0|255] "" Vector__XXX
 SG_ Led0014_value : 104|8@1+ (1,0) [0|255] "" Vector__XXX
 SG_ Led0013_value : 96|8@1+ (1,0) [0|255] "" Vector__XXX
 SG_ Led0012_value : 88|8@1+ (1,0) [0|255] "" Vector__XXX
 SG_ Led0011_value : 80|8@1+ (1,0) [0|255] "" Vector__XXX
 SG_ Led0010_value : 72|8@1+ (1,0) [0|255] "" Vector__XXX
 SG_ Led0009_value : 64|8@1+ (1,0) [0|255] "" Vector__XXX
 SG_ Led0008_value : 56|8@1+ (1,0) [0|255] "" Vector__XXX
 SG_ Led0007_value : 48|8@1+ (1,0) [0|255] "" Vector__XXX
 SG_ Led0006_value : 40|8@1+ (1,0) [0|255] "" Vector__XXX
 SG_ Led0005_value : 32|8@1+ (1,0) [0|255] "" Vector__XXX
 SG_ Led0004_value : 24|8@1+ (1,0) [0|255] "" Vector__XXX
 SG_ Led0003_value : 16|8@1+ (1,0) [0|255] "" Vector__XXX
 SG_ Led0002_value : 8|8@1+ (1,0) [0|255] "" Vector__XXX
 SG_ Led0001_value : 0|8@1+ (1,0) [0|255] "" Vector__XXX

BO_ 1036 ISC_Ctrl_LED_B_12: 64 ISC
 SG_ Led0064_value : 504|8@1+ (1,0) [0|255] "" Vector__XXX
 SG_ Led0063_value : 496|8@1+ (1,0) [0|255] "" Vector__XXX
 SG_ Led0062_value : 488|8@1+ (1,0) [0|255] "" Vector__XXX
 SG_ Led0061_value : 480|8@1+ (1,0) [0|255] "" Vector__XXX
 SG_ Led0060_value : 472|8@1+ (1,0) [0|255] "" Vector__XXX
 SG_ Led0059_value : 464|8@1+ (1,0) [0|255] "" Vector__XXX
 SG_ Led0058_value : 456|8@1+ (1,0) [0|255] "" Vector__XXX
 SG_ Led0057_value : 448|8@1+ (1,0) [0|255] "" Vector__XXX
 SG_ Led0056_value : 440|8@1+ (1,0) [0|255] "" Vector__XXX
 SG_ Led0055_value : 432|8@1+ (1,0) [0|255] "" Vector__XXX
 SG_ Led0054_value : 424|8@1+ (1,0) [0|255] "" Vector__XXX
 SG_ Led0053_value : 416|8@1+ (1,0) [0|255] "" Vector__XXX
 SG_ Led0052_value : 408|8@1+ (1,0) [0|255] "" Vector__XXX
 SG_ Led0051_value : 400|8@1+ (1,0) [0|255] "" Vector__XXX
 SG_ Led0050_value : 392|8@1+ (1,0) [0|255] "" Vector__XXX
 SG_ Led0049_value : 384|8@1+ (1,0) [0|255] "" Vector__XXX
 SG_ Led0048_value : 376|8@1+ (1,0) [0|255] "" Vector__XXX
 SG_ Led0047_value : 368|8@1+ (1,0) [0|255] "" Vector__XXX
 SG_ Led0046_value : 360|8@1+ (1,0) [0|255] "" Vector__XXX
 SG_ Led0045_value : 352|8@1+ (1,0) [0|255] "" Vector__XXX
 SG_ Led0044_value : 344|8@1+ (1,0) [0|255] "" Vector__XXX
 SG_ Led0043_value : 336|8@1+ (1,0) [0|255] "" Vector__XXX
 SG_ Led0042_value : 328|8@1+ (1,0) [0|255] "" Vector__XXX
 SG_ Led0041_value : 320|8@1+ (1,0) [0|255] "" Vector__XXX
 SG_ Led0040_value : 312|8@1+ (1,0) [0|255] "" Vector__XXX
 SG_ Led0039_value : 304|8@1+ (1,0) [0|255] "" Vector__XXX
 SG_ Led0038_value : 296|8@1+ (1,0) [0|255] "" Vector__XXX
 SG_ Led0037_value : 288|8@1+ (1,0) [0|255] "" Vector__XXX
 SG_ Led0036_value : 280|8@1+ (1,0) [0|255] "" Vector__XXX
 SG_ Led0035_value : 272|8@1+ (1,0) [0|255] "" Vector__XXX
 SG_ Led0034_value : 264|8@1+ (1,0) [0|255] "" Vector__XXX
 SG_ Led0033_value : 256|8@1+ (1,0) [0|255] "" Vector__XXX
 SG_ Led0032_value : 248|8@1+ (1,0) [0|255] "" Vector__XXX
 SG_ Led0031_value : 240|8@1+ (1,0) [0|255] "" Vector__XXX
 SG_ Led0030_value : 232|8@1+ (1,0) [0|255] "" Vector__XXX
 SG_ Led0029_value : 224|8@1+ (1,0) [0|255] "" Vector__XXX
 SG_ Led0028_value : 216|8@1+ (1,0) [0|255] "" Vector__XXX
 SG_ Led0027_value : 208|8@1+ (1,0) [0|255] "" Vector__XXX
 SG_ Led0026_value : 200|8@1+ (1,0) [0|255] "" Vector__XXX
 SG_ Led0025_value : 192|8@1+ (1,0) [0|255] "" Vector__XXX
 SG_ Led0024_value : 184|8@1+ (1,0) [0|255] "" Vector__XXX
 SG_ Led0023_value : 176|8@1+ (1,0) [0|255] "" Vector__XXX
 SG_ Led0022_value : 168|8@1+ (1,0) [0|255] "" Vector__XXX
 SG_ Led0021_value : 160|8@1+ (1,0) [0|255] "" Vector__XXX
 SG_ Led0020_value : 152|8@1+ (1,0) [0|255] "" Vector__XXX
 SG_ Led0019_value : 144|8@1+ (1,0) [0|255] "" Vector__XXX
 SG_ Led0018_value : 136|8@1+ (1,0) [0|255] "" Vector__XXX
 SG_ Led0017_value : 128|8@1+ (1,0) [0|255] "" Vector__XXX
 SG_ Led0016_value : 120|8@1+ (1,0) [0|255] "" Vector__XXX
 SG_ Led0015_value : 112|8@1+ (1,0) [0|255] "" Vector__XXX
 SG_ Led0014_value : 104|8@1+ (1,0) [0|255] "" Vector__XXX
 SG_ Led0013_value : 96|8@1+ (1,0) [0|255] "" Vector__XXX
 SG_ Led0012_value : 88|8@1+ (1,0) [0|255] "" Vector__XXX
 SG_ Led0011_value : 80|8@1+ (1,0) [0|255] "" Vector__XXX
 SG_ Led0010_value : 72|8@1+ (1,0) [0|255] "" Vector__XXX
 SG_ Led0009_value : 64|8@1+ (1,0) [0|255] "" Vector__XXX
 SG_ Led0008_value : 56|8@1+ (1,0) [0|255] "" Vector__XXX
 SG_ Led0007_value : 48|8@1+ (1,0) [0|255] "" Vector__XXX
 SG_ Led0006_value : 40|8@1+ (1,0) [0|255] "" Vector__XXX
 SG_ Led0005_value : 32|8@1+ (1,0) [0|255] "" Vector__XXX
 SG_ Led0004_value : 24|8@1+ (1,0) [0|255] "" Vector__XXX
 SG_ Led0003_value : 16|8@1+ (1,0) [0|255] "" Vector__XXX
 SG_ Led0002_value : 8|8@1+ (1,0) [0|255] "" Vector__XXX
 SG_ Led0001_value : 0|8@1+ (1,0) [0|255] "" Vector__XXX

BO_ 1035 ISC_Ctrl_LED_B_11: 64 ISC
 SG_ Led0064_value : 504|8@1+ (1,0) [0|255] "" Vector__XXX
 SG_ Led0063_value : 496|8@1+ (1,0) [0|255] "" Vector__XXX
 SG_ Led0062_value : 488|8@1+ (1,0) [0|255] "" Vector__XXX
 SG_ Led0061_value : 480|8@1+ (1,0) [0|255] "" Vector__XXX
 SG_ Led0060_value : 472|8@1+ (1,0) [0|255] "" Vector__XXX
 SG_ Led0059_value : 464|8@1+ (1,0) [0|255] "" Vector__XXX
 SG_ Led0058_value : 456|8@1+ (1,0) [0|255] "" Vector__XXX
 SG_ Led0057_value : 448|8@1+ (1,0) [0|255] "" Vector__XXX
 SG_ Led0056_value : 440|8@1+ (1,0) [0|255] "" Vector__XXX
 SG_ Led0055_value : 432|8@1+ (1,0) [0|255] "" Vector__XXX
 SG_ Led0054_value : 424|8@1+ (1,0) [0|255] "" Vector__XXX
 SG_ Led0053_value : 416|8@1+ (1,0) [0|255] "" Vector__XXX
 SG_ Led0052_value : 408|8@1+ (1,0) [0|255] "" Vector__XXX
 SG_ Led0051_value : 400|8@1+ (1,0) [0|255] "" Vector__XXX
 SG_ Led0050_value : 392|8@1+ (1,0) [0|255] "" Vector__XXX
 SG_ Led0049_value : 384|8@1+ (1,0) [0|255] "" Vector__XXX
 SG_ Led0048_value : 376|8@1+ (1,0) [0|255] "" Vector__XXX
 SG_ Led0047_value : 368|8@1+ (1,0) [0|255] "" Vector__XXX
 SG_ Led0046_value : 360|8@1+ (1,0) [0|255] "" Vector__XXX
 SG_ Led0045_value : 352|8@1+ (1,0) [0|255] "" Vector__XXX
 SG_ Led0044_value : 344|8@1+ (1,0) [0|255] "" Vector__XXX
 SG_ Led0043_value : 336|8@1+ (1,0) [0|255] "" Vector__XXX
 SG_ Led0042_value : 328|8@1+ (1,0) [0|255] "" Vector__XXX
 SG_ Led0041_value : 320|8@1+ (1,0) [0|255] "" Vector__XXX
 SG_ Led0040_value : 312|8@1+ (1,0) [0|255] "" Vector__XXX
 SG_ Led0039_value : 304|8@1+ (1,0) [0|255] "" Vector__XXX
 SG_ Led0038_value : 296|8@1+ (1,0) [0|255] "" Vector__XXX
 SG_ Led0037_value : 288|8@1+ (1,0) [0|255] "" Vector__XXX
 SG_ Led0036_value : 280|8@1+ (1,0) [0|255] "" Vector__XXX
 SG_ Led0035_value : 272|8@1+ (1,0) [0|255] "" Vector__XXX
 SG_ Led0034_value : 264|8@1+ (1,0) [0|255] "" Vector__XXX
 SG_ Led0033_value : 256|8@1+ (1,0) [0|255] "" Vector__XXX
 SG_ Led0032_value : 248|8@1+ (1,0) [0|255] "" Vector__XXX
 SG_ Led0031_value : 240|8@1+ (1,0) [0|255] "" Vector__XXX
 SG_ Led0030_value : 232|8@1+ (1,0) [0|255] "" Vector__XXX
 SG_ Led0029_value : 224|8@1+ (1,0) [0|255] "" Vector__XXX
 SG_ Led0028_value : 216|8@1+ (1,0) [0|255] "" Vector__XXX
 SG_ Led0027_value : 208|8@1+ (1,0) [0|255] "" Vector__XXX
 SG_ Led0026_value : 200|8@1+ (1,0) [0|255] "" Vector__XXX
 SG_ Led0025_value : 192|8@1+ (1,0) [0|255] "" Vector__XXX
 SG_ Led0024_value : 184|8@1+ (1,0) [0|255] "" Vector__XXX
 SG_ Led0023_value : 176|8@1+ (1,0) [0|255] "" Vector__XXX
 SG_ Led0022_value : 168|8@1+ (1,0) [0|255] "" Vector__XXX
 SG_ Led0021_value : 160|8@1+ (1,0) [0|255] "" Vector__XXX
 SG_ Led0020_value : 152|8@1+ (1,0) [0|255] "" Vector__XXX
 SG_ Led0019_value : 144|8@1+ (1,0) [0|255] "" Vector__XXX
 SG_ Led0018_value : 136|8@1+ (1,0) [0|255] "" Vector__XXX
 SG_ Led0017_value : 128|8@1+ (1,0) [0|255] "" Vector__XXX
 SG_ Led0016_value : 120|8@1+ (1,0) [0|255] "" Vector__XXX
 SG_ Led0015_value : 112|8@1+ (1,0) [0|255] "" Vector__XXX
 SG_ Led0014_value : 104|8@1+ (1,0) [0|255] "" Vector__XXX
 SG_ Led0013_value : 96|8@1+ (1,0) [0|255] "" Vector__XXX
 SG_ Led0012_value : 88|8@1+ (1,0) [0|255] "" Vector__XXX
 SG_ Led0011_value : 80|8@1+ (1,0) [0|255] "" Vector__XXX
 SG_ Led0010_value : 72|8@1+ (1,0) [0|255] "" Vector__XXX
 SG_ Led0009_value : 64|8@1+ (1,0) [0|255] "" Vector__XXX
 SG_ Led0008_value : 56|8@1+ (1,0) [0|255] "" Vector__XXX
 SG_ Led0007_value : 48|8@1+ (1,0) [0|255] "" Vector__XXX
 SG_ Led0006_value : 40|8@1+ (1,0) [0|255] "" Vector__XXX
 SG_ Led0005_value : 32|8@1+ (1,0) [0|255] "" Vector__XXX
 SG_ Led0004_value : 24|8@1+ (1,0) [0|255] "" Vector__XXX
 SG_ Led0003_value : 16|8@1+ (1,0) [0|255] "" Vector__XXX
 SG_ Led0002_value : 8|8@1+ (1,0) [0|255] "" Vector__XXX
 SG_ Led0001_value : 0|8@1+ (1,0) [0|255] "" Vector__XXX

BO_ 1034 ISC_Ctrl_LED_B_10: 64 ISC
 SG_ Led0064_value : 504|8@1+ (1,0) [0|255] "" Vector__XXX
 SG_ Led0063_value : 496|8@1+ (1,0) [0|255] "" Vector__XXX
 SG_ Led0062_value : 488|8@1+ (1,0) [0|255] "" Vector__XXX
 SG_ Led0061_value : 480|8@1+ (1,0) [0|255] "" Vector__XXX
 SG_ Led0060_value : 472|8@1+ (1,0) [0|255] "" Vector__XXX
 SG_ Led0059_value : 464|8@1+ (1,0) [0|255] "" Vector__XXX
 SG_ Led0058_value : 456|8@1+ (1,0) [0|255] "" Vector__XXX
 SG_ Led0057_value : 448|8@1+ (1,0) [0|255] "" Vector__XXX
 SG_ Led0056_value : 440|8@1+ (1,0) [0|255] "" Vector__XXX
 SG_ Led0055_value : 432|8@1+ (1,0) [0|255] "" Vector__XXX
 SG_ Led0054_value : 424|8@1+ (1,0) [0|255] "" Vector__XXX
 SG_ Led0053_value : 416|8@1+ (1,0) [0|255] "" Vector__XXX
 SG_ Led0052_value : 408|8@1+ (1,0) [0|255] "" Vector__XXX
 SG_ Led0051_value : 400|8@1+ (1,0) [0|255] "" Vector__XXX
 SG_ Led0050_value : 392|8@1+ (1,0) [0|255] "" Vector__XXX
 SG_ Led0049_value : 384|8@1+ (1,0) [0|255] "" Vector__XXX
 SG_ Led0048_value : 376|8@1+ (1,0) [0|255] "" Vector__XXX
 SG_ Led0047_value : 368|8@1+ (1,0) [0|255] "" Vector__XXX
 SG_ Led0046_value : 360|8@1+ (1,0) [0|255] "" Vector__XXX
 SG_ Led0045_value : 352|8@1+ (1,0) [0|255] "" Vector__XXX
 SG_ Led0044_value : 344|8@1+ (1,0) [0|255] "" Vector__XXX
 SG_ Led0043_value : 336|8@1+ (1,0) [0|255] "" Vector__XXX
 SG_ Led0042_value : 328|8@1+ (1,0) [0|255] "" Vector__XXX
 SG_ Led0041_value : 320|8@1+ (1,0) [0|255] "" Vector__XXX
 SG_ Led0040_value : 312|8@1+ (1,0) [0|255] "" Vector__XXX
 SG_ Led0039_value : 304|8@1+ (1,0) [0|255] "" Vector__XXX
 SG_ Led0038_value : 296|8@1+ (1,0) [0|255] "" Vector__XXX
 SG_ Led0037_value : 288|8@1+ (1,0) [0|255] "" Vector__XXX
 SG_ Led0036_value : 280|8@1+ (1,0) [0|255] "" Vector__XXX
 SG_ Led0035_value : 272|8@1+ (1,0) [0|255] "" Vector__XXX
 SG_ Led0034_value : 264|8@1+ (1,0) [0|255] "" Vector__XXX
 SG_ Led0033_value : 256|8@1+ (1,0) [0|255] "" Vector__XXX
 SG_ Led0032_value : 248|8@1+ (1,0) [0|255] "" Vector__XXX
 SG_ Led0031_value : 240|8@1+ (1,0) [0|255] "" Vector__XXX
 SG_ Led0030_value : 232|8@1+ (1,0) [0|255] "" Vector__XXX
 SG_ Led0029_value : 224|8@1+ (1,0) [0|255] "" Vector__XXX
 SG_ Led0028_value : 216|8@1+ (1,0) [0|255] "" Vector__XXX
 SG_ Led0027_value : 208|8@1+ (1,0) [0|255] "" Vector__XXX
 SG_ Led0026_value : 200|8@1+ (1,0) [0|255] "" Vector__XXX
 SG_ Led0025_value : 192|8@1+ (1,0) [0|255] "" Vector__XXX
 SG_ Led0024_value : 184|8@1+ (1,0) [0|255] "" Vector__XXX
 SG_ Led0023_value : 176|8@1+ (1,0) [0|255] "" Vector__XXX
 SG_ Led0022_value : 168|8@1+ (1,0) [0|255] "" Vector__XXX
 SG_ Led0021_value : 160|8@1+ (1,0) [0|255] "" Vector__XXX
 SG_ Led0020_value : 152|8@1+ (1,0) [0|255] "" Vector__XXX
 SG_ Led0019_value : 144|8@1+ (1,0) [0|255] "" Vector__XXX
 SG_ Led0018_value : 136|8@1+ (1,0) [0|255] "" Vector__XXX
 SG_ Led0017_value : 128|8@1+ (1,0) [0|255] "" Vector__XXX
 SG_ Led0016_value : 120|8@1+ (1,0) [0|255] "" Vector__XXX
 SG_ Led0015_value : 112|8@1+ (1,0) [0|255] "" Vector__XXX
 SG_ Led0014_value : 104|8@1+ (1,0) [0|255] "" Vector__XXX
 SG_ Led0013_value : 96|8@1+ (1,0) [0|255] "" Vector__XXX
 SG_ Led0012_value : 88|8@1+ (1,0) [0|255] "" Vector__XXX
 SG_ Led0011_value : 80|8@1+ (1,0) [0|255] "" Vector__XXX
 SG_ Led0010_value : 72|8@1+ (1,0) [0|255] "" Vector__XXX
 SG_ Led0009_value : 64|8@1+ (1,0) [0|255] "" Vector__XXX
 SG_ Led0008_value : 56|8@1+ (1,0) [0|255] "" Vector__XXX
 SG_ Led0007_value : 48|8@1+ (1,0) [0|255] "" Vector__XXX
 SG_ Led0006_value : 40|8@1+ (1,0) [0|255] "" Vector__XXX
 SG_ Led0005_value : 32|8@1+ (1,0) [0|255] "" Vector__XXX
 SG_ Led0004_value : 24|8@1+ (1,0) [0|255] "" Vector__XXX
 SG_ Led0003_value : 16|8@1+ (1,0) [0|255] "" Vector__XXX
 SG_ Led0002_value : 8|8@1+ (1,0) [0|255] "" Vector__XXX
 SG_ Led0001_value : 0|8@1+ (1,0) [0|255] "" Vector__XXX

BO_ 1033 ISC_Ctrl_LED_B_09: 64 ISC
 SG_ Led0064_value : 504|8@1+ (1,0) [0|255] "" Vector__XXX
 SG_ Led0063_value : 496|8@1+ (1,0) [0|255] "" Vector__XXX
 SG_ Led0062_value : 488|8@1+ (1,0) [0|255] "" Vector__XXX
 SG_ Led0061_value : 480|8@1+ (1,0) [0|255] "" Vector__XXX
 SG_ Led0060_value : 472|8@1+ (1,0) [0|255] "" Vector__XXX
 SG_ Led0059_value : 464|8@1+ (1,0) [0|255] "" Vector__XXX
 SG_ Led0058_value : 456|8@1+ (1,0) [0|255] "" Vector__XXX
 SG_ Led0057_value : 448|8@1+ (1,0) [0|255] "" Vector__XXX
 SG_ Led0056_value : 440|8@1+ (1,0) [0|255] "" Vector__XXX
 SG_ Led0055_value : 432|8@1+ (1,0) [0|255] "" Vector__XXX
 SG_ Led0054_value : 424|8@1+ (1,0) [0|255] "" Vector__XXX
 SG_ Led0053_value : 416|8@1+ (1,0) [0|255] "" Vector__XXX
 SG_ Led0052_value : 408|8@1+ (1,0) [0|255] "" Vector__XXX
 SG_ Led0051_value : 400|8@1+ (1,0) [0|255] "" Vector__XXX
 SG_ Led0050_value : 392|8@1+ (1,0) [0|255] "" Vector__XXX
 SG_ Led0049_value : 384|8@1+ (1,0) [0|255] "" Vector__XXX
 SG_ Led0048_value : 376|8@1+ (1,0) [0|255] "" Vector__XXX
 SG_ Led0047_value : 368|8@1+ (1,0) [0|255] "" Vector__XXX
 SG_ Led0046_value : 360|8@1+ (1,0) [0|255] "" Vector__XXX
 SG_ Led0045_value : 352|8@1+ (1,0) [0|255] "" Vector__XXX
 SG_ Led0044_value : 344|8@1+ (1,0) [0|255] "" Vector__XXX
 SG_ Led0043_value : 336|8@1+ (1,0) [0|255] "" Vector__XXX
 SG_ Led0042_value : 328|8@1+ (1,0) [0|255] "" Vector__XXX
 SG_ Led0041_value : 320|8@1+ (1,0) [0|255] "" Vector__XXX
 SG_ Led0040_value : 312|8@1+ (1,0) [0|255] "" Vector__XXX
 SG_ Led0039_value : 304|8@1+ (1,0) [0|255] "" Vector__XXX
 SG_ Led0038_value : 296|8@1+ (1,0) [0|255] "" Vector__XXX
 SG_ Led0037_value : 288|8@1+ (1,0) [0|255] "" Vector__XXX
 SG_ Led0036_value : 280|8@1+ (1,0) [0|255] "" Vector__XXX
 SG_ Led0035_value : 272|8@1+ (1,0) [0|255] "" Vector__XXX
 SG_ Led0034_value : 264|8@1+ (1,0) [0|255] "" Vector__XXX
 SG_ Led0033_value : 256|8@1+ (1,0) [0|255] "" Vector__XXX
 SG_ Led0032_value : 248|8@1+ (1,0) [0|255] "" Vector__XXX
 SG_ Led0031_value : 240|8@1+ (1,0) [0|255] "" Vector__XXX
 SG_ Led0030_value : 232|8@1+ (1,0) [0|255] "" Vector__XXX
 SG_ Led0029_value : 224|8@1+ (1,0) [0|255] "" Vector__XXX
 SG_ Led0028_value : 216|8@1+ (1,0) [0|255] "" Vector__XXX
 SG_ Led0027_value : 208|8@1+ (1,0) [0|255] "" Vector__XXX
 SG_ Led0026_value : 200|8@1+ (1,0) [0|255] "" Vector__XXX
 SG_ Led0025_value : 192|8@1+ (1,0) [0|255] "" Vector__XXX
 SG_ Led0024_value : 184|8@1+ (1,0) [0|255] "" Vector__XXX
 SG_ Led0023_value : 176|8@1+ (1,0) [0|255] "" Vector__XXX
 SG_ Led0022_value : 168|8@1+ (1,0) [0|255] "" Vector__XXX
 SG_ Led0021_value : 160|8@1+ (1,0) [0|255] "" Vector__XXX
 SG_ Led0020_value : 152|8@1+ (1,0) [0|255] "" Vector__XXX
 SG_ Led0019_value : 144|8@1+ (1,0) [0|255] "" Vector__XXX
 SG_ Led0018_value : 136|8@1+ (1,0) [0|255] "" Vector__XXX
 SG_ Led0017_value : 128|8@1+ (1,0) [0|255] "" Vector__XXX
 SG_ Led0016_value : 120|8@1+ (1,0) [0|255] "" Vector__XXX
 SG_ Led0015_value : 112|8@1+ (1,0) [0|255] "" Vector__XXX
 SG_ Led0014_value : 104|8@1+ (1,0) [0|255] "" Vector__XXX
 SG_ Led0013_value : 96|8@1+ (1,0) [0|255] "" Vector__XXX
 SG_ Led0012_value : 88|8@1+ (1,0) [0|255] "" Vector__XXX
 SG_ Led0011_value : 80|8@1+ (1,0) [0|255] "" Vector__XXX
 SG_ Led0010_value : 72|8@1+ (1,0) [0|255] "" Vector__XXX
 SG_ Led0009_value : 64|8@1+ (1,0) [0|255] "" Vector__XXX
 SG_ Led0008_value : 56|8@1+ (1,0) [0|255] "" Vector__XXX
 SG_ Led0007_value : 48|8@1+ (1,0) [0|255] "" Vector__XXX
 SG_ Led0006_value : 40|8@1+ (1,0) [0|255] "" Vector__XXX
 SG_ Led0005_value : 32|8@1+ (1,0) [0|255] "" Vector__XXX
 SG_ Led0004_value : 24|8@1+ (1,0) [0|255] "" Vector__XXX
 SG_ Led0003_value : 16|8@1+ (1,0) [0|255] "" Vector__XXX
 SG_ Led0002_value : 8|8@1+ (1,0) [0|255] "" Vector__XXX
 SG_ Led0001_value : 0|8@1+ (1,0) [0|255] "" Vector__XXX

BO_ 1032 ISC_Ctrl_LED_B_08: 64 ISC
 SG_ Led0064_value : 504|8@1+ (1,0) [0|255] "" Vector__XXX
 SG_ Led0063_value : 496|8@1+ (1,0) [0|255] "" Vector__XXX
 SG_ Led0062_value : 488|8@1+ (1,0) [0|255] "" Vector__XXX
 SG_ Led0061_value : 480|8@1+ (1,0) [0|255] "" Vector__XXX
 SG_ Led0060_value : 472|8@1+ (1,0) [0|255] "" Vector__XXX
 SG_ Led0059_value : 464|8@1+ (1,0) [0|255] "" Vector__XXX
 SG_ Led0058_value : 456|8@1+ (1,0) [0|255] "" Vector__XXX
 SG_ Led0057_value : 448|8@1+ (1,0) [0|255] "" Vector__XXX
 SG_ Led0056_value : 440|8@1+ (1,0) [0|255] "" Vector__XXX
 SG_ Led0055_value : 432|8@1+ (1,0) [0|255] "" Vector__XXX
 SG_ Led0054_value : 424|8@1+ (1,0) [0|255] "" Vector__XXX
 SG_ Led0053_value : 416|8@1+ (1,0) [0|255] "" Vector__XXX
 SG_ Led0052_value : 408|8@1+ (1,0) [0|255] "" Vector__XXX
 SG_ Led0051_value : 400|8@1+ (1,0) [0|255] "" Vector__XXX
 SG_ Led0050_value : 392|8@1+ (1,0) [0|255] "" Vector__XXX
 SG_ Led0049_value : 384|8@1+ (1,0) [0|255] "" Vector__XXX
 SG_ Led0048_value : 376|8@1+ (1,0) [0|255] "" Vector__XXX
 SG_ Led0047_value : 368|8@1+ (1,0) [0|255] "" Vector__XXX
 SG_ Led0046_value : 360|8@1+ (1,0) [0|255] "" Vector__XXX
 SG_ Led0045_value : 352|8@1+ (1,0) [0|255] "" Vector__XXX
 SG_ Led0044_value : 344|8@1+ (1,0) [0|255] "" Vector__XXX
 SG_ Led0043_value : 336|8@1+ (1,0) [0|255] "" Vector__XXX
 SG_ Led0042_value : 328|8@1+ (1,0) [0|255] "" Vector__XXX
 SG_ Led0041_value : 320|8@1+ (1,0) [0|255] "" Vector__XXX
 SG_ Led0040_value : 312|8@1+ (1,0) [0|255] "" Vector__XXX
 SG_ Led0039_value : 304|8@1+ (1,0) [0|255] "" Vector__XXX
 SG_ Led0038_value : 296|8@1+ (1,0) [0|255] "" Vector__XXX
 SG_ Led0037_value : 288|8@1+ (1,0) [0|255] "" Vector__XXX
 SG_ Led0036_value : 280|8@1+ (1,0) [0|255] "" Vector__XXX
 SG_ Led0035_value : 272|8@1+ (1,0) [0|255] "" Vector__XXX
 SG_ Led0034_value : 264|8@1+ (1,0) [0|255] "" Vector__XXX
 SG_ Led0033_value : 256|8@1+ (1,0) [0|255] "" Vector__XXX
 SG_ Led0032_value : 248|8@1+ (1,0) [0|255] "" Vector__XXX
 SG_ Led0031_value : 240|8@1+ (1,0) [0|255] "" Vector__XXX
 SG_ Led0030_value : 232|8@1+ (1,0) [0|255] "" Vector__XXX
 SG_ Led0029_value : 224|8@1+ (1,0) [0|255] "" Vector__XXX
 SG_ Led0028_value : 216|8@1+ (1,0) [0|255] "" Vector__XXX
 SG_ Led0027_value : 208|8@1+ (1,0) [0|255] "" Vector__XXX
 SG_ Led0026_value : 200|8@1+ (1,0) [0|255] "" Vector__XXX
 SG_ Led0025_value : 192|8@1+ (1,0) [0|255] "" Vector__XXX
 SG_ Led0024_value : 184|8@1+ (1,0) [0|255] "" Vector__XXX
 SG_ Led0023_value : 176|8@1+ (1,0) [0|255] "" Vector__XXX
 SG_ Led0022_value : 168|8@1+ (1,0) [0|255] "" Vector__XXX
 SG_ Led0021_value : 160|8@1+ (1,0) [0|255] "" Vector__XXX
 SG_ Led0020_value : 152|8@1+ (1,0) [0|255] "" Vector__XXX
 SG_ Led0019_value : 144|8@1+ (1,0) [0|255] "" Vector__XXX
 SG_ Led0018_value : 136|8@1+ (1,0) [0|255] "" Vector__XXX
 SG_ Led0017_value : 128|8@1+ (1,0) [0|255] "" Vector__XXX
 SG_ Led0016_value : 120|8@1+ (1,0) [0|255] "" Vector__XXX
 SG_ Led0015_value : 112|8@1+ (1,0) [0|255] "" Vector__XXX
 SG_ Led0014_value : 104|8@1+ (1,0) [0|255] "" Vector__XXX
 SG_ Led0013_value : 96|8@1+ (1,0) [0|255] "" Vector__XXX
 SG_ Led0012_value : 88|8@1+ (1,0) [0|255] "" Vector__XXX
 SG_ Led0011_value : 80|8@1+ (1,0) [0|255] "" Vector__XXX
 SG_ Led0010_value : 72|8@1+ (1,0) [0|255] "" Vector__XXX
 SG_ Led0009_value : 64|8@1+ (1,0) [0|255] "" Vector__XXX
 SG_ Led0008_value : 56|8@1+ (1,0) [0|255] "" Vector__XXX
 SG_ Led0007_value : 48|8@1+ (1,0) [0|255] "" Vector__XXX
 SG_ Led0006_value : 40|8@1+ (1,0) [0|255] "" Vector__XXX
 SG_ Led0005_value : 32|8@1+ (1,0) [0|255] "" Vector__XXX
 SG_ Led0004_value : 24|8@1+ (1,0) [0|255] "" Vector__XXX
 SG_ Led0003_value : 16|8@1+ (1,0) [0|255] "" Vector__XXX
 SG_ Led0002_value : 8|8@1+ (1,0) [0|255] "" Vector__XXX
 SG_ Led0001_value : 0|8@1+ (1,0) [0|255] "" Vector__XXX

BO_ 1031 ISC_Ctrl_LED_B_07: 64 ISC
 SG_ Led0064_value : 504|8@1+ (1,0) [0|255] "" Vector__XXX
 SG_ Led0063_value : 496|8@1+ (1,0) [0|255] "" Vector__XXX
 SG_ Led0062_value : 488|8@1+ (1,0) [0|255] "" Vector__XXX
 SG_ Led0061_value : 480|8@1+ (1,0) [0|255] "" Vector__XXX
 SG_ Led0060_value : 472|8@1+ (1,0) [0|255] "" Vector__XXX
 SG_ Led0059_value : 464|8@1+ (1,0) [0|255] "" Vector__XXX
 SG_ Led0058_value : 456|8@1+ (1,0) [0|255] "" Vector__XXX
 SG_ Led0057_value : 448|8@1+ (1,0) [0|255] "" Vector__XXX
 SG_ Led0056_value : 440|8@1+ (1,0) [0|255] "" Vector__XXX
 SG_ Led0055_value : 432|8@1+ (1,0) [0|255] "" Vector__XXX
 SG_ Led0054_value : 424|8@1+ (1,0) [0|255] "" Vector__XXX
 SG_ Led0053_value : 416|8@1+ (1,0) [0|255] "" Vector__XXX
 SG_ Led0052_value : 408|8@1+ (1,0) [0|255] "" Vector__XXX
 SG_ Led0051_value : 400|8@1+ (1,0) [0|255] "" Vector__XXX
 SG_ Led0050_value : 392|8@1+ (1,0) [0|255] "" Vector__XXX
 SG_ Led0049_value : 384|8@1+ (1,0) [0|255] "" Vector__XXX
 SG_ Led0048_value : 376|8@1+ (1,0) [0|255] "" Vector__XXX
 SG_ Led0047_value : 368|8@1+ (1,0) [0|255] "" Vector__XXX
 SG_ Led0046_value : 360|8@1+ (1,0) [0|255] "" Vector__XXX
 SG_ Led0045_value : 352|8@1+ (1,0) [0|255] "" Vector__XXX
 SG_ Led0044_value : 344|8@1+ (1,0) [0|255] "" Vector__XXX
 SG_ Led0043_value : 336|8@1+ (1,0) [0|255] "" Vector__XXX
 SG_ Led0042_value : 328|8@1+ (1,0) [0|255] "" Vector__XXX
 SG_ Led0041_value : 320|8@1+ (1,0) [0|255] "" Vector__XXX
 SG_ Led0040_value : 312|8@1+ (1,0) [0|255] "" Vector__XXX
 SG_ Led0039_value : 304|8@1+ (1,0) [0|255] "" Vector__XXX
 SG_ Led0038_value : 296|8@1+ (1,0) [0|255] "" Vector__XXX
 SG_ Led0037_value : 288|8@1+ (1,0) [0|255] "" Vector__XXX
 SG_ Led0036_value : 280|8@1+ (1,0) [0|255] "" Vector__XXX
 SG_ Led0035_value : 272|8@1+ (1,0) [0|255] "" Vector__XXX
 SG_ Led0034_value : 264|8@1+ (1,0) [0|255] "" Vector__XXX
 SG_ Led0033_value : 256|8@1+ (1,0) [0|255] "" Vector__XXX
 SG_ Led0032_value : 248|8@1+ (1,0) [0|255] "" Vector__XXX
 SG_ Led0031_value : 240|8@1+ (1,0) [0|255] "" Vector__XXX
 SG_ Led0030_value : 232|8@1+ (1,0) [0|255] "" Vector__XXX
 SG_ Led0029_value : 224|8@1+ (1,0) [0|255] "" Vector__XXX
 SG_ Led0028_value : 216|8@1+ (1,0) [0|255] "" Vector__XXX
 SG_ Led0027_value : 208|8@1+ (1,0) [0|255] "" Vector__XXX
 SG_ Led0026_value : 200|8@1+ (1,0) [0|255] "" Vector__XXX
 SG_ Led0025_value : 192|8@1+ (1,0) [0|255] "" Vector__XXX
 SG_ Led0024_value : 184|8@1+ (1,0) [0|255] "" Vector__XXX
 SG_ Led0023_value : 176|8@1+ (1,0) [0|255] "" Vector__XXX
 SG_ Led0022_value : 168|8@1+ (1,0) [0|255] "" Vector__XXX
 SG_ Led0021_value : 160|8@1+ (1,0) [0|255] "" Vector__XXX
 SG_ Led0020_value : 152|8@1+ (1,0) [0|255] "" Vector__XXX
 SG_ Led0019_value : 144|8@1+ (1,0) [0|255] "" Vector__XXX
 SG_ Led0018_value : 136|8@1+ (1,0) [0|255] "" Vector__XXX
 SG_ Led0017_value : 128|8@1+ (1,0) [0|255] "" Vector__XXX
 SG_ Led0016_value : 120|8@1+ (1,0) [0|255] "" Vector__XXX
 SG_ Led0015_value : 112|8@1+ (1,0) [0|255] "" Vector__XXX
 SG_ Led0014_value : 104|8@1+ (1,0) [0|255] "" Vector__XXX
 SG_ Led0013_value : 96|8@1+ (1,0) [0|255] "" Vector__XXX
 SG_ Led0012_value : 88|8@1+ (1,0) [0|255] "" Vector__XXX
 SG_ Led0011_value : 80|8@1+ (1,0) [0|255] "" Vector__XXX
 SG_ Led0010_value : 72|8@1+ (1,0) [0|255] "" Vector__XXX
 SG_ Led0009_value : 64|8@1+ (1,0) [0|255] "" Vector__XXX
 SG_ Led0008_value : 56|8@1+ (1,0) [0|255] "" Vector__XXX
 SG_ Led0007_value : 48|8@1+ (1,0) [0|255] "" Vector__XXX
 SG_ Led0006_value : 40|8@1+ (1,0) [0|255] "" Vector__XXX
 SG_ Led0005_value : 32|8@1+ (1,0) [0|255] "" Vector__XXX
 SG_ Led0004_value : 24|8@1+ (1,0) [0|255] "" Vector__XXX
 SG_ Led0003_value : 16|8@1+ (1,0) [0|255] "" Vector__XXX
 SG_ Led0002_value : 8|8@1+ (1,0) [0|255] "" Vector__XXX
 SG_ Led0001_value : 0|8@1+ (1,0) [0|255] "" Vector__XXX

BO_ 1030 ISC_Ctrl_LED_B_06: 64 ISC
 SG_ Led0064_value : 504|8@1+ (1,0) [0|255] "" Vector__XXX
 SG_ Led0063_value : 496|8@1+ (1,0) [0|255] "" Vector__XXX
 SG_ Led0062_value : 488|8@1+ (1,0) [0|255] "" Vector__XXX
 SG_ Led0061_value : 480|8@1+ (1,0) [0|255] "" Vector__XXX
 SG_ Led0060_value : 472|8@1+ (1,0) [0|255] "" Vector__XXX
 SG_ Led0059_value : 464|8@1+ (1,0) [0|255] "" Vector__XXX
 SG_ Led0058_value : 456|8@1+ (1,0) [0|255] "" Vector__XXX
 SG_ Led0057_value : 448|8@1+ (1,0) [0|255] "" Vector__XXX
 SG_ Led0056_value : 440|8@1+ (1,0) [0|255] "" Vector__XXX
 SG_ Led0055_value : 432|8@1+ (1,0) [0|255] "" Vector__XXX
 SG_ Led0054_value : 424|8@1+ (1,0) [0|255] "" Vector__XXX
 SG_ Led0053_value : 416|8@1+ (1,0) [0|255] "" Vector__XXX
 SG_ Led0052_value : 408|8@1+ (1,0) [0|255] "" Vector__XXX
 SG_ Led0051_value : 400|8@1+ (1,0) [0|255] "" Vector__XXX
 SG_ Led0050_value : 392|8@1+ (1,0) [0|255] "" Vector__XXX
 SG_ Led0049_value : 384|8@1+ (1,0) [0|255] "" Vector__XXX
 SG_ Led0048_value : 376|8@1+ (1,0) [0|255] "" Vector__XXX
 SG_ Led0047_value : 368|8@1+ (1,0) [0|255] "" Vector__XXX
 SG_ Led0046_value : 360|8@1+ (1,0) [0|255] "" Vector__XXX
 SG_ Led0045_value : 352|8@1+ (1,0) [0|255] "" Vector__XXX
 SG_ Led0044_value : 344|8@1+ (1,0) [0|255] "" Vector__XXX
 SG_ Led0043_value : 336|8@1+ (1,0) [0|255] "" Vector__XXX
 SG_ Led0042_value : 328|8@1+ (1,0) [0|255] "" Vector__XXX
 SG_ Led0041_value : 320|8@1+ (1,0) [0|255] "" Vector__XXX
 SG_ Led0040_value : 312|8@1+ (1,0) [0|255] "" Vector__XXX
 SG_ Led0039_value : 304|8@1+ (1,0) [0|255] "" Vector__XXX
 SG_ Led0038_value : 296|8@1+ (1,0) [0|255] "" Vector__XXX
 SG_ Led0037_value : 288|8@1+ (1,0) [0|255] "" Vector__XXX
 SG_ Led0036_value : 280|8@1+ (1,0) [0|255] "" Vector__XXX
 SG_ Led0035_value : 272|8@1+ (1,0) [0|255] "" Vector__XXX
 SG_ Led0034_value : 264|8@1+ (1,0) [0|255] "" Vector__XXX
 SG_ Led0033_value : 256|8@1+ (1,0) [0|255] "" Vector__XXX
 SG_ Led0032_value : 248|8@1+ (1,0) [0|255] "" Vector__XXX
 SG_ Led0031_value : 240|8@1+ (1,0) [0|255] "" Vector__XXX
 SG_ Led0030_value : 232|8@1+ (1,0) [0|255] "" Vector__XXX
 SG_ Led0029_value : 224|8@1+ (1,0) [0|255] "" Vector__XXX
 SG_ Led0028_value : 216|8@1+ (1,0) [0|255] "" Vector__XXX
 SG_ Led0027_value : 208|8@1+ (1,0) [0|255] "" Vector__XXX
 SG_ Led0026_value : 200|8@1+ (1,0) [0|255] "" Vector__XXX
 SG_ Led0025_value : 192|8@1+ (1,0) [0|255] "" Vector__XXX
 SG_ Led0024_value : 184|8@1+ (1,0) [0|255] "" Vector__XXX
 SG_ Led0023_value : 176|8@1+ (1,0) [0|255] "" Vector__XXX
 SG_ Led0022_value : 168|8@1+ (1,0) [0|255] "" Vector__XXX
 SG_ Led0021_value : 160|8@1+ (1,0) [0|255] "" Vector__XXX
 SG_ Led0020_value : 152|8@1+ (1,0) [0|255] "" Vector__XXX
 SG_ Led0019_value : 144|8@1+ (1,0) [0|255] "" Vector__XXX
 SG_ Led0018_value : 136|8@1+ (1,0) [0|255] "" Vector__XXX
 SG_ Led0017_value : 128|8@1+ (1,0) [0|255] "" Vector__XXX
 SG_ Led0016_value : 120|8@1+ (1,0) [0|255] "" Vector__XXX
 SG_ Led0015_value : 112|8@1+ (1,0) [0|255] "" Vector__XXX
 SG_ Led0014_value : 104|8@1+ (1,0) [0|255] "" Vector__XXX
 SG_ Led0013_value : 96|8@1+ (1,0) [0|255] "" Vector__XXX
 SG_ Led0012_value : 88|8@1+ (1,0) [0|255] "" Vector__XXX
 SG_ Led0011_value : 80|8@1+ (1,0) [0|255] "" Vector__XXX
 SG_ Led0010_value : 72|8@1+ (1,0) [0|255] "" Vector__XXX
 SG_ Led0009_value : 64|8@1+ (1,0) [0|255] "" Vector__XXX
 SG_ Led0008_value : 56|8@1+ (1,0) [0|255] "" Vector__XXX
 SG_ Led0007_value : 48|8@1+ (1,0) [0|255] "" Vector__XXX
 SG_ Led0006_value : 40|8@1+ (1,0) [0|255] "" Vector__XXX
 SG_ Led0005_value : 32|8@1+ (1,0) [0|255] "" Vector__XXX
 SG_ Led0004_value : 24|8@1+ (1,0) [0|255] "" Vector__XXX
 SG_ Led0003_value : 16|8@1+ (1,0) [0|255] "" Vector__XXX
 SG_ Led0002_value : 8|8@1+ (1,0) [0|255] "" Vector__XXX
 SG_ Led0001_value : 0|8@1+ (1,0) [0|255] "" Vector__XXX

BO_ 1029 ISC_Ctrl_LED_B_05: 64 ISC
 SG_ Led0064_value : 504|8@1+ (1,0) [0|255] "" Vector__XXX
 SG_ Led0063_value : 496|8@1+ (1,0) [0|255] "" Vector__XXX
 SG_ Led0062_value : 488|8@1+ (1,0) [0|255] "" Vector__XXX
 SG_ Led0061_value : 480|8@1+ (1,0) [0|255] "" Vector__XXX
 SG_ Led0060_value : 472|8@1+ (1,0) [0|255] "" Vector__XXX
 SG_ Led0059_value : 464|8@1+ (1,0) [0|255] "" Vector__XXX
 SG_ Led0058_value : 456|8@1+ (1,0) [0|255] "" Vector__XXX
 SG_ Led0057_value : 448|8@1+ (1,0) [0|255] "" Vector__XXX
 SG_ Led0056_value : 440|8@1+ (1,0) [0|255] "" Vector__XXX
 SG_ Led0055_value : 432|8@1+ (1,0) [0|255] "" Vector__XXX
 SG_ Led0054_value : 424|8@1+ (1,0) [0|255] "" Vector__XXX
 SG_ Led0053_value : 416|8@1+ (1,0) [0|255] "" Vector__XXX
 SG_ Led0052_value : 408|8@1+ (1,0) [0|255] "" Vector__XXX
 SG_ Led0051_value : 400|8@1+ (1,0) [0|255] "" Vector__XXX
 SG_ Led0050_value : 392|8@1+ (1,0) [0|255] "" Vector__XXX
 SG_ Led0049_value : 384|8@1+ (1,0) [0|255] "" Vector__XXX
 SG_ Led0048_value : 376|8@1+ (1,0) [0|255] "" Vector__XXX
 SG_ Led0047_value : 368|8@1+ (1,0) [0|255] "" Vector__XXX
 SG_ Led0046_value : 360|8@1+ (1,0) [0|255] "" Vector__XXX
 SG_ Led0045_value : 352|8@1+ (1,0) [0|255] "" Vector__XXX
 SG_ Led0044_value : 344|8@1+ (1,0) [0|255] "" Vector__XXX
 SG_ Led0043_value : 336|8@1+ (1,0) [0|255] "" Vector__XXX
 SG_ Led0042_value : 328|8@1+ (1,0) [0|255] "" Vector__XXX
 SG_ Led0041_value : 320|8@1+ (1,0) [0|255] "" Vector__XXX
 SG_ Led0040_value : 312|8@1+ (1,0) [0|255] "" Vector__XXX
 SG_ Led0039_value : 304|8@1+ (1,0) [0|255] "" Vector__XXX
 SG_ Led0038_value : 296|8@1+ (1,0) [0|255] "" Vector__XXX
 SG_ Led0037_value : 288|8@1+ (1,0) [0|255] "" Vector__XXX
 SG_ Led0036_value : 280|8@1+ (1,0) [0|255] "" Vector__XXX
 SG_ Led0035_value : 272|8@1+ (1,0) [0|255] "" Vector__XXX
 SG_ Led0034_value : 264|8@1+ (1,0) [0|255] "" Vector__XXX
 SG_ Led0033_value : 256|8@1+ (1,0) [0|255] "" Vector__XXX
 SG_ Led0032_value : 248|8@1+ (1,0) [0|255] "" Vector__XXX
 SG_ Led0031_value : 240|8@1+ (1,0) [0|255] "" Vector__XXX
 SG_ Led0030_value : 232|8@1+ (1,0) [0|255] "" Vector__XXX
 SG_ Led0029_value : 224|8@1+ (1,0) [0|255] "" Vector__XXX
 SG_ Led0028_value : 216|8@1+ (1,0) [0|255] "" Vector__XXX
 SG_ Led0027_value : 208|8@1+ (1,0) [0|255] "" Vector__XXX
 SG_ Led0026_value : 200|8@1+ (1,0) [0|255] "" Vector__XXX
 SG_ Led0025_value : 192|8@1+ (1,0) [0|255] "" Vector__XXX
 SG_ Led0024_value : 184|8@1+ (1,0) [0|255] "" Vector__XXX
 SG_ Led0023_value : 176|8@1+ (1,0) [0|255] "" Vector__XXX
 SG_ Led0022_value : 168|8@1+ (1,0) [0|255] "" Vector__XXX
 SG_ Led0021_value : 160|8@1+ (1,0) [0|255] "" Vector__XXX
 SG_ Led0020_value : 152|8@1+ (1,0) [0|255] "" Vector__XXX
 SG_ Led0019_value : 144|8@1+ (1,0) [0|255] "" Vector__XXX
 SG_ Led0018_value : 136|8@1+ (1,0) [0|255] "" Vector__XXX
 SG_ Led0017_value : 128|8@1+ (1,0) [0|255] "" Vector__XXX
 SG_ Led0016_value : 120|8@1+ (1,0) [0|255] "" Vector__XXX
 SG_ Led0015_value : 112|8@1+ (1,0) [0|255] "" Vector__XXX
 SG_ Led0014_value : 104|8@1+ (1,0) [0|255] "" Vector__XXX
 SG_ Led0013_value : 96|8@1+ (1,0) [0|255] "" Vector__XXX
 SG_ Led0012_value : 88|8@1+ (1,0) [0|255] "" Vector__XXX
 SG_ Led0011_value : 80|8@1+ (1,0) [0|255] "" Vector__XXX
 SG_ Led0010_value : 72|8@1+ (1,0) [0|255] "" Vector__XXX
 SG_ Led0009_value : 64|8@1+ (1,0) [0|255] "" Vector__XXX
 SG_ Led0008_value : 56|8@1+ (1,0) [0|255] "" Vector__XXX
 SG_ Led0007_value : 48|8@1+ (1,0) [0|255] "" Vector__XXX
 SG_ Led0006_value : 40|8@1+ (1,0) [0|255] "" Vector__XXX
 SG_ Led0005_value : 32|8@1+ (1,0) [0|255] "" Vector__XXX
 SG_ Led0004_value : 24|8@1+ (1,0) [0|255] "" Vector__XXX
 SG_ Led0003_value : 16|8@1+ (1,0) [0|255] "" Vector__XXX
 SG_ Led0002_value : 8|8@1+ (1,0) [0|255] "" Vector__XXX
 SG_ Led0001_value : 0|8@1+ (1,0) [0|255] "" Vector__XXX

BO_ 1028 ISC_Ctrl_LED_B_04: 64 ISC
 SG_ Led0064_value : 504|8@1+ (1,0) [0|255] "" Vector__XXX
 SG_ Led0063_value : 496|8@1+ (1,0) [0|255] "" Vector__XXX
 SG_ Led0062_value : 488|8@1+ (1,0) [0|255] "" Vector__XXX
 SG_ Led0061_value : 480|8@1+ (1,0) [0|255] "" Vector__XXX
 SG_ Led0060_value : 472|8@1+ (1,0) [0|255] "" Vector__XXX
 SG_ Led0059_value : 464|8@1+ (1,0) [0|255] "" Vector__XXX
 SG_ Led0058_value : 456|8@1+ (1,0) [0|255] "" Vector__XXX
 SG_ Led0057_value : 448|8@1+ (1,0) [0|255] "" Vector__XXX
 SG_ Led0056_value : 440|8@1+ (1,0) [0|255] "" Vector__XXX
 SG_ Led0055_value : 432|8@1+ (1,0) [0|255] "" Vector__XXX
 SG_ Led0054_value : 424|8@1+ (1,0) [0|255] "" Vector__XXX
 SG_ Led0053_value : 416|8@1+ (1,0) [0|255] "" Vector__XXX
 SG_ Led0052_value : 408|8@1+ (1,0) [0|255] "" Vector__XXX
 SG_ Led0051_value : 400|8@1+ (1,0) [0|255] "" Vector__XXX
 SG_ Led0050_value : 392|8@1+ (1,0) [0|255] "" Vector__XXX
 SG_ Led0049_value : 384|8@1+ (1,0) [0|255] "" Vector__XXX
 SG_ Led0048_value : 376|8@1+ (1,0) [0|255] "" Vector__XXX
 SG_ Led0047_value : 368|8@1+ (1,0) [0|255] "" Vector__XXX
 SG_ Led0046_value : 360|8@1+ (1,0) [0|255] "" Vector__XXX
 SG_ Led0045_value : 352|8@1+ (1,0) [0|255] "" Vector__XXX
 SG_ Led0044_value : 344|8@1+ (1,0) [0|255] "" Vector__XXX
 SG_ Led0043_value : 336|8@1+ (1,0) [0|255] "" Vector__XXX
 SG_ Led0042_value : 328|8@1+ (1,0) [0|255] "" Vector__XXX
 SG_ Led0041_value : 320|8@1+ (1,0) [0|255] "" Vector__XXX
 SG_ Led0040_value : 312|8@1+ (1,0) [0|255] "" Vector__XXX
 SG_ Led0039_value : 304|8@1+ (1,0) [0|255] "" Vector__XXX
 SG_ Led0038_value : 296|8@1+ (1,0) [0|255] "" Vector__XXX
 SG_ Led0037_value : 288|8@1+ (1,0) [0|255] "" Vector__XXX
 SG_ Led0036_value : 280|8@1+ (1,0) [0|255] "" Vector__XXX
 SG_ Led0035_value : 272|8@1+ (1,0) [0|255] "" Vector__XXX
 SG_ Led0034_value : 264|8@1+ (1,0) [0|255] "" Vector__XXX
 SG_ Led0033_value : 256|8@1+ (1,0) [0|255] "" Vector__XXX
 SG_ Led0032_value : 248|8@1+ (1,0) [0|255] "" Vector__XXX
 SG_ Led0031_value : 240|8@1+ (1,0) [0|255] "" Vector__XXX
 SG_ Led0030_value : 232|8@1+ (1,0) [0|255] "" Vector__XXX
 SG_ Led0029_value : 224|8@1+ (1,0) [0|255] "" Vector__XXX
 SG_ Led0028_value : 216|8@1+ (1,0) [0|255] "" Vector__XXX
 SG_ Led0027_value : 208|8@1+ (1,0) [0|255] "" Vector__XXX
 SG_ Led0026_value : 200|8@1+ (1,0) [0|255] "" Vector__XXX
 SG_ Led0025_value : 192|8@1+ (1,0) [0|255] "" Vector__XXX
 SG_ Led0024_value : 184|8@1+ (1,0) [0|255] "" Vector__XXX
 SG_ Led0023_value : 176|8@1+ (1,0) [0|255] "" Vector__XXX
 SG_ Led0022_value : 168|8@1+ (1,0) [0|255] "" Vector__XXX
 SG_ Led0021_value : 160|8@1+ (1,0) [0|255] "" Vector__XXX
 SG_ Led0020_value : 152|8@1+ (1,0) [0|255] "" Vector__XXX
 SG_ Led0019_value : 144|8@1+ (1,0) [0|255] "" Vector__XXX
 SG_ Led0018_value : 136|8@1+ (1,0) [0|255] "" Vector__XXX
 SG_ Led0017_value : 128|8@1+ (1,0) [0|255] "" Vector__XXX
 SG_ Led0016_value : 120|8@1+ (1,0) [0|255] "" Vector__XXX
 SG_ Led0015_value : 112|8@1+ (1,0) [0|255] "" Vector__XXX
 SG_ Led0014_value : 104|8@1+ (1,0) [0|255] "" Vector__XXX
 SG_ Led0013_value : 96|8@1+ (1,0) [0|255] "" Vector__XXX
 SG_ Led0012_value : 88|8@1+ (1,0) [0|255] "" Vector__XXX
 SG_ Led0011_value : 80|8@1+ (1,0) [0|255] "" Vector__XXX
 SG_ Led0010_value : 72|8@1+ (1,0) [0|255] "" Vector__XXX
 SG_ Led0009_value : 64|8@1+ (1,0) [0|255] "" Vector__XXX
 SG_ Led0008_value : 56|8@1+ (1,0) [0|255] "" Vector__XXX
 SG_ Led0007_value : 48|8@1+ (1,0) [0|255] "" Vector__XXX
 SG_ Led0006_value : 40|8@1+ (1,0) [0|255] "" Vector__XXX
 SG_ Led0005_value : 32|8@1+ (1,0) [0|255] "" Vector__XXX
 SG_ Led0004_value : 24|8@1+ (1,0) [0|255] "" Vector__XXX
 SG_ Led0003_value : 16|8@1+ (1,0) [0|255] "" Vector__XXX
 SG_ Led0002_value : 8|8@1+ (1,0) [0|255] "" Vector__XXX
 SG_ Led0001_value : 0|8@1+ (1,0) [0|255] "" Vector__XXX

BO_ 1027 ISC_Ctrl_LED_B_03: 64 ISC
 SG_ Led0064_value : 504|8@1+ (1,0) [0|255] "" Vector__XXX
 SG_ Led0063_value : 496|8@1+ (1,0) [0|255] "" Vector__XXX
 SG_ Led0062_value : 488|8@1+ (1,0) [0|255] "" Vector__XXX
 SG_ Led0061_value : 480|8@1+ (1,0) [0|255] "" Vector__XXX
 SG_ Led0060_value : 472|8@1+ (1,0) [0|255] "" Vector__XXX
 SG_ Led0059_value : 464|8@1+ (1,0) [0|255] "" Vector__XXX
 SG_ Led0058_value : 456|8@1+ (1,0) [0|255] "" Vector__XXX
 SG_ Led0057_value : 448|8@1+ (1,0) [0|255] "" Vector__XXX
 SG_ Led0056_value : 440|8@1+ (1,0) [0|255] "" Vector__XXX
 SG_ Led0055_value : 432|8@1+ (1,0) [0|255] "" Vector__XXX
 SG_ Led0054_value : 424|8@1+ (1,0) [0|255] "" Vector__XXX
 SG_ Led0053_value : 416|8@1+ (1,0) [0|255] "" Vector__XXX
 SG_ Led0052_value : 408|8@1+ (1,0) [0|255] "" Vector__XXX
 SG_ Led0051_value : 400|8@1+ (1,0) [0|255] "" Vector__XXX
 SG_ Led0050_value : 392|8@1+ (1,0) [0|255] "" Vector__XXX
 SG_ Led0049_value : 384|8@1+ (1,0) [0|255] "" Vector__XXX
 SG_ Led0048_value : 376|8@1+ (1,0) [0|255] "" Vector__XXX
 SG_ Led0047_value : 368|8@1+ (1,0) [0|255] "" Vector__XXX
 SG_ Led0046_value : 360|8@1+ (1,0) [0|255] "" Vector__XXX
 SG_ Led0045_value : 352|8@1+ (1,0) [0|255] "" Vector__XXX
 SG_ Led0044_value : 344|8@1+ (1,0) [0|255] "" Vector__XXX
 SG_ Led0043_value : 336|8@1+ (1,0) [0|255] "" Vector__XXX
 SG_ Led0042_value : 328|8@1+ (1,0) [0|255] "" Vector__XXX
 SG_ Led0041_value : 320|8@1+ (1,0) [0|255] "" Vector__XXX
 SG_ Led0040_value : 312|8@1+ (1,0) [0|255] "" Vector__XXX
 SG_ Led0039_value : 304|8@1+ (1,0) [0|255] "" Vector__XXX
 SG_ Led0038_value : 296|8@1+ (1,0) [0|255] "" Vector__XXX
 SG_ Led0037_value : 288|8@1+ (1,0) [0|255] "" Vector__XXX
 SG_ Led0036_value : 280|8@1+ (1,0) [0|255] "" Vector__XXX
 SG_ Led0035_value : 272|8@1+ (1,0) [0|255] "" Vector__XXX
 SG_ Led0034_value : 264|8@1+ (1,0) [0|255] "" Vector__XXX
 SG_ Led0033_value : 256|8@1+ (1,0) [0|255] "" Vector__XXX
 SG_ Led0032_value : 248|8@1+ (1,0) [0|255] "" Vector__XXX
 SG_ Led0031_value : 240|8@1+ (1,0) [0|255] "" Vector__XXX
 SG_ Led0030_value : 232|8@1+ (1,0) [0|255] "" Vector__XXX
 SG_ Led0029_value : 224|8@1+ (1,0) [0|255] "" Vector__XXX
 SG_ Led0028_value : 216|8@1+ (1,0) [0|255] "" Vector__XXX
 SG_ Led0027_value : 208|8@1+ (1,0) [0|255] "" Vector__XXX
 SG_ Led0026_value : 200|8@1+ (1,0) [0|255] "" Vector__XXX
 SG_ Led0025_value : 192|8@1+ (1,0) [0|255] "" Vector__XXX
 SG_ Led0024_value : 184|8@1+ (1,0) [0|255] "" Vector__XXX
 SG_ Led0023_value : 176|8@1+ (1,0) [0|255] "" Vector__XXX
 SG_ Led0022_value : 168|8@1+ (1,0) [0|255] "" Vector__XXX
 SG_ Led0021_value : 160|8@1+ (1,0) [0|255] "" Vector__XXX
 SG_ Led0020_value : 152|8@1+ (1,0) [0|255] "" Vector__XXX
 SG_ Led0019_value : 144|8@1+ (1,0) [0|255] "" Vector__XXX
 SG_ Led0018_value : 136|8@1+ (1,0) [0|255] "" Vector__XXX
 SG_ Led0017_value : 128|8@1+ (1,0) [0|255] "" Vector__XXX
 SG_ Led0016_value : 120|8@1+ (1,0) [0|255] "" Vector__XXX
 SG_ Led0015_value : 112|8@1+ (1,0) [0|255] "" Vector__XXX
 SG_ Led0014_value : 104|8@1+ (1,0) [0|255] "" Vector__XXX
 SG_ Led0013_value : 96|8@1+ (1,0) [0|255] "" Vector__XXX
 SG_ Led0012_value : 88|8@1+ (1,0) [0|255] "" Vector__XXX
 SG_ Led0011_value : 80|8@1+ (1,0) [0|255] "" Vector__XXX
 SG_ Led0010_value : 72|8@1+ (1,0) [0|255] "" Vector__XXX
 SG_ Led0009_value : 64|8@1+ (1,0) [0|255] "" Vector__XXX
 SG_ Led0008_value : 56|8@1+ (1,0) [0|255] "" Vector__XXX
 SG_ Led0007_value : 48|8@1+ (1,0) [0|255] "" Vector__XXX
 SG_ Led0006_value : 40|8@1+ (1,0) [0|255] "" Vector__XXX
 SG_ Led0005_value : 32|8@1+ (1,0) [0|255] "" Vector__XXX
 SG_ Led0004_value : 24|8@1+ (1,0) [0|255] "" Vector__XXX
 SG_ Led0003_value : 16|8@1+ (1,0) [0|255] "" Vector__XXX
 SG_ Led0002_value : 8|8@1+ (1,0) [0|255] "" Vector__XXX
 SG_ Led0001_value : 0|8@1+ (1,0) [0|255] "" Vector__XXX

BO_ 1026 ISC_Ctrl_LED_B_02: 64 ISC
 SG_ Led0064_value : 504|8@1+ (1,0) [0|255] "" Vector__XXX
 SG_ Led0063_value : 496|8@1+ (1,0) [0|255] "" Vector__XXX
 SG_ Led0062_value : 488|8@1+ (1,0) [0|255] "" Vector__XXX
 SG_ Led0061_value : 480|8@1+ (1,0) [0|255] "" Vector__XXX
 SG_ Led0060_value : 472|8@1+ (1,0) [0|255] "" Vector__XXX
 SG_ Led0059_value : 464|8@1+ (1,0) [0|255] "" Vector__XXX
 SG_ Led0058_value : 456|8@1+ (1,0) [0|255] "" Vector__XXX
 SG_ Led0057_value : 448|8@1+ (1,0) [0|255] "" Vector__XXX
 SG_ Led0056_value : 440|8@1+ (1,0) [0|255] "" Vector__XXX
 SG_ Led0055_value : 432|8@1+ (1,0) [0|255] "" Vector__XXX
 SG_ Led0054_value : 424|8@1+ (1,0) [0|255] "" Vector__XXX
 SG_ Led0053_value : 416|8@1+ (1,0) [0|255] "" Vector__XXX
 SG_ Led0052_value : 408|8@1+ (1,0) [0|255] "" Vector__XXX
 SG_ Led0051_value : 400|8@1+ (1,0) [0|255] "" Vector__XXX
 SG_ Led0050_value : 392|8@1+ (1,0) [0|255] "" Vector__XXX
 SG_ Led0049_value : 384|8@1+ (1,0) [0|255] "" Vector__XXX
 SG_ Led0048_value : 376|8@1+ (1,0) [0|255] "" Vector__XXX
 SG_ Led0047_value : 368|8@1+ (1,0) [0|255] "" Vector__XXX
 SG_ Led0046_value : 360|8@1+ (1,0) [0|255] "" Vector__XXX
 SG_ Led0045_value : 352|8@1+ (1,0) [0|255] "" Vector__XXX
 SG_ Led0044_value : 344|8@1+ (1,0) [0|255] "" Vector__XXX
 SG_ Led0043_value : 336|8@1+ (1,0) [0|255] "" Vector__XXX
 SG_ Led0042_value : 328|8@1+ (1,0) [0|255] "" Vector__XXX
 SG_ Led0041_value : 320|8@1+ (1,0) [0|255] "" Vector__XXX
 SG_ Led0040_value : 312|8@1+ (1,0) [0|255] "" Vector__XXX
 SG_ Led0039_value : 304|8@1+ (1,0) [0|255] "" Vector__XXX
 SG_ Led0038_value : 296|8@1+ (1,0) [0|255] "" Vector__XXX
 SG_ Led0037_value : 288|8@1+ (1,0) [0|255] "" Vector__XXX
 SG_ Led0036_value : 280|8@1+ (1,0) [0|255] "" Vector__XXX
 SG_ Led0035_value : 272|8@1+ (1,0) [0|255] "" Vector__XXX
 SG_ Led0034_value : 264|8@1+ (1,0) [0|255] "" Vector__XXX
 SG_ Led0033_value : 256|8@1+ (1,0) [0|255] "" Vector__XXX
 SG_ Led0032_value : 248|8@1+ (1,0) [0|255] "" Vector__XXX
 SG_ Led0031_value : 240|8@1+ (1,0) [0|255] "" Vector__XXX
 SG_ Led0030_value : 232|8@1+ (1,0) [0|255] "" Vector__XXX
 SG_ Led0029_value : 224|8@1+ (1,0) [0|255] "" Vector__XXX
 SG_ Led0028_value : 216|8@1+ (1,0) [0|255] "" Vector__XXX
 SG_ Led0027_value : 208|8@1+ (1,0) [0|255] "" Vector__XXX
 SG_ Led0026_value : 200|8@1+ (1,0) [0|255] "" Vector__XXX
 SG_ Led0025_value : 192|8@1+ (1,0) [0|255] "" Vector__XXX
 SG_ Led0024_value : 184|8@1+ (1,0) [0|255] "" Vector__XXX
 SG_ Led0023_value : 176|8@1+ (1,0) [0|255] "" Vector__XXX
 SG_ Led0022_value : 168|8@1+ (1,0) [0|255] "" Vector__XXX
 SG_ Led0021_value : 160|8@1+ (1,0) [0|255] "" Vector__XXX
 SG_ Led0020_value : 152|8@1+ (1,0) [0|255] "" Vector__XXX
 SG_ Led0019_value : 144|8@1+ (1,0) [0|255] "" Vector__XXX
 SG_ Led0018_value : 136|8@1+ (1,0) [0|255] "" Vector__XXX
 SG_ Led0017_value : 128|8@1+ (1,0) [0|255] "" Vector__XXX
 SG_ Led0016_value : 120|8@1+ (1,0) [0|255] "" Vector__XXX
 SG_ Led0015_value : 112|8@1+ (1,0) [0|255] "" Vector__XXX
 SG_ Led0014_value : 104|8@1+ (1,0) [0|255] "" Vector__XXX
 SG_ Led0013_value : 96|8@1+ (1,0) [0|255] "" Vector__XXX
 SG_ Led0012_value : 88|8@1+ (1,0) [0|255] "" Vector__XXX
 SG_ Led0011_value : 80|8@1+ (1,0) [0|255] "" Vector__XXX
 SG_ Led0010_value : 72|8@1+ (1,0) [0|255] "" Vector__XXX
 SG_ Led0009_value : 64|8@1+ (1,0) [0|255] "" Vector__XXX
 SG_ Led0008_value : 56|8@1+ (1,0) [0|255] "" Vector__XXX
 SG_ Led0007_value : 48|8@1+ (1,0) [0|255] "" Vector__XXX
 SG_ Led0006_value : 40|8@1+ (1,0) [0|255] "" Vector__XXX
 SG_ Led0005_value : 32|8@1+ (1,0) [0|255] "" Vector__XXX
 SG_ Led0004_value : 24|8@1+ (1,0) [0|255] "" Vector__XXX
 SG_ Led0003_value : 16|8@1+ (1,0) [0|255] "" Vector__XXX
 SG_ Led0002_value : 8|8@1+ (1,0) [0|255] "" Vector__XXX
 SG_ Led0001_value : 0|8@1+ (1,0) [0|255] "" Vector__XXX

BO_ 1025 ISC_Ctrl_LED_B_01: 64 ISC
 SG_ Led0064_value : 504|8@1+ (1,0) [0|255] "" Vector__XXX
 SG_ Led0063_value : 496|8@1+ (1,0) [0|255] "" Vector__XXX
 SG_ Led0062_value : 488|8@1+ (1,0) [0|255] "" Vector__XXX
 SG_ Led0061_value : 480|8@1+ (1,0) [0|255] "" Vector__XXX
 SG_ Led0060_value : 472|8@1+ (1,0) [0|255] "" Vector__XXX
 SG_ Led0059_value : 464|8@1+ (1,0) [0|255] "" Vector__XXX
 SG_ Led0058_value : 456|8@1+ (1,0) [0|255] "" Vector__XXX
 SG_ Led0057_value : 448|8@1+ (1,0) [0|255] "" Vector__XXX
 SG_ Led0056_value : 440|8@1+ (1,0) [0|255] "" Vector__XXX
 SG_ Led0055_value : 432|8@1+ (1,0) [0|255] "" Vector__XXX
 SG_ Led0054_value : 424|8@1+ (1,0) [0|255] "" Vector__XXX
 SG_ Led0053_value : 416|8@1+ (1,0) [0|255] "" Vector__XXX
 SG_ Led0052_value : 408|8@1+ (1,0) [0|255] "" Vector__XXX
 SG_ Led0051_value : 400|8@1+ (1,0) [0|255] "" Vector__XXX
 SG_ Led0050_value : 392|8@1+ (1,0) [0|255] "" Vector__XXX
 SG_ Led0049_value : 384|8@1+ (1,0) [0|255] "" Vector__XXX
 SG_ Led0048_value : 376|8@1+ (1,0) [0|255] "" Vector__XXX
 SG_ Led0047_value : 368|8@1+ (1,0) [0|255] "" Vector__XXX
 SG_ Led0046_value : 360|8@1+ (1,0) [0|255] "" Vector__XXX
 SG_ Led0045_value : 352|8@1+ (1,0) [0|255] "" Vector__XXX
 SG_ Led0044_value : 344|8@1+ (1,0) [0|255] "" Vector__XXX
 SG_ Led0043_value : 336|8@1+ (1,0) [0|255] "" Vector__XXX
 SG_ Led0042_value : 328|8@1+ (1,0) [0|255] "" Vector__XXX
 SG_ Led0041_value : 320|8@1+ (1,0) [0|255] "" Vector__XXX
 SG_ Led0040_value : 312|8@1+ (1,0) [0|255] "" Vector__XXX
 SG_ Led0039_value : 304|8@1+ (1,0) [0|255] "" Vector__XXX
 SG_ Led0038_value : 296|8@1+ (1,0) [0|255] "" Vector__XXX
 SG_ Led0037_value : 288|8@1+ (1,0) [0|255] "" Vector__XXX
 SG_ Led0036_value : 280|8@1+ (1,0) [0|255] "" Vector__XXX
 SG_ Led0035_value : 272|8@1+ (1,0) [0|255] "" Vector__XXX
 SG_ Led0034_value : 264|8@1+ (1,0) [0|255] "" Vector__XXX
 SG_ Led0033_value : 256|8@1+ (1,0) [0|255] "" Vector__XXX
 SG_ Led0032_value : 248|8@1+ (1,0) [0|255] "" Vector__XXX
 SG_ Led0031_value : 240|8@1+ (1,0) [0|255] "" Vector__XXX
 SG_ Led0030_value : 232|8@1+ (1,0) [0|255] "" Vector__XXX
 SG_ Led0029_value : 224|8@1+ (1,0) [0|255] "" Vector__XXX
 SG_ Led0028_value : 216|8@1+ (1,0) [0|255] "" Vector__XXX
 SG_ Led0027_value : 208|8@1+ (1,0) [0|255] "" Vector__XXX
 SG_ Led0026_value : 200|8@1+ (1,0) [0|255] "" Vector__XXX
 SG_ Led0025_value : 192|8@1+ (1,0) [0|255] "" Vector__XXX
 SG_ Led0024_value : 184|8@1+ (1,0) [0|255] "" Vector__XXX
 SG_ Led0023_value : 176|8@1+ (1,0) [0|255] "" Vector__XXX
 SG_ Led0022_value : 168|8@1+ (1,0) [0|255] "" Vector__XXX
 SG_ Led0021_value : 160|8@1+ (1,0) [0|255] "" Vector__XXX
 SG_ Led0020_value : 152|8@1+ (1,0) [0|255] "" Vector__XXX
 SG_ Led0019_value : 144|8@1+ (1,0) [0|255] "" Vector__XXX
 SG_ Led0018_value : 136|8@1+ (1,0) [0|255] "" Vector__XXX
 SG_ Led0017_value : 128|8@1+ (1,0) [0|255] "" Vector__XXX
 SG_ Led0016_value : 120|8@1+ (1,0) [0|255] "" Vector__XXX
 SG_ Led0015_value : 112|8@1+ (1,0) [0|255] "" Vector__XXX
 SG_ Led0014_value : 104|8@1+ (1,0) [0|255] "" Vector__XXX
 SG_ Led0013_value : 96|8@1+ (1,0) [0|255] "" Vector__XXX
 SG_ Led0012_value : 88|8@1+ (1,0) [0|255] "" Vector__XXX
 SG_ Led0011_value : 80|8@1+ (1,0) [0|255] "" Vector__XXX
 SG_ Led0010_value : 72|8@1+ (1,0) [0|255] "" Vector__XXX
 SG_ Led0009_value : 64|8@1+ (1,0) [0|255] "" Vector__XXX
 SG_ Led0008_value : 56|8@1+ (1,0) [0|255] "" Vector__XXX
 SG_ Led0007_value : 48|8@1+ (1,0) [0|255] "" Vector__XXX
 SG_ Led0006_value : 40|8@1+ (1,0) [0|255] "" Vector__XXX
 SG_ Led0005_value : 32|8@1+ (1,0) [0|255] "" Vector__XXX
 SG_ Led0004_value : 24|8@1+ (1,0) [0|255] "" Vector__XXX
 SG_ Led0003_value : 16|8@1+ (1,0) [0|255] "" Vector__XXX
 SG_ Led0002_value : 8|8@1+ (1,0) [0|255] "" Vector__XXX
 SG_ Led0001_value : 0|8@1+ (1,0) [0|255] "" Vector__XXX

BO_ 773 ISC_Ctrl_Left_LED_A_05: 64 ISC
 SG_ Led0043_value : 336|8@1+ (1,0) [0|255] "" Vector__XXX
 SG_ Led0042_value : 328|8@1+ (1,0) [0|255] "" Vector__XXX
 SG_ Led0041_value : 320|8@1+ (1,0) [0|255] "" Vector__XXX
 SG_ Led0040_value : 312|8@1+ (1,0) [0|255] "" Vector__XXX
 SG_ Led0039_value : 304|8@1+ (1,0) [0|255] "" Vector__XXX
 SG_ Led0038_value : 296|8@1+ (1,0) [0|255] "" Vector__XXX
 SG_ Led0037_value : 288|8@1+ (1,0) [0|255] "" Vector__XXX
 SG_ Led0036_value : 280|8@1+ (1,0) [0|255] "" Vector__XXX
 SG_ Led0035_value : 272|8@1+ (1,0) [0|255] "" Vector__XXX
 SG_ Led0034_value : 264|8@1+ (1,0) [0|255] "" Vector__XXX
 SG_ Led0033_value : 256|8@1+ (1,0) [0|255] "" Vector__XXX
 SG_ Led0032_value : 248|8@1+ (1,0) [0|255] "" Vector__XXX
 SG_ Led0031_value : 240|8@1+ (1,0) [0|255] "" Vector__XXX
 SG_ Led0030_value : 232|8@1+ (1,0) [0|255] "" Vector__XXX
 SG_ Led0029_value : 224|8@1+ (1,0) [0|255] "" Vector__XXX
 SG_ Led0028_value : 216|8@1+ (1,0) [0|255] "" Vector__XXX
 SG_ Led0027_value : 208|8@1+ (1,0) [0|255] "" Vector__XXX
 SG_ Led0026_value : 200|8@1+ (1,0) [0|255] "" Vector__XXX
 SG_ Led0025_value : 192|8@1+ (1,0) [0|255] "" Vector__XXX
 SG_ Led0024_value : 184|8@1+ (1,0) [0|255] "" Vector__XXX
 SG_ Led0023_value : 176|8@1+ (1,0) [0|255] "" Vector__XXX
 SG_ Led0022_value : 168|8@1+ (1,0) [0|255] "" Vector__XXX
 SG_ Led0021_value : 160|8@1+ (1,0) [0|255] "" Vector__XXX
 SG_ Led0020_value : 152|8@1+ (1,0) [0|255] "" Vector__XXX
 SG_ Led0019_value : 144|8@1+ (1,0) [0|255] "" Vector__XXX
 SG_ Led0018_value : 136|8@1+ (1,0) [0|255] "" Vector__XXX
 SG_ Led0017_value : 128|8@1+ (1,0) [0|255] "" Vector__XXX
 SG_ Led0016_value : 120|8@1+ (1,0) [0|255] "" Vector__XXX
 SG_ Led0015_value : 112|8@1+ (1,0) [0|255] "" Vector__XXX
 SG_ Led0014_value : 104|8@1+ (1,0) [0|255] "" Vector__XXX
 SG_ Led0013_value : 96|8@1+ (1,0) [0|255] "" Vector__XXX
 SG_ Led0012_value : 88|8@1+ (1,0) [0|255] "" Vector__XXX
 SG_ Led0011_value : 80|8@1+ (1,0) [0|255] "" Vector__XXX
 SG_ Led0010_value : 72|8@1+ (1,0) [0|255] "" Vector__XXX
 SG_ Led0009_value : 64|8@1+ (1,0) [0|255] "" Vector__XXX
 SG_ Led0008_value : 56|8@1+ (1,0) [0|255] "" Vector__XXX
 SG_ Led0007_value : 48|8@1+ (1,0) [0|255] "" Vector__XXX
 SG_ Led0006_value : 40|8@1+ (1,0) [0|255] "" Vector__XXX
 SG_ Led0005_value : 32|8@1+ (1,0) [0|255] "" Vector__XXX
 SG_ Led0004_value : 24|8@1+ (1,0) [0|255] "" Vector__XXX
 SG_ Led0003_value : 16|8@1+ (1,0) [0|255] "" Vector__XXX
 SG_ Led0002_value : 8|8@1+ (1,0) [0|255] "" Vector__XXX
 SG_ Led0001_value : 0|8@1+ (1,0) [0|255] "" Vector__XXX

BO_ 772 ISC_Ctrl_Left_LED_A_04: 64 ISC
 SG_ Led0064_value : 504|8@1+ (1,0) [0|255] "" Vector__XXX
 SG_ Led0063_value : 496|8@1+ (1,0) [0|255] "" Vector__XXX
 SG_ Led0062_value : 488|8@1+ (1,0) [0|255] "" Vector__XXX
 SG_ Led0061_value : 480|8@1+ (1,0) [0|255] "" Vector__XXX
 SG_ Led0060_value : 472|8@1+ (1,0) [0|255] "" Vector__XXX
 SG_ Led0059_value : 464|8@1+ (1,0) [0|255] "" Vector__XXX
 SG_ Led0058_value : 456|8@1+ (1,0) [0|255] "" Vector__XXX
 SG_ Led0057_value : 448|8@1+ (1,0) [0|255] "" Vector__XXX
 SG_ Led0056_value : 440|8@1+ (1,0) [0|255] "" Vector__XXX
 SG_ Led0055_value : 432|8@1+ (1,0) [0|255] "" Vector__XXX
 SG_ Led0054_value : 424|8@1+ (1,0) [0|255] "" Vector__XXX
 SG_ Led0053_value : 416|8@1+ (1,0) [0|255] "" Vector__XXX
 SG_ Led0052_value : 408|8@1+ (1,0) [0|255] "" Vector__XXX
 SG_ Led0051_value : 400|8@1+ (1,0) [0|255] "" Vector__XXX
 SG_ Led0050_value : 392|8@1+ (1,0) [0|255] "" Vector__XXX
 SG_ Led0049_value : 384|8@1+ (1,0) [0|255] "" Vector__XXX
 SG_ Led0048_value : 376|8@1+ (1,0) [0|255] "" Vector__XXX
 SG_ Led0047_value : 368|8@1+ (1,0) [0|255] "" Vector__XXX
 SG_ Led0046_value : 360|8@1+ (1,0) [0|255] "" Vector__XXX
 SG_ Led0045_value : 352|8@1+ (1,0) [0|255] "" Vector__XXX
 SG_ Led0044_value : 344|8@1+ (1,0) [0|255] "" Vector__XXX
 SG_ Led0043_value : 336|8@1+ (1,0) [0|255] "" Vector__XXX
 SG_ Led0042_value : 328|8@1+ (1,0) [0|255] "" Vector__XXX
 SG_ Led0041_value : 320|8@1+ (1,0) [0|255] "" Vector__XXX
 SG_ Led0040_value : 312|8@1+ (1,0) [0|255] "" Vector__XXX
 SG_ Led0039_value : 304|8@1+ (1,0) [0|255] "" Vector__XXX
 SG_ Led0038_value : 296|8@1+ (1,0) [0|255] "" Vector__XXX
 SG_ Led0037_value : 288|8@1+ (1,0) [0|255] "" Vector__XXX
 SG_ Led0036_value : 280|8@1+ (1,0) [0|255] "" Vector__XXX
 SG_ Led0035_value : 272|8@1+ (1,0) [0|255] "" Vector__XXX
 SG_ Led0034_value : 264|8@1+ (1,0) [0|255] "" Vector__XXX
 SG_ Led0033_value : 256|8@1+ (1,0) [0|255] "" Vector__XXX
 SG_ Led0032_value : 248|8@1+ (1,0) [0|255] "" Vector__XXX
 SG_ Led0031_value : 240|8@1+ (1,0) [0|255] "" Vector__XXX
 SG_ Led0030_value : 232|8@1+ (1,0) [0|255] "" Vector__XXX
 SG_ Led0029_value : 224|8@1+ (1,0) [0|255] "" Vector__XXX
 SG_ Led0028_value : 216|8@1+ (1,0) [0|255] "" Vector__XXX
 SG_ Led0027_value : 208|8@1+ (1,0) [0|255] "" Vector__XXX
 SG_ Led0026_value : 200|8@1+ (1,0) [0|255] "" Vector__XXX
 SG_ Led0025_value : 192|8@1+ (1,0) [0|255] "" Vector__XXX
 SG_ Led0024_value : 184|8@1+ (1,0) [0|255] "" Vector__XXX
 SG_ Led0023_value : 176|8@1+ (1,0) [0|255] "" Vector__XXX
 SG_ Led0022_value : 168|8@1+ (1,0) [0|255] "" Vector__XXX
 SG_ Led0021_value : 160|8@1+ (1,0) [0|255] "" Vector__XXX
 SG_ Led0020_value : 152|8@1+ (1,0) [0|255] "" Vector__XXX
 SG_ Led0019_value : 144|8@1+ (1,0) [0|255] "" Vector__XXX
 SG_ Led0018_value : 136|8@1+ (1,0) [0|255] "" Vector__XXX
 SG_ Led0017_value : 128|8@1+ (1,0) [0|255] "" Vector__XXX
 SG_ Led0016_value : 120|8@1+ (1,0) [0|255] "" Vector__XXX
 SG_ Led0015_value : 112|8@1+ (1,0) [0|255] "" Vector__XXX
 SG_ Led0014_value : 104|8@1+ (1,0) [0|255] "" Vector__XXX
 SG_ Led0013_value : 96|8@1+ (1,0) [0|255] "" Vector__XXX
 SG_ Led0012_value : 88|8@1+ (1,0) [0|255] "" Vector__XXX
 SG_ Led0011_value : 80|8@1+ (1,0) [0|255] "" Vector__XXX
 SG_ Led0010_value : 72|8@1+ (1,0) [0|255] "" Vector__XXX
 SG_ Led0009_value : 64|8@1+ (1,0) [0|255] "" Vector__XXX
 SG_ Led0008_value : 56|8@1+ (1,0) [0|255] "" Vector__XXX
 SG_ Led0007_value : 48|8@1+ (1,0) [0|255] "" Vector__XXX
 SG_ Led0006_value : 40|8@1+ (1,0) [0|255] "" Vector__XXX
 SG_ Led0005_value : 32|8@1+ (1,0) [0|255] "" Vector__XXX
 SG_ Led0004_value : 24|8@1+ (1,0) [0|255] "" Vector__XXX
 SG_ Led0003_value : 16|8@1+ (1,0) [0|255] "" Vector__XXX
 SG_ Led0002_value : 8|8@1+ (1,0) [0|255] "" Vector__XXX
 SG_ Led0001_value : 0|8@1+ (1,0) [0|255] "" Vector__XXX

BO_ 771 ISC_Ctrl_Left_LED_A_03: 64 ISC
 SG_ Led0064_value : 504|8@1+ (1,0) [0|255] "" Vector__XXX
 SG_ Led0063_value : 496|8@1+ (1,0) [0|255] "" Vector__XXX
 SG_ Led0062_value : 488|8@1+ (1,0) [0|255] "" Vector__XXX
 SG_ Led0061_value : 480|8@1+ (1,0) [0|255] "" Vector__XXX
 SG_ Led0060_value : 472|8@1+ (1,0) [0|255] "" Vector__XXX
 SG_ Led0059_value : 464|8@1+ (1,0) [0|255] "" Vector__XXX
 SG_ Led0058_value : 456|8@1+ (1,0) [0|255] "" Vector__XXX
 SG_ Led0057_value : 448|8@1+ (1,0) [0|255] "" Vector__XXX
 SG_ Led0056_value : 440|8@1+ (1,0) [0|255] "" Vector__XXX
 SG_ Led0055_value : 432|8@1+ (1,0) [0|255] "" Vector__XXX
 SG_ Led0054_value : 424|8@1+ (1,0) [0|255] "" Vector__XXX
 SG_ Led0053_value : 416|8@1+ (1,0) [0|255] "" Vector__XXX
 SG_ Led0052_value : 408|8@1+ (1,0) [0|255] "" Vector__XXX
 SG_ Led0051_value : 400|8@1+ (1,0) [0|255] "" Vector__XXX
 SG_ Led0050_value : 392|8@1+ (1,0) [0|255] "" Vector__XXX
 SG_ Led0049_value : 384|8@1+ (1,0) [0|255] "" Vector__XXX
 SG_ Led0048_value : 376|8@1+ (1,0) [0|255] "" Vector__XXX
 SG_ Led0047_value : 368|8@1+ (1,0) [0|255] "" Vector__XXX
 SG_ Led0046_value : 360|8@1+ (1,0) [0|255] "" Vector__XXX
 SG_ Led0045_value : 352|8@1+ (1,0) [0|255] "" Vector__XXX
 SG_ Led0044_value : 344|8@1+ (1,0) [0|255] "" Vector__XXX
 SG_ Led0043_value : 336|8@1+ (1,0) [0|255] "" Vector__XXX
 SG_ Led0042_value : 328|8@1+ (1,0) [0|255] "" Vector__XXX
 SG_ Led0041_value : 320|8@1+ (1,0) [0|255] "" Vector__XXX
 SG_ Led0040_value : 312|8@1+ (1,0) [0|255] "" Vector__XXX
 SG_ Led0039_value : 304|8@1+ (1,0) [0|255] "" Vector__XXX
 SG_ Led0038_value : 296|8@1+ (1,0) [0|255] "" Vector__XXX
 SG_ Led0037_value : 288|8@1+ (1,0) [0|255] "" Vector__XXX
 SG_ Led0036_value : 280|8@1+ (1,0) [0|255] "" Vector__XXX
 SG_ Led0035_value : 272|8@1+ (1,0) [0|255] "" Vector__XXX
 SG_ Led0034_value : 264|8@1+ (1,0) [0|255] "" Vector__XXX
 SG_ Led0033_value : 256|8@1+ (1,0) [0|255] "" Vector__XXX
 SG_ Led0032_value : 248|8@1+ (1,0) [0|255] "" Vector__XXX
 SG_ Led0031_value : 240|8@1+ (1,0) [0|255] "" Vector__XXX
 SG_ Led0030_value : 232|8@1+ (1,0) [0|255] "" Vector__XXX
 SG_ Led0029_value : 224|8@1+ (1,0) [0|255] "" Vector__XXX
 SG_ Led0028_value : 216|8@1+ (1,0) [0|255] "" Vector__XXX
 SG_ Led0027_value : 208|8@1+ (1,0) [0|255] "" Vector__XXX
 SG_ Led0026_value : 200|8@1+ (1,0) [0|255] "" Vector__XXX
 SG_ Led0025_value : 192|8@1+ (1,0) [0|255] "" Vector__XXX
 SG_ Led0024_value : 184|8@1+ (1,0) [0|255] "" Vector__XXX
 SG_ Led0023_value : 176|8@1+ (1,0) [0|255] "" Vector__XXX
 SG_ Led0022_value : 168|8@1+ (1,0) [0|255] "" Vector__XXX
 SG_ Led0021_value : 160|8@1+ (1,0) [0|255] "" Vector__XXX
 SG_ Led0020_value : 152|8@1+ (1,0) [0|255] "" Vector__XXX
 SG_ Led0019_value : 144|8@1+ (1,0) [0|255] "" Vector__XXX
 SG_ Led0018_value : 136|8@1+ (1,0) [0|255] "" Vector__XXX
 SG_ Led0017_value : 128|8@1+ (1,0) [0|255] "" Vector__XXX
 SG_ Led0016_value : 120|8@1+ (1,0) [0|255] "" Vector__XXX
 SG_ Led0015_value : 112|8@1+ (1,0) [0|255] "" Vector__XXX
 SG_ Led0014_value : 104|8@1+ (1,0) [0|255] "" Vector__XXX
 SG_ Led0013_value : 96|8@1+ (1,0) [0|255] "" Vector__XXX
 SG_ Led0012_value : 88|8@1+ (1,0) [0|255] "" Vector__XXX
 SG_ Led0011_value : 80|8@1+ (1,0) [0|255] "" Vector__XXX
 SG_ Led0010_value : 72|8@1+ (1,0) [0|255] "" Vector__XXX
 SG_ Led0009_value : 64|8@1+ (1,0) [0|255] "" Vector__XXX
 SG_ Led0008_value : 56|8@1+ (1,0) [0|255] "" Vector__XXX
 SG_ Led0007_value : 48|8@1+ (1,0) [0|255] "" Vector__XXX
 SG_ Led0006_value : 40|8@1+ (1,0) [0|255] "" Vector__XXX
 SG_ Led0005_value : 32|8@1+ (1,0) [0|255] "" Vector__XXX
 SG_ Led0004_value : 24|8@1+ (1,0) [0|255] "" Vector__XXX
 SG_ Led0003_value : 16|8@1+ (1,0) [0|255] "" Vector__XXX
 SG_ Led0002_value : 8|8@1+ (1,0) [0|255] "" Vector__XXX
 SG_ Led0001_value : 0|8@1+ (1,0) [0|255] "" Vector__XXX

BO_ 770 ISC_Ctrl_Left_LED_A_02: 64 ISC
 SG_ Led0064_value : 504|8@1+ (1,0) [0|255] "" Vector__XXX
 SG_ Led0063_value : 496|8@1+ (1,0) [0|255] "" Vector__XXX
 SG_ Led0062_value : 488|8@1+ (1,0) [0|255] "" Vector__XXX
 SG_ Led0061_value : 480|8@1+ (1,0) [0|255] "" Vector__XXX
 SG_ Led0060_value : 472|8@1+ (1,0) [0|255] "" Vector__XXX
 SG_ Led0059_value : 464|8@1+ (1,0) [0|255] "" Vector__XXX
 SG_ Led0058_value : 456|8@1+ (1,0) [0|255] "" Vector__XXX
 SG_ Led0057_value : 448|8@1+ (1,0) [0|255] "" Vector__XXX
 SG_ Led0056_value : 440|8@1+ (1,0) [0|255] "" Vector__XXX
 SG_ Led0055_value : 432|8@1+ (1,0) [0|255] "" Vector__XXX
 SG_ Led0054_value : 424|8@1+ (1,0) [0|255] "" Vector__XXX
 SG_ Led0053_value : 416|8@1+ (1,0) [0|255] "" Vector__XXX
 SG_ Led0052_value : 408|8@1+ (1,0) [0|255] "" Vector__XXX
 SG_ Led0051_value : 400|8@1+ (1,0) [0|255] "" Vector__XXX
 SG_ Led0050_value : 392|8@1+ (1,0) [0|255] "" Vector__XXX
 SG_ Led0049_value : 384|8@1+ (1,0) [0|255] "" Vector__XXX
 SG_ Led0048_value : 376|8@1+ (1,0) [0|255] "" Vector__XXX
 SG_ Led0047_value : 368|8@1+ (1,0) [0|255] "" Vector__XXX
 SG_ Led0046_value : 360|8@1+ (1,0) [0|255] "" Vector__XXX
 SG_ Led0045_value : 352|8@1+ (1,0) [0|255] "" Vector__XXX
 SG_ Led0044_value : 344|8@1+ (1,0) [0|255] "" Vector__XXX
 SG_ Led0043_value : 336|8@1+ (1,0) [0|255] "" Vector__XXX
 SG_ Led0042_value : 328|8@1+ (1,0) [0|255] "" Vector__XXX
 SG_ Led0041_value : 320|8@1+ (1,0) [0|255] "" Vector__XXX
 SG_ Led0040_value : 312|8@1+ (1,0) [0|255] "" Vector__XXX
 SG_ Led0039_value : 304|8@1+ (1,0) [0|255] "" Vector__XXX
 SG_ Led0038_value : 296|8@1+ (1,0) [0|255] "" Vector__XXX
 SG_ Led0037_value : 288|8@1+ (1,0) [0|255] "" Vector__XXX
 SG_ Led0036_value : 280|8@1+ (1,0) [0|255] "" Vector__XXX
 SG_ Led0035_value : 272|8@1+ (1,0) [0|255] "" Vector__XXX
 SG_ Led0034_value : 264|8@1+ (1,0) [0|255] "" Vector__XXX
 SG_ Led0033_value : 256|8@1+ (1,0) [0|255] "" Vector__XXX
 SG_ Led0032_value : 248|8@1+ (1,0) [0|255] "" Vector__XXX
 SG_ Led0031_value : 240|8@1+ (1,0) [0|255] "" Vector__XXX
 SG_ Led0030_value : 232|8@1+ (1,0) [0|255] "" Vector__XXX
 SG_ Led0029_value : 224|8@1+ (1,0) [0|255] "" Vector__XXX
 SG_ Led0028_value : 216|8@1+ (1,0) [0|255] "" Vector__XXX
 SG_ Led0027_value : 208|8@1+ (1,0) [0|255] "" Vector__XXX
 SG_ Led0026_value : 200|8@1+ (1,0) [0|255] "" Vector__XXX
 SG_ Led0025_value : 192|8@1+ (1,0) [0|255] "" Vector__XXX
 SG_ Led0024_value : 184|8@1+ (1,0) [0|255] "" Vector__XXX
 SG_ Led0023_value : 176|8@1+ (1,0) [0|255] "" Vector__XXX
 SG_ Led0022_value : 168|8@1+ (1,0) [0|255] "" Vector__XXX
 SG_ Led0021_value : 160|8@1+ (1,0) [0|255] "" Vector__XXX
 SG_ Led0020_value : 152|8@1+ (1,0) [0|255] "" Vector__XXX
 SG_ Led0019_value : 144|8@1+ (1,0) [0|255] "" Vector__XXX
 SG_ Led0018_value : 136|8@1+ (1,0) [0|255] "" Vector__XXX
 SG_ Led0017_value : 128|8@1+ (1,0) [0|255] "" Vector__XXX
 SG_ Led0016_value : 120|8@1+ (1,0) [0|255] "" Vector__XXX
 SG_ Led0015_value : 112|8@1+ (1,0) [0|255] "" Vector__XXX
 SG_ Led0014_value : 104|8@1+ (1,0) [0|255] "" Vector__XXX
 SG_ Led0013_value : 96|8@1+ (1,0) [0|255] "" Vector__XXX
 SG_ Led0012_value : 88|8@1+ (1,0) [0|255] "" Vector__XXX
 SG_ Led0011_value : 80|8@1+ (1,0) [0|255] "" Vector__XXX
 SG_ Led0010_value : 72|8@1+ (1,0) [0|255] "" Vector__XXX
 SG_ Led0009_value : 64|8@1+ (1,0) [0|255] "" Vector__XXX
 SG_ Led0008_value : 56|8@1+ (1,0) [0|255] "" Vector__XXX
 SG_ Led0007_value : 48|8@1+ (1,0) [0|255] "" Vector__XXX
 SG_ Led0006_value : 40|8@1+ (1,0) [0|255] "" Vector__XXX
 SG_ Led0005_value : 32|8@1+ (1,0) [0|255] "" Vector__XXX
 SG_ Led0004_value : 24|8@1+ (1,0) [0|255] "" Vector__XXX
 SG_ Led0003_value : 16|8@1+ (1,0) [0|255] "" Vector__XXX
 SG_ Led0002_value : 8|8@1+ (1,0) [0|255] "" Vector__XXX
 SG_ Led0001_value : 0|8@1+ (1,0) [0|255] "" Vector__XXX

BO_ 769 ISC_Ctrl_Left_LED_A_01: 64 ISC
 SG_ Led0064_value : 504|8@1+ (1,0) [0|255] "" Vector__XXX
 SG_ Led0063_value : 496|8@1+ (1,0) [0|255] "" Vector__XXX
 SG_ Led0062_value : 488|8@1+ (1,0) [0|255] "" Vector__XXX
 SG_ Led0061_value : 480|8@1+ (1,0) [0|255] "" Vector__XXX
 SG_ Led0060_value : 472|8@1+ (1,0) [0|255] "" Vector__XXX
 SG_ Led0059_value : 464|8@1+ (1,0) [0|255] "" Vector__XXX
 SG_ Led0058_value : 456|8@1+ (1,0) [0|255] "" Vector__XXX
 SG_ Led0057_value : 448|8@1+ (1,0) [0|255] "" Vector__XXX
 SG_ Led0056_value : 440|8@1+ (1,0) [0|255] "" Vector__XXX
 SG_ Led0055_value : 432|8@1+ (1,0) [0|255] "" Vector__XXX
 SG_ Led0054_value : 424|8@1+ (1,0) [0|255] "" Vector__XXX
 SG_ Led0053_value : 416|8@1+ (1,0) [0|255] "" Vector__XXX
 SG_ Led0052_value : 408|8@1+ (1,0) [0|255] "" Vector__XXX
 SG_ Led0051_value : 400|8@1+ (1,0) [0|255] "" Vector__XXX
 SG_ Led0050_value : 392|8@1+ (1,0) [0|255] "" Vector__XXX
 SG_ Led0049_value : 384|8@1+ (1,0) [0|255] "" Vector__XXX
 SG_ Led0048_value : 376|8@1+ (1,0) [0|255] "" Vector__XXX
 SG_ Led0047_value : 368|8@1+ (1,0) [0|255] "" Vector__XXX
 SG_ Led0046_value : 360|8@1+ (1,0) [0|255] "" Vector__XXX
 SG_ Led0045_value : 352|8@1+ (1,0) [0|255] "" Vector__XXX
 SG_ Led0044_value : 344|8@1+ (1,0) [0|255] "" Vector__XXX
 SG_ Led0043_value : 336|8@1+ (1,0) [0|255] "" Vector__XXX
 SG_ Led0042_value : 328|8@1+ (1,0) [0|255] "" Vector__XXX
 SG_ Led0041_value : 320|8@1+ (1,0) [0|255] "" Vector__XXX
 SG_ Led0040_value : 312|8@1+ (1,0) [0|255] "" Vector__XXX
 SG_ Led0039_value : 304|8@1+ (1,0) [0|255] "" Vector__XXX
 SG_ Led0038_value : 296|8@1+ (1,0) [0|255] "" Vector__XXX
 SG_ Led0037_value : 288|8@1+ (1,0) [0|255] "" Vector__XXX
 SG_ Led0036_value : 280|8@1+ (1,0) [0|255] "" Vector__XXX
 SG_ Led0035_value : 272|8@1+ (1,0) [0|255] "" Vector__XXX
 SG_ Led0034_value : 264|8@1+ (1,0) [0|255] "" Vector__XXX
 SG_ Led0033_value : 256|8@1+ (1,0) [0|255] "" Vector__XXX
 SG_ Led0032_value : 248|8@1+ (1,0) [0|255] "" Vector__XXX
 SG_ Led0031_value : 240|8@1+ (1,0) [0|255] "" Vector__XXX
 SG_ Led0030_value : 232|8@1+ (1,0) [0|255] "" Vector__XXX
 SG_ Led0029_value : 224|8@1+ (1,0) [0|255] "" Vector__XXX
 SG_ Led0028_value : 216|8@1+ (1,0) [0|255] "" Vector__XXX
 SG_ Led0027_value : 208|8@1+ (1,0) [0|255] "" Vector__XXX
 SG_ Led0026_value : 200|8@1+ (1,0) [0|255] "" Vector__XXX
 SG_ Led0025_value : 192|8@1+ (1,0) [0|255] "" Vector__XXX
 SG_ Led0024_value : 184|8@1+ (1,0) [0|255] "" Vector__XXX
 SG_ Led0023_value : 176|8@1+ (1,0) [0|255] "" Vector__XXX
 SG_ Led0022_value : 168|8@1+ (1,0) [0|255] "" Vector__XXX
 SG_ Led0021_value : 160|8@1+ (1,0) [0|255] "" Vector__XXX
 SG_ Led0020_value : 152|8@1+ (1,0) [0|255] "" Vector__XXX
 SG_ Led0019_value : 144|8@1+ (1,0) [0|255] "" Vector__XXX
 SG_ Led0018_value : 136|8@1+ (1,0) [0|255] "" Vector__XXX
 SG_ Led0017_value : 128|8@1+ (1,0) [0|255] "" Vector__XXX
 SG_ Led0016_value : 120|8@1+ (1,0) [0|255] "" Vector__XXX
 SG_ Led0015_value : 112|8@1+ (1,0) [0|255] "" Vector__XXX
 SG_ Led0014_value : 104|8@1+ (1,0) [0|255] "" Vector__XXX
 SG_ Led0013_value : 96|8@1+ (1,0) [0|255] "" Vector__XXX
 SG_ Led0012_value : 88|8@1+ (1,0) [0|255] "" Vector__XXX
 SG_ Led0011_value : 80|8@1+ (1,0) [0|255] "" Vector__XXX
 SG_ Led0010_value : 72|8@1+ (1,0) [0|255] "" Vector__XXX
 SG_ Led0009_value : 64|8@1+ (1,0) [0|255] "" Vector__XXX
 SG_ Led0008_value : 56|8@1+ (1,0) [0|255] "" Vector__XXX
 SG_ Led0007_value : 48|8@1+ (1,0) [0|255] "" Vector__XXX
 SG_ Led0006_value : 40|8@1+ (1,0) [0|255] "" Vector__XXX
 SG_ Led0005_value : 32|8@1+ (1,0) [0|255] "" Vector__XXX
 SG_ Led0004_value : 24|8@1+ (1,0) [0|255] "" Vector__XXX
 SG_ Led0003_value : 16|8@1+ (1,0) [0|255] "" Vector__XXX
 SG_ Led0002_value : 8|8@1+ (1,0) [0|255] "" Vector__XXX
 SG_ Led0001_value : 0|8@1+ (1,0) [0|255] "" Vector__XXX

BO_ 255 ISC_Ctrl: 8 ISC
 SG_ Color_mode : 8|1@1+ (1,0) [0|1] "" Vector__XXX
 SG_ Responses_cmd : 0|2@1+ (1,0) [0|3] "" Vector__XXX

EV_ pixel_coord_B: 0 [0|0] "" 0 1 DUMMY_NODE_VECTOR0 Vector__XXX;

EV_ pixel_coord_RA: 0 [0|0] "" 0 2 DUMMY_NODE_VECTOR0 Vector__XXX;

EV_ pixel_coord_LA: 0 [0|0] "" 0 3 DUMMY_NODE_VECTOR0 Vector__XXX;
ENVVAR_DATA_ pixel_coord_B: 2000;
ENVVAR_DATA_ pixel_coord_RA: 100;
ENVVAR_DATA_ pixel_coord_LA: 100;
CM_ BO_ 1680 "后左A灯 的LED Driver反馈帧";
CM_ SG_ 1680 C_Led_Fault "C灯故障";
CM_ SG_ 1680 Led_Driver_Internal_Fault "LED Driver内部故障";
CM_ SG_ 1680 Led_Driver_High_Temp_Fault "LED Driver高温故障";
CM_ SG_ 1680 Led_Driver_Low_Voltage_Fault "LED Driver低压故障";
CM_ SG_ 1680 Led_Driver_High_Voltage_Fault "LED Driver高压故障";
CM_ SG_ 1680 Break_Sts "刹车灯信号状态";
CM_ SG_ 1680 Turn_Sts "转向灯信号状态";
CM_ SG_ 1680 Led_Driver_WorkSts "LED Driver工作状态";
CM_ BO_ 1285 "ISC控制后右A灯257~299 灰度信息帧";
CM_ BO_ 1284 "ISC控制后右A灯193~256 灰度信息帧";
CM_ BO_ 1283 "ISC控制后右A灯129~192 灰度信息帧";
CM_ BO_ 1282 "ISC控制后右A灯65~128 灰度信息帧";
CM_ BO_ 1281 "ISC控制后右A灯1~64 灰度信息帧";
CM_ BO_ 1063 "ISC控制后B灯2433~2463 灰度信息帧";
CM_ BO_ 1062 "ISC控制后B灯2369~2432 灰度信息帧";
CM_ BO_ 1061 "ISC控制后B灯2305~2368 灰度信息帧";
CM_ BO_ 1060 "ISC控制后B灯2241~2304 灰度信息帧";
CM_ BO_ 1059 "ISC控制后B灯2177~2240 灰度信息帧";
CM_ BO_ 1058 "ISC控制后B灯2113~2176 灰度信息帧";
CM_ BO_ 1057 "ISC控制后B灯2049~2112 灰度信息帧";
CM_ BO_ 1056 "ISC控制后B灯1985~2048 灰度信息帧";
CM_ BO_ 1055 "ISC控制后B灯1921~1984 灰度信息帧";
CM_ BO_ 1054 "ISC控制后B灯1857~1920 灰度信息帧";
CM_ BO_ 1053 "ISC控制后B灯1793~1856 灰度信息帧";
CM_ BO_ 1052 "ISC控制后B灯1729~1792 灰度信息帧";
CM_ BO_ 1051 "ISC控制后B灯1665~1728 灰度信息帧";
CM_ BO_ 1050 "ISC控制后B灯1601~1664 灰度信息帧";
CM_ BO_ 1049 "ISC控制后B灯1537~1600 灰度信息帧";
CM_ BO_ 1048 "ISC控制后B灯1473~1536 灰度信息帧";
CM_ BO_ 1047 "ISC控制后B灯1409~1472 灰度信息帧";
CM_ BO_ 1046 "ISC控制后B灯1345~1408 灰度信息帧";
CM_ BO_ 1045 "ISC控制后B灯1281~1344 灰度信息帧";
CM_ BO_ 1044 "ISC控制后B灯1217~1280 灰度信息帧";
CM_ BO_ 1043 "ISC控制后B灯1153~1216 灰度信息帧";
CM_ BO_ 1042 "ISC控制后B灯1089~1152 灰度信息帧";
CM_ BO_ 1041 "ISC控制后B灯1025~1088 灰度信息帧";
CM_ BO_ 1040 "ISC控制后B灯961~1024 灰度信息帧";
CM_ BO_ 1039 "ISC控制后B灯897~960 灰度信息帧";
CM_ BO_ 1038 "ISC控制后B灯833~896 灰度信息帧";
CM_ BO_ 1037 "ISC控制后B灯769~832 灰度信息帧";
CM_ BO_ 1036 "ISC控制后B灯705~768 灰度信息帧";
CM_ BO_ 1035 "ISC控制后B灯641~704 灰度信息帧";
CM_ BO_ 1034 "ISC控制后B灯577~640 灰度信息帧";
CM_ BO_ 1033 "ISC控制后B灯513~576 灰度信息帧";
CM_ BO_ 1032 "ISC控制后B灯449~512 灰度信息帧";
CM_ BO_ 1031 "ISC控制后B灯385~448 灰度信息帧";
CM_ BO_ 1030 "ISC控制后B灯321~384 灰度信息帧";
CM_ BO_ 1029 "ISC控制后B灯257~320 灰度信息帧";
CM_ BO_ 1028 "ISC控制后B灯192~256 灰度信息帧";
CM_ BO_ 1027 "ISC控制后B灯129~192 灰度信息帧";
CM_ BO_ 1026 "ISC控制后B灯65~128 灰度信息帧";
CM_ BO_ 1025 "ISC控制后B灯1~64 灰度信息帧";
CM_ BO_ 773 "ISC控制后左A灯257~299 灰度信息帧";
CM_ BO_ 772 "ISC控制后左A灯193~256 灰度信息帧";
CM_ BO_ 771 "ISC控制后左A灯129~192 灰度信息帧";
CM_ BO_ 770 "ISC控制后左A灯65~128 灰度信息帧";
CM_ BO_ 769 "ISC控制后左A灯1~64 灰度信息帧";
CM_ BO_ 255 "ISC控制命令帧";
CM_ SG_ 255 Color_mode "颜色模式";
CM_ SG_ 255 Responses_cmd "响应方式";
BA_DEF_ BO_  "CANFD_BRS" ENUM  "0","1";
BA_DEF_ BO_  "VFrameFormat" ENUM  "StandardCAN","ExtendedCAN","reserved","reserved","reserved","reserved","reserved","reserved","reserved","reserved","reserved","reserved","reserved","reserved","StandardCAN_FD","ExtendedCAN_FD";
BA_DEF_DEF_  "CANFD_BRS" "1";
BA_DEF_DEF_  "VFrameFormat" "StandardCAN";
BA_ "VFrameFormat" BO_ 1680 14;
BA_ "VFrameFormat" BO_ 1285 14;
BA_ "VFrameFormat" BO_ 1284 14;
BA_ "VFrameFormat" BO_ 1283 14;
BA_ "VFrameFormat" BO_ 1282 14;
BA_ "VFrameFormat" BO_ 1281 14;
BA_ "VFrameFormat" BO_ 1063 14;
BA_ "VFrameFormat" BO_ 1062 14;
BA_ "VFrameFormat" BO_ 1061 14;
BA_ "VFrameFormat" BO_ 1060 14;
BA_ "VFrameFormat" BO_ 1059 14;
BA_ "VFrameFormat" BO_ 1058 14;
BA_ "VFrameFormat" BO_ 1057 14;
BA_ "VFrameFormat" BO_ 1056 14;
BA_ "VFrameFormat" BO_ 1055 14;
BA_ "VFrameFormat" BO_ 1054 14;
BA_ "VFrameFormat" BO_ 1053 14;
BA_ "VFrameFormat" BO_ 1052 14;
BA_ "VFrameFormat" BO_ 1051 14;
BA_ "VFrameFormat" BO_ 1050 14;
BA_ "VFrameFormat" BO_ 1049 14;
BA_ "VFrameFormat" BO_ 1048 14;
BA_ "VFrameFormat" BO_ 1047 14;
BA_ "VFrameFormat" BO_ 1046 14;
BA_ "VFrameFormat" BO_ 1045 14;
BA_ "VFrameFormat" BO_ 1044 14;
BA_ "VFrameFormat" BO_ 1043 14;
BA_ "VFrameFormat" BO_ 1042 14;
BA_ "VFrameFormat" BO_ 1041 14;
BA_ "VFrameFormat" BO_ 1040 14;
BA_ "VFrameFormat" BO_ 1039 14;
BA_ "VFrameFormat" BO_ 1038 14;
BA_ "VFrameFormat" BO_ 1037 14;
BA_ "VFrameFormat" BO_ 1036 14;
BA_ "VFrameFormat" BO_ 1035 14;
BA_ "VFrameFormat" BO_ 1034 14;
BA_ "VFrameFormat" BO_ 1033 14;
BA_ "VFrameFormat" BO_ 1032 14;
BA_ "VFrameFormat" BO_ 1031 14;
BA_ "VFrameFormat" BO_ 1030 14;
BA_ "VFrameFormat" BO_ 1029 14;
BA_ "VFrameFormat" BO_ 1028 14;
BA_ "VFrameFormat" BO_ 1027 14;
BA_ "VFrameFormat" BO_ 1026 14;
BA_ "VFrameFormat" BO_ 1025 14;
BA_ "VFrameFormat" BO_ 773 14;
BA_ "VFrameFormat" BO_ 772 14;
BA_ "VFrameFormat" BO_ 771 14;
BA_ "VFrameFormat" BO_ 770 14;
BA_ "VFrameFormat" BO_ 769 14;
BA_ "VFrameFormat" BO_ 255 14;
VAL_ 1680 C_Led_Fault 1 "fault" 0 "normal" ;
VAL_ 1680 Led_Driver_Internal_Fault 1 "fault" 0 "normal" ;
VAL_ 1680 Led_Driver_High_Temp_Fault 1 "fault" 0 "normal" ;
VAL_ 1680 Led_Driver_Low_Voltage_Fault 1 "fault" 0 "normal" ;
VAL_ 1680 Led_Driver_High_Voltage_Fault 1 "fault" 0 "normal" ;
VAL_ 1680 Break_Sts 1 "Available" 0 "Inavailable" ;
VAL_ 1680 Turn_Sts 1 "Available" 0 "Inavailable" ;
VAL_ 1680 Led_Driver_WorkSts 3 "Swtched_Off_due_to_Error" 2 "Switched_On_but_Derating" 1 "Switched_On_Normal" 0 "Switched_Off" ;
VAL_ 255 Color_mode 1 "双色" 0 "正常" ;
VAL_ 255 Responses_cmd 3 "Reserved_3" 2 "Reserved_2" 1 "响应硬线信号" 0 "响应ISC控制信号" ;
